VERSION "dbc-export 1 2025.20.8"

NS_ :

BS_:

BU_: ADSP APB APP APS APSB BB BMS CC CMP CMPD CP DAS DI DIF DIR DPB EPAS3P EPAS3S EPASTP EPASTS EPBL EPBR ESP EVSE FC GTW HCML HCMR HVP IBST ICR IDB LS OCS1P PARK PCS PM PMF PMR PNCD PTC RADC RCM RCM2 RCM3 RCU SCCM SCM SCS SDCR TAS TCU TPMS TRCM UI UIS UMC USM VC VCFRONT VCLEFT VCRIGHT VCSEC VEH

BO_ 548 PCS_dcdcStatus: 8 PCS
 SG_ PCS_dcdcPrechargeStatus : 0|2@1+ (1,0) [0|3] "" Vector__XXX
 SG_ PCS_dcdcLvSupportStatus : 2|2@1+ (1,0) [0|3] "" Vector__XXX
 SG_ PCS_dcdcHvBusDischargeStatus : 4|2@1+ (1,0) [0|3] "" Vector__XXX
 SG_ PCS_coldSleepAllowed : 8|1@1+ (1,0) [0|1] "" Vector__XXX
 SG_ PCS_dcdcPchgHVBusLowRDetected : 9|1@1+ (1,0) [0|1] "" Vector__XXX
 SG_ PCS_dcdcSubState : 10|5@1+ (1,0) [0|31] "" Vector__XXX
 SG_ PCS_dcdcFaulted : 15|1@1+ (1,0) [0|1] "" Vector__XXX
 SG_ PCS_okToBePowerCycled : 27|1@1+ (1,0) [0|1] "" Vector__XXX
 SG_ PCS_dcdcOutputIsLimited : 28|1@1+ (1,0) [0|1] "" Vector__XXX
 SG_ PCS_dcdcMaxOutputCurrentAllowed : 29|12@1+ (0.1,0) [0|400] "A" Vector__XXX
 SG_ PCS_dcdcPrechargeRtyCnt : 41|3@1+ (1,0) [0|7] "" Vector__XXX
 SG_ PCS_dcdcLvSupportRtyCnt : 44|4@1+ (1,0) [0|15] "" Vector__XXX
 SG_ PCS_dcdcDischargeRtyCnt : 48|4@1+ (1,0) [0|15] "" Vector__XXX
 SG_ PCS_dcdcPwmEnableLine : 52|1@1+ (1,0) [0|1] "" Vector__XXX
 SG_ PCS_dcdcSupportingFixedLvTarget : 53|1@1+ (1,0) [0|1] "" Vector__XXX
 SG_ PCS_ecuLogUploadRequest : 54|2@1+ (1,0) [0|3] "" Vector__XXX
 SG_ PCS_dcdcPrechargeRestartCnt : 56|3@1+ (1,0) [0|7] "" Vector__XXX
 SG_ PCS_dcdcInitialPrechargeSubState : 59|5@1+ (1,0) [0|31] "" Vector__XXX

BO_ 964 PCS_info: 8 PCS
 SG_ PCS_infoIndex M : 0|8@1+ (1,0) [0|255] "" Vector__XXX
 SG_ PCS_buildType m10 : 8|8@1+ (1,0) [0|255] "" Vector__XXX
 SG_ PCS_buildConfigId m10 : 16|16@1+ (1,0) [0|65535] "" Vector__XXX
 SG_ PCS_hardwareId m10 : 32|16@1+ (1,0) [0|65535] "" Vector__XXX
 SG_ PCS_componentId m10 : 48|16@1+ (1,0) [0|65535] "" Vector__XXX
 SG_ PCS_pcbaId m11 : 16|8@1+ (1,0) [0|255] "" Vector__XXX
 SG_ PCS_assemblyId m11 : 24|8@1+ (1,0) [0|255] "" Vector__XXX
 SG_ PCS_usageId m11 : 32|16@1+ (1,0) [0|65535] "" Vector__XXX
 SG_ PCS_subUsageId m11 : 48|16@1+ (1,0) [0|65535] "" Vector__XXX
 SG_ PCS_platformType m13 : 8|8@1+ (1,0) [0|255] "" Vector__XXX
 SG_ PCS_appCrc m13 : 32|32@1+ (1,0) [0|4294967295] "" Vector__XXX
 SG_ PCS_cpu2AppCrc m16 : 32|32@1+ (1,0) [0|4294967295] "" Vector__XXX
 SG_ PCS_appGitHash m17 : 8|56@1+ (1,0) [0|7.20575940379e+16] "" Vector__XXX
 SG_ PCS_bootGitHash m18 : 8|56@1+ (1,0) [0|7.20575940379e+16] "" Vector__XXX
 SG_ PCS_bootUdsProtoVersion m20 : 8|8@1+ (1,0) [0|255] "" Vector__XXX
 SG_ PCS_bootCrc m20 : 32|32@1+ (1,0) [0|4294967295] "" Vector__XXX

BO_ 708 PCS_logging: 8 PCS
 SG_ PCS_logMessageSelect M : 0|5@1+ (1,0) [0|31] "" Vector__XXX
 SG_ PCS_chgPhAInputIrms m0 : 5|9@1+ (0.1,0) [0|51.1] "A" Vector__XXX
 SG_ PCS_chgPhAIntBusV m0 : 14|9@1+ (1,0) [0|511] "V" Vector__XXX
 SG_ PCS_chgPhAIntBusVTarget m0 : 23|9@1+ (1,0) [0|511] "V" Vector__XXX
 SG_ PCS_chgPhAOutputI m0 : 32|8@1+ (0.1,0) [0|25.5] "A" Vector__XXX
 SG_ PCS_chgPhAInputCurrentLimitReaso m0 : 40|3@1+ (1,0) [0|7] "" Vector__XXX
 SG_ PCS_chgPhBInputIrms m1 : 5|9@1+ (0.1,0) [0|51.1] "A" Vector__XXX
 SG_ PCS_chgPhBIntBusV m1 : 14|9@1+ (1,0) [0|511] "V" Vector__XXX
 SG_ PCS_chgPhBIntBusVTarget m1 : 23|9@1+ (1,0) [0|511] "V" Vector__XXX
 SG_ PCS_chgPhBOutputI m1 : 32|8@1+ (0.1,0) [0|25.5] "A" Vector__XXX
 SG_ PCS_chgPhBInputCurrentLimitReaso m1 : 40|3@1+ (1,0) [0|7] "" Vector__XXX
 SG_ PCS_chgPhCInputIrms m2 : 5|9@1+ (0.1,0) [0|51.1] "A" Vector__XXX
 SG_ PCS_chgPhCIntBusV m2 : 14|9@1+ (1,0) [0|511] "V" Vector__XXX
 SG_ PCS_chgPhCIntBusVTarget m2 : 23|9@1+ (1,0) [0|511] "V" Vector__XXX
 SG_ PCS_chgPhCOutputI m2 : 32|8@1+ (0.1,0) [0|25.5] "A" Vector__XXX
 SG_ PCS_chgPhCInputCurrentLimitReaso m2 : 40|3@1+ (1,0) [0|7] "" Vector__XXX
 SG_ PCS_chgInputL1NVrms m3 : 5|12@1+ (0.2,0) [0|819] "V" Vector__XXX
 SG_ PCS_chgInputL2NVrms m3 : 17|12@1+ (0.2,0) [0|819] "V" Vector__XXX
 SG_ PCS_chgInputL3NVrms m3 : 29|12@1+ (0.2,0) [0|819] "V" Vector__XXX
 SG_ PCS_chgInputL1L2Vrms m3 : 41|12@1+ (0.2,0) [0|819] "V" Vector__XXX
 SG_ PCS_chgInputNGVrms m3 : 53|9@1+ (1,0) [0|511] "V" Vector__XXX
 SG_ PCS_chgInputFrequencyL1N m4 : 5|12@1+ (0.01,40) [40|80.95] "Hz" Vector__XXX
 SG_ PCS_chgInputFrequencyL2N m4 : 17|12@1+ (0.01,40) [40|80.95] "Hz" Vector__XXX
 SG_ PCS_chgInputFrequencyL3N m4 : 29|12@1+ (0.01,40) [40|80.95] "Hz" Vector__XXX
 SG_ PCS_chgInternalPhaseConfig m4 : 41|4@1+ (1,0) [0|15] "" Vector__XXX
 SG_ PCS_chgPhasesPriority m4 : 45|6@1+ (1,0) [0|63] "" Vector__XXX
 SG_ PCS_chgOutputV m4 : 51|12@1+ (0.146484375,0) [0|599.853515625] "V" Vector__XXX
 SG_ PCS_chgPhAState m5 : 5|4@1+ (1,0) [0|15] "" Vector__XXX
 SG_ PCS_chgPhBState m5 : 9|4@1+ (1,0) [0|15] "" Vector__XXX
 SG_ PCS_chgPhCState m5 : 13|4@1+ (1,0) [0|15] "" Vector__XXX
 SG_ PCS_chgPhALastShutdownReason m5 : 17|5@1+ (1,0) [0|31] "" Vector__XXX
 SG_ PCS_chgPhBLastShutdownReason m5 : 22|5@1+ (1,0) [0|31] "" Vector__XXX
 SG_ PCS_chgPhCLastShutdownReason m5 : 27|5@1+ (1,0) [0|31] "" Vector__XXX
 SG_ PCS_chgPhARetryCount m5 : 32|3@1+ (1,0) [0|7] "" Vector__XXX
 SG_ PCS_chgPhBRetryCount m5 : 35|3@1+ (1,0) [0|7] "" Vector__XXX
 SG_ PCS_chgPhCRetryCount m5 : 38|3@1+ (1,0) [0|7] "" Vector__XXX
 SG_ PCS_chgRetryCount m5 : 41|3@1+ (1,0) [0|7] "" Vector__XXX
 SG_ PCS_chgPhManCurrentToDist m5 : 44|10@1+ (0.1,0) [0|100] "A" Vector__XXX
 SG_ PCS_chgL1NPllLocked m5 : 54|1@1+ (1,0) [0|1] "" Vector__XXX
 SG_ PCS_chgL2NPllLocked m5 : 55|1@1+ (1,0) [0|1] "" Vector__XXX
 SG_ PCS_chgL3NPllLocked m5 : 56|1@1+ (1,0) [0|1] "" Vector__XXX
 SG_ PCS_chgL1L2PllLocked m5 : 57|1@1+ (1,0) [0|1] "" Vector__XXX
 SG_ PCS_chgNgPllLocked m5 : 58|1@1+ (1,0) [0|1] "" Vector__XXX
 SG_ PCS_chgPhManOptimalPhsToUse m5 : 59|2@1+ (1,0) [0|3] "" Vector__XXX
 SG_ PCS_chg5VL1Enable m5 : 61|1@1+ (1,0) [0|1] "" Vector__XXX
 SG_ PCS_dcdcMaxLvOutputCurrent m6 : 8|12@1+ (0.1,0) [0|400] "A" Vector__XXX
 SG_ PCS_dcdcCurrentLimit m6 : 20|12@1+ (0.1,0) [0|400] "A" Vector__XXX
 SG_ PCS_dcdcLvOutputCurrentTempLimit m6 : 32|12@1+ (0.1,0) [0|400] "A" Vector__XXX
 SG_ PCS_dcdcLvOutputCurrentFiltered m6 : 44|12@1+ (0.1,0) [0|400] "A" Vector__XXX
 SG_ PCS_dcdcUnifiedCommand m7 : 5|10@1+ (0.001,0) [0|1] "1" Vector__XXX
 SG_ PCS_dcdcCLAControllerOutput m7 : 16|10@1+ (0.001,0) [0|1] "1" Vector__XXX
 SG_ PCS_dcdcTankVoltage m7 : 26|11@1- (1,0) [-1024|1023] "V" Vector__XXX
 SG_ PCS_dcdcTankVoltageTarget m7 : 37|10@1+ (1,0) [0|1023] "V" Vector__XXX
 SG_ PCS_dcdcClaCurrentFreq m7 : 48|12@1+ (0.09765625,0) [0|399.9] "kHz" Vector__XXX
 SG_ PCS_dcdcTCommMeasured m8 : 5|16@1- (0.001953125,0) [-64|63.998] "us" Vector__XXX
 SG_ PCS_dcdcShortTimeUs m8 : 21|16@1+ (0.00048828125,0) [0|31.9995] "us" Vector__XXX
 SG_ PCS_dcdcHalfPeriodUs m8 : 37|16@1+ (0.00048828125,0) [0|31.9995] "us" Vector__XXX
 SG_ PCS_dcdcLvBusVoltTargetWithOffse m8 : 53|11@1+ (0.01,0) [0|20] "V" Vector__XXX
 SG_ PCS_cpu2BootState m9 : 5|2@1+ (1,0) [0|3] "" Vector__XXX
 SG_ PCS_acChargeSelfTestState m9 : 7|1@1+ (1,0) [0|1] "" Vector__XXX
 SG_ PCS_1V5Min10s m9 : 8|11@1+ (0.001,0) [0|2.047] "V" Vector__XXX
 SG_ PCS_1V5Max10s m9 : 19|11@1+ (0.001,0) [0|2.047] "V" Vector__XXX
 SG_ PCS_1V2Min10s m9 : 32|11@1+ (0.001,0) [0|2.047] "V" Vector__XXX
 SG_ PCS_1V2Max10s m9 : 43|11@1+ (0.001,0) [0|2.047] "V" Vector__XXX
 SG_ PCS_5VNMax10s m9 : 54|10@1+ (0.01,0) [0|10.23] "V" Vector__XXX
 SG_ PCS_chgPhAIntBusVMin10s m10 : 5|9@1+ (1,0) [0|511] "V" Vector__XXX
 SG_ PCS_chgPhAIntBusVMax10s m10 : 14|9@1+ (1,0) [0|511] "V" Vector__XXX
 SG_ PCS_chgPhAPchgVoltDeltaMax10s m10 : 23|8@1+ (0.5,0) [0|127.5] "V" Vector__XXX
 SG_ PCS_chgPhALifetimekWh m10 : 31|24@1+ (0.01,0) [0|167772.15] "kWh" Vector__XXX
 SG_ PCS_chgPhATransientRetryCount m10 : 55|9@1+ (0.1,0) [0|51.1] "-" Vector__XXX
 SG_ PCS_chgPhBIntBusVMin10s m11 : 5|9@1+ (1,0) [0|511] "V" Vector__XXX
 SG_ PCS_chgPhBIntBusVMax10s m11 : 14|9@1+ (1,0) [0|511] "V" Vector__XXX
 SG_ PCS_chgPhBPchgVoltDeltaMax10s m11 : 23|8@1+ (0.5,0) [0|127.5] "V" Vector__XXX
 SG_ PCS_chgPhBLifetimekWh m11 : 31|24@1+ (0.01,0) [0|167772.15] "kWh" Vector__XXX
 SG_ PCS_chgPhBTransientRetryCount m11 : 55|9@1+ (0.1,0) [0|51.1] "-" Vector__XXX
 SG_ PCS_chgPhCIntBusVMin10s m12 : 5|9@1+ (1,0) [0|511] "V" Vector__XXX
 SG_ PCS_chgPhCIntBusVMax10s m12 : 14|9@1+ (1,0) [0|511] "V" Vector__XXX
 SG_ PCS_chgPhCPchgVoltDeltaMax10s m12 : 23|8@1+ (0.5,0) [0|127.5] "V" Vector__XXX
 SG_ PCS_chgPhCLifetimekWh m12 : 31|24@1+ (0.01,0) [0|167772.15] "kWh" Vector__XXX
 SG_ PCS_chgPhCTransientRetryCount m12 : 55|9@1+ (0.1,0) [0|51.1] "-" Vector__XXX
 SG_ PCS_chgPhANoFlowBucket m20 : 5|9@1+ (0.01,0) [0|5.11] "-" Vector__XXX
 SG_ PCS_chgPhBNoFlowBucket m20 : 14|9@1+ (0.01,0) [0|5.11] "-" Vector__XXX
 SG_ PCS_chgPhCNoFlowBucket m20 : 23|9@1+ (0.01,0) [0|5.11] "-" Vector__XXX
 SG_ PCS_chgCurrentSensorOutOfBandUs m20 : 32|10@1+ (0.01,0) [0|10.23] "us" Vector__XXX
 SG_ PCS_chgAcpwHeartbeatState m20 : 42|3@1+ (1,0) [0|7] "" Vector__XXX
 SG_ PCS_chgKwhLostByFreqDroop m20 : 48|8@1+ (0.1,0) [0|25.5] "kWh" Vector__XXX
 SG_ PCS_chgReqKwhLostByFreqDroop m20 : 56|8@1+ (0.1,0) [0|25.5] "kWh" Vector__XXX
 SG_ PCS_dcdcLvSupportLifetimekWh m22 : 8|24@1+ (0.01,0) [0|167772.15] "kWh" Vector__XXX
 SG_ PCS_chgPwmEnableLineErrorCount m22 : 32|10@1+ (1,0) [0|1023] "" Vector__XXX
 SG_ PCS_dcdcPwmEnableLineErrorCount m22 : 42|10@1+ (1,0) [0|1023] "" Vector__XXX
 SG_ PCS_numAlertsSet m22 : 56|7@1+ (1,0) [0|127] "" Vector__XXX
 SG_ PCS_dcdcPchgStartLvBusVolt m24 : 5|10@1+ (0.0390625,0) [0|39.9609375] "V" Vector__XXX
 SG_ PCS_dcdcPchgStartHvBusVolt m24 : 16|12@1+ (0.146484375,0) [0|599.853515625] "V" Vector__XXX
 SG_ PCS_processorDieIdLot m26 : 8|24@1+ (1,0) [0|16777215] "" Vector__XXX
 SG_ PCS_processorDieIdWafer m26 : 32|8@1+ (1,0) [0|255] "" Vector__XXX
 SG_ PCS_processorDieIdX m26 : 40|12@1+ (1,0) [0|4095] "" Vector__XXX
 SG_ PCS_processorDieIdY m26 : 52|12@1+ (1,0) [0|4095] "" Vector__XXX

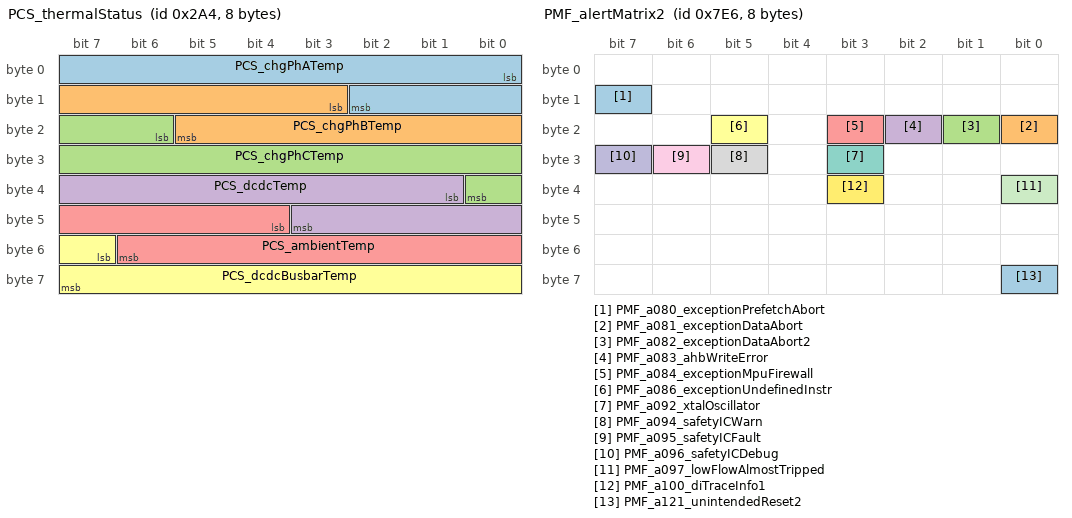
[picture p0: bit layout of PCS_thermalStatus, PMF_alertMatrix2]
BO_ 676 PCS_thermalStatus: 8 PCS
 SG_ PCS_chgPhATemp : 0|11@1- (0.1,40) [-62.4|142.3] "C" Vector__XXX
 SG_ PCS_chgPhBTemp : 11|11@1- (0.1,40) [-62.4|142.3] "C" Vector__XXX
 SG_ PCS_chgPhCTemp : 22|11@1- (0.1,40) [-62.4|142.3] "C" Vector__XXX
 SG_ PCS_dcdcTemp : 33|11@1- (0.1,40) [-62.4|142.3] "C" Vector__XXX
 SG_ PCS_ambientTemp : 44|11@1- (0.1,40) [-62.4|142.3] "C" Vector__XXX
 SG_ PCS_dcdcBusbarTemp : 55|9@1+ (0.2935421,0) [0|150] "C" Vector__XXX

BO_ 1317 PMF_alertLog: 8 PMF
 SG_ PMF_alertID M : 0|7@1+ (1,0) [0|127] "" Vector__XXX
 SG_ PMF_alertState : 15|1@1+ (1,0) [0|1] "" Vector__XXX
 SG_ PMF_a001_w0 m1 : 16|16@1+ (1,0) [0|65535] "" Vector__XXX
 SG_ PMF_a001_w1 m1 : 32|16@1+ (1,0) [0|65535] "" Vector__XXX
 SG_ PMF_a001_w2 m1 : 48|16@1+ (1,0) [0|65535] "" Vector__XXX
 SG_ PMF_a002_torqueAverage m2 : 16|1@1+ (1,0) [0|1] "" Vector__XXX
 SG_ PMF_a002_torqueWindow m2 : 17|1@1+ (1,0) [0|1] "" Vector__XXX
 SG_ PMF_a002_torqueMeasured m2 : 18|13@1- (2,0) [-8192|8190] "" Vector__XXX
 SG_ PMF_a002_torqueAccelAverage m2 : 32|13@1- (2,0) [-8192|8190] "" Vector__XXX
 SG_ PMF_a002_torqueAccelWindow m2 : 48|13@1- (2,0) [-8192|8190] "" Vector__XXX
 SG_ PMF_a003_reverseGear m3 : 16|1@1+ (1,0) [0|1] "" Vector__XXX
 SG_ PMF_a003_pedalPos m3 : 24|8@1+ (0.4,0) [0|102] "" Vector__XXX
 SG_ PMF_a003_zeroPointPedal m3 : 32|8@1+ (0.4,0) [0|102] "" Vector__XXX
 SG_ PMF_a004_torqueAverage m4 : 16|1@1+ (1,0) [0|1] "" Vector__XXX
 SG_ PMF_a004_torqueWindow m4 : 17|1@1+ (1,0) [0|1] "" Vector__XXX
 SG_ PMF_a004_torqueMeasured m4 : 18|13@1- (2,0) [-8192|8190] "" Vector__XXX
 SG_ PMF_a004_torqueDecelAverage m4 : 32|13@1- (2,0) [-8192|8190] "" Vector__XXX
 SG_ PMF_a004_torqueDecelWindow m4 : 48|13@1- (2,0) [-8192|8190] "" Vector__XXX
 SG_ PMF_a005_torqueReason m5 : 16|2@1+ (1,0) [0|3] "" Vector__XXX
 SG_ PMF_a005_torqueMeasured m5 : 18|13@1- (2,0) [-8192|8190] "" Vector__XXX
 SG_ PMF_a005_iDQmagnitude m5 : 32|16@1- (0.0939,0) [-3076.9152|3076.8213] "" Vector__XXX
 SG_ PMF_a006_torqueActual m6 : 16|13@1- (2,0) [-8192|8190] "" Vector__XXX
 SG_ PMF_a006_motorRPM m6 : 32|16@1- (1,0) [-32768|32767] "" Vector__XXX
 SG_ PMF_a006_torqueMeasured m6 : 48|13@1- (2,0) [-8192|8190] "" Vector__XXX
 SG_ PMF_a010_messageId m10 : 16|16@1+ (1,0) [0|65535] "" Vector__XXX
 SG_ PMF_a010_DI_status m10 : 32|1@1+ (1,0) [0|1] "" Vector__XXX
 SG_ PMF_a010_DI_torque m10 : 33|1@1+ (1,0) [0|1] "" Vector__XXX
 SG_ PMF_a010_DI_slaveCommand m10 : 34|1@1+ (1,0) [0|1] "" Vector__XXX
 SG_ PMF_a010_DI_locStatus m10 : 35|1@1+ (1,0) [0|1] "" Vector__XXX
 SG_ PMF_a010_DI_speed m10 : 36|1@1+ (1,0) [0|1] "" Vector__XXX
 SG_ PMF_a010_DI_systemStatus m10 : 37|1@1+ (1,0) [0|1] "" Vector__XXX
 SG_ PMF_a010_DI_chassisControl m10 : 38|1@1+ (1,0) [0|1] "" Vector__XXX
 SG_ PMF_a010_DI_chassisControl2 m10 : 39|1@1+ (1,0) [0|1] "" Vector__XXX
 SG_ PMF_a010_vdcLeft m10 : 40|1@1+ (1,0) [0|1] "" Vector__XXX
 SG_ PMF_a010_vdcRight m10 : 41|1@1+ (1,0) [0|1] "" Vector__XXX
 SG_ PMF_a010_DI_vehicleEstimates m10 : 42|1@1+ (1,0) [0|1] "" Vector__XXX
 SG_ PMF_a010_DI_brakeCommand m10 : 43|1@1+ (1,0) [0|1] "" Vector__XXX
 SG_ PMF_a010_DI_difCommand m10 : 44|1@1+ (1,0) [0|1] "" Vector__XXX
 SG_ PMF_a010_DI_dirCommand m10 : 45|1@1+ (1,0) [0|1] "" Vector__XXX
 SG_ PMF_a010_DI_dirVehicle m10 : 46|1@1+ (1,0) [0|1] "" Vector__XXX
 SG_ PMF_a010_DI_locStatus2 m10 : 47|1@1+ (1,0) [0|1] "" Vector__XXX
 SG_ PMF_a011_Ia m11 : 16|16@1- (0.0939,0) [-3076.9152|3076.8213] "" Vector__XXX
 SG_ PMF_a011_Ib m11 : 32|16@1- (0.0939,0) [-3076.9152|3076.8213] "" Vector__XXX
 SG_ PMF_a011_currentVref m11 : 48|11@1+ (0.005,0) [0|10.235] "" Vector__XXX
 SG_ PMF_a011_badPhaseAsample m11 : 59|1@1+ (1,0) [0|1] "" Vector__XXX
 SG_ PMF_a011_badPhaseBsample m11 : 60|1@1+ (1,0) [0|1] "" Vector__XXX
 SG_ PMF_a011_sampleFreeze m11 : 61|1@1+ (1,0) [0|1] "" Vector__XXX
 SG_ PMF_a012_canID m12 : 16|12@1+ (1,0) [0|4095] "" Vector__XXX
 SG_ PMF_a012_errorType m12 : 28|3@1+ (1,0) [0|7] "" Vector__XXX
 SG_ PMF_a012_badValue1 m12 : 32|16@1+ (1,0) [0|65535] "" Vector__XXX
 SG_ PMF_a012_badValue2 m12 : 48|16@1+ (1,0) [0|65535] "" Vector__XXX
 SG_ PMF_a013_mailboxID m13 : 16|16@1+ (1,0) [0|65535] "" Vector__XXX
 SG_ PMF_a013_canID m13 : 32|16@1+ (1,0) [0|65535] "" Vector__XXX
 SG_ PMF_a013_errorType m13 : 48|3@1+ (1,0) [0|7] "" Vector__XXX
 SG_ PMF_a017_EPBL_status m17 : 16|1@1+ (1,0) [0|1] "" Vector__XXX
 SG_ PMF_a017_EPBR_status m17 : 17|1@1+ (1,0) [0|1] "" Vector__XXX
 SG_ PMF_a018_w0 m18 : 16|16@1+ (1,0) [0|65535] "" Vector__XXX
 SG_ PMF_a018_w1 m18 : 32|16@1+ (1,0) [0|65535] "" Vector__XXX
 SG_ PMF_a018_w2 m18 : 48|16@1+ (1,0) [0|65535] "" Vector__XXX
 SG_ PMF_a019_statorTemp1 m19 : 16|16@1- (0.1,0) [-3276.8|3276.7] "" Vector__XXX
 SG_ PMF_a019_statorTslope1 m19 : 32|16@1- (0.1,0) [-3276.8|3276.7] "" Vector__XXX
 SG_ PMF_a025_sccReset m25 : 16|1@1+ (1,0) [0|1] "" Vector__XXX
 SG_ PMF_a025_hibernate m25 : 17|1@1+ (1,0) [0|1] "" Vector__XXX
 SG_ PMF_a025_hwBist m25 : 18|1@1+ (1,0) [0|1] "" Vector__XXX
 SG_ PMF_a025_nmiWatchdog m25 : 19|1@1+ (1,0) [0|1] "" Vector__XXX
 SG_ PMF_a025_watchdog m25 : 20|1@1+ (1,0) [0|1] "" Vector__XXX
 SG_ PMF_a025_clockFailNmi m25 : 21|1@1+ (1,0) [0|1] "" Vector__XXX
 SG_ PMF_a025_ramUncErrorNmi m25 : 22|1@1+ (1,0) [0|1] "" Vector__XXX
 SG_ PMF_a025_flashUncErrorNmi m25 : 23|1@1+ (1,0) [0|1] "" Vector__XXX
 SG_ PMF_a025_cpu1signMismatchNmi m25 : 24|1@1+ (1,0) [0|1] "" Vector__XXX
 SG_ PMF_a025_cpu2signMismatchNmi m25 : 25|1@1+ (1,0) [0|1] "" Vector__XXX
 SG_ PMF_a025_pieVectErrorNmi m25 : 26|1@1+ (1,0) [0|1] "" Vector__XXX
 SG_ PMF_a025_sysDbgNmi m25 : 27|1@1+ (1,0) [0|1] "" Vector__XXX
 SG_ PMF_a025_rlNmi m25 : 28|1@1+ (1,0) [0|1] "" Vector__XXX
 SG_ PMF_a025_ovfNmi m25 : 29|1@1+ (1,0) [0|1] "" Vector__XXX
 SG_ PMF_a025_possibleSafetyICReset m25 : 30|1@1+ (1,0) [0|1] "" Vector__XXX
 SG_ PMF_a025_powerOnReset m25 : 31|1@1+ (1,0) [0|1] "" Vector__XXX
 SG_ PMF_a025_watchdogTimer0 m25 : 32|1@1+ (1,0) [0|1] "" Vector__XXX
 SG_ PMF_a025_watchdogTimer1 m25 : 33|1@1+ (1,0) [0|1] "" Vector__XXX
 SG_ PMF_a025_watchdogTimer2 m25 : 34|1@1+ (1,0) [0|1] "" Vector__XXX
 SG_ PMF_a025_watchdogTimer3 m25 : 35|1@1+ (1,0) [0|1] "" Vector__XXX
 SG_ PMF_a025_warmResetReq m25 : 36|1@1+ (1,0) [0|1] "" Vector__XXX
 SG_ PMF_a025_externalPadReset m25 : 37|1@1+ (1,0) [0|1] "" Vector__XXX
 SG_ PMF_a025_hwSecModuleWatchdogTime m25 : 38|1@1+ (1,0) [0|1] "" Vector__XXX
 SG_ PMF_a025_debugReset m25 : 39|1@1+ (1,0) [0|1] "" Vector__XXX
 SG_ PMF_a025_tempSense0 m25 : 40|1@1+ (1,0) [0|1] "" Vector__XXX
 SG_ PMF_a025_tempSense1 m25 : 41|1@1+ (1,0) [0|1] "" Vector__XXX
 SG_ PMF_a026_reason m26 : 16|1@1+ (1,0) [0|1] "" Vector__XXX
 SG_ PMF_a026_isrCount20kHz m26 : 17|5@1+ (1,0) [0|31] "" Vector__XXX
 SG_ PMF_a026_isrCount1kHz m26 : 22|4@1+ (1,0) [0|15] "" Vector__XXX
 SG_ PMF_a026_switchingActive m26 : 26|1@1+ (1,0) [0|1] "" Vector__XXX
 SG_ PMF_a026_systemStackOvf m26 : 27|1@1+ (1,0) [0|1] "" Vector__XXX
 SG_ PMF_a026_controlStackOvf m26 : 28|1@1+ (1,0) [0|1] "" Vector__XXX
 SG_ PMF_a026_idleStackOvf m26 : 29|1@1+ (1,0) [0|1] "" Vector__XXX
 SG_ PMF_a026_eepStackOvf m26 : 30|1@1+ (1,0) [0|1] "" Vector__XXX
 SG_ PMF_a026_immStackOvf m26 : 31|1@1+ (1,0) [0|1] "" Vector__XXX
 SG_ PMF_a026_xdcErrorIdMSW m26 : 32|10@1+ (1,0) [0|1023] "" Vector__XXX
 SG_ PMF_a026_xdcErrorArg1 m26 : 42|22@1- (1,0) [-2097152|2097151] "" Vector__XXX
 SG_ PMF_a032_w0 m32 : 16|16@1+ (1,0) [0|65535] "" Vector__XXX
 SG_ PMF_a032_w1 m32 : 32|16@1+ (1,0) [0|65535] "" Vector__XXX
 SG_ PMF_a032_w2 m32 : 48|16@1+ (1,0) [0|65535] "" Vector__XXX
 SG_ PMF_a033_state m33 : 16|4@1+ (1,0) [0|15] "" Vector__XXX
 SG_ PMF_a033_failReason m33 : 20|3@1+ (1,0) [0|7] "" Vector__XXX
 SG_ PMF_a033_DSADC_Ia m33 : 24|16@1- (0.0939,0) [-3076.9152|3076.8213] "" Vector__XXX
 SG_ PMF_a033_DSADC_Ib m33 : 40|16@1- (0.0939,0) [-3076.9152|3076.8213] "" Vector__XXX
 SG_ PMF_a036_timeSinceTxHWI m36 : 16|6@1+ (64,0) [0|4032] "" Vector__XXX
 SG_ PMF_a036_timeSinceRxHWI m36 : 22|6@1+ (64,0) [0|4032] "" Vector__XXX
 SG_ PMF_a036_timeSince100HzTxSWI m36 : 28|6@1+ (0.32,0) [0|20.16] "" Vector__XXX
 SG_ PMF_a036_timeSince1kHzCLK m36 : 34|6@1+ (32,0) [0|2016] "" Vector__XXX
 SG_ PMF_a036_timeSince1kHzSWI m36 : 40|6@1+ (32,0) [0|2016] "" Vector__XXX
 SG_ PMF_a036_timeSinceIdle m36 : 46|6@1+ (0.16,0) [0|10.08] "" Vector__XXX
 SG_ PMF_a036_ovfStackId m36 : 52|4@1+ (1,0) [0|15] "" Vector__XXX
 SG_ PMF_a036_inTxISR m36 : 56|1@1+ (1,0) [0|1] "" Vector__XXX
 SG_ PMF_a036_inTxHWI m36 : 57|1@1+ (1,0) [0|1] "" Vector__XXX
 SG_ PMF_a036_inRxHWI m36 : 58|1@1+ (1,0) [0|1] "" Vector__XXX
 SG_ PMF_a036_in1kHzSWI m36 : 59|1@1+ (1,0) [0|1] "" Vector__XXX
 SG_ PMF_a036_in1kHzCLK m36 : 60|1@1+ (1,0) [0|1] "" Vector__XXX
 SG_ PMF_a036_in100HzCLK m36 : 61|1@1+ (1,0) [0|1] "" Vector__XXX
 SG_ PMF_a036_in10HzCLK m36 : 62|1@1+ (1,0) [0|1] "" Vector__XXX
 SG_ PMF_a036_in1HzCLK m36 : 63|1@1+ (1,0) [0|1] "" Vector__XXX
 SG_ PMF_a037_hvpFaults m37 : 16|1@1+ (1,0) [0|1] "" Vector__XXX
 SG_ PMF_a039_DIS_status m39 : 16|1@1+ (1,0) [0|1] "" Vector__XXX
 SG_ PMF_a039_DIS_torque m39 : 17|1@1+ (1,0) [0|1] "" Vector__XXX
 SG_ PMF_a039_messageId m39 : 24|16@1+ (1,0) [0|65535] "" Vector__XXX
 SG_ PMF_a040_PM_state m40 : 16|1@1+ (1,0) [0|1] "" Vector__XXX
 SG_ PMF_a040_messageId m40 : 24|16@1+ (1,0) [0|65535] "" Vector__XXX
 SG_ PMF_a040_PM_locState m40 : 40|1@1+ (1,0) [0|1] "" Vector__XXX
 SG_ PMF_a042_GTW_carConfig m42 : 16|1@1+ (1,0) [0|1] "" Vector__XXX
 SG_ PMF_a042_GTW_time m42 : 17|1@1+ (1,0) [0|1] "" Vector__XXX
 SG_ PMF_a042_GTW_drivetrainType m42 : 18|2@1+ (1,0) [0|3] "" Vector__XXX
 SG_ PMF_a042_expectedPerformanceCfg m42 : 20|2@1+ (1,0) [0|3] "" Vector__XXX
 SG_ PMF_a042_gearControl m42 : 22|1@1+ (1,0) [0|1] "" Vector__XXX
 SG_ PMF_a053_LVPowerState m53 : 16|1@1+ (1,0) [0|1] "" Vector__XXX
 SG_ PMF_a053_coolant m53 : 17|1@1+ (1,0) [0|1] "" Vector__XXX
 SG_ PMF_a053_vcleftSwitchStatus m53 : 18|1@1+ (1,0) [0|1] "" Vector__XXX
 SG_ PMF_a053_restraintStatus m53 : 19|1@1+ (1,0) [0|1] "" Vector__XXX
 SG_ PMF_a053_sensors m53 : 20|1@1+ (1,0) [0|1] "" Vector__XXX
 SG_ PMF_a054_uiPowertrainControl m54 : 16|1@1+ (1,0) [0|1] "" Vector__XXX
 SG_ PMF_a054_uiChassisControl m54 : 17|1@1+ (1,0) [0|1] "" Vector__XXX
 SG_ PMF_a054_uiCruiseControl m54 : 18|1@1+ (1,0) [0|1] "" Vector__XXX
 SG_ PMF_a054_uiTrackModeSettings m54 : 19|1@1+ (1,0) [0|1] "" Vector__XXX
 SG_ PMF_a054_uiTPMSRCPSetting m54 : 20|1@1+ (1,0) [0|1] "" Vector__XXX
 SG_ PMF_a055_motorRPM m55 : 16|16@1- (1,0) [-32768|32767] "" Vector__XXX
 SG_ PMF_a055_phaseAngle m55 : 32|8@1+ (0.00308,0) [0|0.7854] "" Vector__XXX
 SG_ PMF_a055_commonGain m55 : 40|8@1+ (0.02,0) [0|5.1] "" Vector__XXX
 SG_ PMF_a055_notReady m55 : 48|1@1+ (1,0) [0|1] "" Vector__XXX
 SG_ PMF_a055_noCarrier m55 : 49|1@1+ (1,0) [0|1] "" Vector__XXX
 SG_ PMF_a055_phaseOutOfSpec m55 : 50|1@1+ (1,0) [0|1] "" Vector__XXX
 SG_ PMF_a055_diElecAngleMismatch m55 : 51|1@1+ (1,0) [0|1] "" Vector__XXX
 SG_ PMF_a055_diSpeedMismatch m55 : 52|1@1+ (1,0) [0|1] "" Vector__XXX
 SG_ PMF_a055_claMIA m55 : 53|1@1+ (1,0) [0|1] "" Vector__XXX
 SG_ PMF_a055_diMIA m55 : 54|1@1+ (1,0) [0|1] "" Vector__XXX
 SG_ PMF_a055_diElecAngleMismatchWarn m55 : 55|1@1+ (1,0) [0|1] "" Vector__XXX
 SG_ PMF_a056_mailboxID m56 : 16|16@1+ (1,0) [0|65535] "" Vector__XXX
 SG_ PMF_a056_canID m56 : 32|16@1+ (1,0) [0|65535] "" Vector__XXX
 SG_ PMF_a056_errorType m56 : 48|3@1+ (1,0) [0|7] "" Vector__XXX
 SG_ PMF_a057_canID m57 : 16|12@1+ (1,0) [0|4095] "" Vector__XXX
 SG_ PMF_a057_errorType m57 : 28|3@1+ (1,0) [0|7] "" Vector__XXX
 SG_ PMF_a057_badValue1 m57 : 32|16@1+ (1,0) [0|65535] "" Vector__XXX
 SG_ PMF_a057_badValue2 m57 : 48|16@1+ (1,0) [0|65535] "" Vector__XXX
 SG_ PMF_a058_hvilCurrent m58 : 16|8@1+ (0.1,0) [0|25.5] "" Vector__XXX
 SG_ PMF_a061_diIpcVersion m61 : 16|8@1+ (1,0) [0|255] "" Vector__XXX
 SG_ PMF_a061_pmIpcVersion m61 : 24|8@1+ (1,0) [0|255] "" Vector__XXX
 SG_ PMF_a062_address m62 : 16|32@1+ (1,0) [0|4294967295] "" Vector__XXX
 SG_ PMF_a062_errorType m62 : 48|4@1+ (1,0) [0|15] "" Vector__XXX
 SG_ PMF_a064_interventionType m64 : 16|4@1+ (1,0) [0|15] "" Vector__XXX
 SG_ PMF_a064_torqueCmdState m64 : 20|4@1+ (1,0) [0|15] "" Vector__XXX
 SG_ PMF_a064_shortDetectedByDI m64 : 24|1@1+ (1,0) [0|1] "" Vector__XXX
 SG_ PMF_a064_UI_stoppingMode m64 : 25|2@1+ (1,0) [0|3] "" Vector__XXX
 SG_ PMF_a064_diCrsState m64 : 27|3@1+ (1,0) [0|7] "" Vector__XXX
 SG_ PMF_a064_pmCrsState m64 : 32|3@1+ (1,0) [0|7] "" Vector__XXX
 SG_ PMF_a082_faultAddress m82 : 16|32@1+ (1,0) [0|4294967295] "" Vector__XXX
 SG_ PMF_a082_isWriteNotRead m82 : 48|1@1+ (1,0) [0|1] "" Vector__XXX
 SG_ PMF_a084_faultAddress m84 : 16|32@1+ (1,0) [0|4294967295] "" Vector__XXX
 SG_ PMF_a084_firewallId m84 : 48|5@1+ (1,0) [0|31] "" Vector__XXX
 SG_ PMF_a084_privId m84 : 56|4@1+ (1,0) [0|15] "" Vector__XXX
 SG_ PMF_a084_ns m84 : 60|1@1+ (1,0) [0|1] "" Vector__XXX
 SG_ PMF_a084_faultType m84 : 61|3@1+ (1,0) [0|7] "" Vector__XXX
 SG_ PMF_a092_pllClockSource m92 : 16|2@1+ (1,0) [0|3] "" Vector__XXX
 SG_ PMF_a100_index1kHzPeriodic m100 : 16|8@1+ (1,0) [0|255] "" Vector__XXX
 SG_ PMF_a100_index100HzPeriodic m100 : 24|8@1+ (1,0) [0|255] "" Vector__XXX
 SG_ PMF_a100_index10HzPeriodic m100 : 32|8@1+ (1,0) [0|255] "" Vector__XXX
 SG_ PMF_a100_indexSWI m100 : 40|8@1+ (1,0) [0|255] "" Vector__XXX
 SG_ PMF_a100_eepEvent m100 : 48|8@1+ (1,0) [0|255] "" Vector__XXX
 SG_ PMF_a100_module500HzActive m100 : 56|1@1+ (1,0) [0|1] "" Vector__XXX
 SG_ PMF_a100_module50HzActive m100 : 57|1@1+ (1,0) [0|1] "" Vector__XXX
 SG_ PMF_a100_module1HzActive m100 : 58|1@1+ (1,0) [0|1] "" Vector__XXX
 SG_ PMF_a100_task10HzActive m100 : 59|1@1+ (1,0) [0|1] "" Vector__XXX
 SG_ PMF_a100_taskUdsActive m100 : 60|1@1+ (1,0) [0|1] "" Vector__XXX

BO_ 772 PMF_alertMatrix1: 8 PMF
 SG_ PMF_a001_absoluteTorque : 0|1@1+ (1,0) [0|1] "" Vector__XXX
 SG_ PMF_a002_excessiveAccelTorque : 1|1@1+ (1,0) [0|1] "" Vector__XXX
 SG_ PMF_a003_excessiveReversalTorque : 2|1@1+ (1,0) [0|1] "" Vector__XXX
 SG_ PMF_a004_excessiveDecelTorque : 3|1@1+ (1,0) [0|1] "" Vector__XXX
 SG_ PMF_a005_torqueInNeutralOrPark : 4|1@1+ (1,0) [0|1] "" Vector__XXX
 SG_ PMF_a006_underTorqueCheck : 5|1@1+ (1,0) [0|1] "" Vector__XXX
 SG_ PMF_a008_memoryError : 7|1@1+ (1,0) [0|1] "" Vector__XXX
 SG_ PMF_a010_diMIA : 9|1@1+ (1,0) [0|1] "" Vector__XXX
 SG_ PMF_a011_phaseCurrentIrrational : 10|1@1+ (1,0) [0|1] "" Vector__XXX
 SG_ PMF_a012_canDataBusA : 11|1@1+ (1,0) [0|1] "" Vector__XXX
 SG_ PMF_a013_canHardwareBusA : 12|1@1+ (1,0) [0|1] "" Vector__XXX
 SG_ PMF_a017_brakeMIA : 16|1@1+ (1,0) [0|1] "" Vector__XXX
 SG_ PMF_a018_encoderIrrational : 17|1@1+ (1,0) [0|1] "" Vector__XXX
 SG_ PMF_a019_statorTempIrrational : 18|1@1+ (1,0) [0|1] "" Vector__XXX
 SG_ PMF_a025_unintendedReset : 24|1@1+ (1,0) [0|1] "" Vector__XXX
 SG_ PMF_a026_diHeartBeatMIA : 25|1@1+ (1,0) [0|1] "" Vector__XXX
 SG_ PMF_a027_torqueEstimationOutOfBo : 26|1@1+ (1,0) [0|1] "" Vector__XXX
 SG_ PMF_a028_torqueCmdError : 27|1@1+ (1,0) [0|1] "" Vector__XXX
 SG_ PMF_a031_highStackUsage : 30|1@1+ (1,0) [0|1] "" Vector__XXX
 SG_ PMF_a032_registerConfigError : 31|1@1+ (1,0) [0|1] "" Vector__XXX
 SG_ PMF_a033_selfTest : 32|1@1+ (1,0) [0|1] "" Vector__XXX
 SG_ PMF_a034_trqCrossCheck : 33|1@1+ (1,0) [0|1] "" Vector__XXX
 SG_ PMF_a035_udsTransactionInitiated : 34|1@1+ (1,0) [0|1] "" Vector__XXX
 SG_ PMF_a036_preWatchdog : 35|1@1+ (1,0) [0|1] "" Vector__XXX
 SG_ PMF_a037_hvpMIA : 36|1@1+ (1,0) [0|1] "" Vector__XXX
 SG_ PMF_a039_disMIA : 38|1@1+ (1,0) [0|1] "" Vector__XXX
 SG_ PMF_a040_pmMIA : 39|1@1+ (1,0) [0|1] "" Vector__XXX
 SG_ PMF_a042_gtwMIA : 41|1@1+ (1,0) [0|1] "" Vector__XXX
 SG_ PMF_a045_motorMovementDetected : 44|1@1+ (1,0) [0|1] "" Vector__XXX
 SG_ PMF_a053_vcfrontMIA : 52|1@1+ (1,0) [0|1] "" Vector__XXX
 SG_ PMF_a054_uiMIA : 53|1@1+ (1,0) [0|1] "" Vector__XXX
 SG_ PMF_a055_resolver : 54|1@1+ (1,0) [0|1] "" Vector__XXX
 SG_ PMF_a056_canHardwareBusB : 55|1@1+ (1,0) [0|1] "" Vector__XXX
 SG_ PMF_a057_canDataBusB : 56|1@1+ (1,0) [0|1] "" Vector__XXX
 SG_ PMF_a058_measuredHvilCurrentFroz : 57|1@1+ (1,0) [0|1] "" Vector__XXX
 SG_ PMF_a061_DIPMVersionMismatch : 60|1@1+ (1,0) [0|1] "" Vector__XXX
 SG_ PMF_a062_eccError : 61|1@1+ (1,0) [0|1] "" Vector__XXX
 SG_ PMF_a064_torqueIntervention : 63|1@1+ (1,0) [0|1] "" Vector__XXX

BO_ 2022 PMF_alertMatrix2: 8 PMF
 SG_ PMF_a080_exceptionPrefetchAbort : 15|1@1+ (1,0) [0|1] "" Vector__XXX
 SG_ PMF_a081_exceptionDataAbort : 16|1@1+ (1,0) [0|1] "" Vector__XXX
 SG_ PMF_a082_exceptionDataAbort2 : 17|1@1+ (1,0) [0|1] "" Vector__XXX
 SG_ PMF_a083_ahbWriteError : 18|1@1+ (1,0) [0|1] "" Vector__XXX
 SG_ PMF_a084_exceptionMpuFirewall : 19|1@1+ (1,0) [0|1] "" Vector__XXX
 SG_ PMF_a086_exceptionUndefinedInstr : 21|1@1+ (1,0) [0|1] "" Vector__XXX
 SG_ PMF_a092_xtalOscillator : 27|1@1+ (1,0) [0|1] "" Vector__XXX
 SG_ PMF_a094_safetyICWarn : 29|1@1+ (1,0) [0|1] "" Vector__XXX
 SG_ PMF_a095_safetyICFault : 30|1@1+ (1,0) [0|1] "" Vector__XXX
 SG_ PMF_a096_safetyICDebug : 31|1@1+ (1,0) [0|1] "" Vector__XXX
 SG_ PMF_a097_lowFlowAlmostTripped : 32|1@1+ (1,0) [0|1] "" Vector__XXX
 SG_ PMF_a100_diTraceInfo1 : 35|1@1+ (1,0) [0|1] "" Vector__XXX
 SG_ PMF_a121_unintendedReset2 : 56|1@1+ (1,0) [0|1] "" Vector__XXX

BO_ 790 PMF_info: 8 PMF
 SG_ PMF_infoIndex M : 0|8@1+ (1,0) [0|255] "" Vector__XXX
 SG_ PMF_buildType m10 : 8|8@1+ (1,0) [0|255] "" Vector__XXX
 SG_ PMF_buildConfigurationId m10 : 16|16@1+ (1,0) [0|65535] "" Vector__XXX
 SG_ PMF_hardwareId m10 : 32|8@1+ (1,0) [0|252] "" Vector__XXX
 SG_ PMF_deviceFused m10 : 40|1@1+ (1,0) [0|1] "" Vector__XXX
 SG_ PMF_componentId m10 : 48|16@1+ (1,0) [0|65535] "" Vector__XXX
 SG_ PMF_pcbaId m11 : 16|8@1+ (1,0) [0|255] "" Vector__XXX
 SG_ PMF_assemblyId m11 : 24|8@1+ (1,0) [0|255] "" Vector__XXX
 SG_ PMF_usageId m11 : 32|16@1+ (1,0) [0|65535] "" Vector__XXX
 SG_ PMF_subUsageId m11 : 48|16@1+ (1,0) [0|65535] "" Vector__XXX
 SG_ PMF_applicationCrc m13 : 32|32@1+ (1,0) [0|4294967295] "" Vector__XXX
 SG_ PMF_appGitHash m17 : 8|56@1+ (1,0) [0|7.20575940379e+16] "" Vector__XXX
 SG_ PMF_bootGitHash m18 : 8|56@1+ (1,0) [0|7.20575940379e+16] "" Vector__XXX
 SG_ PMF_platformTyp m19 : 8|8@1+ (1,0) [0|255] "" Vector__XXX
 SG_ PMF_udsProtocolVersion m20 : 8|8@1+ (1,0) [0|255] "" Vector__XXX
 SG_ PMF_bootloaderCrc m20 : 32|32@1+ (1,0) [0|4294967295] "" Vector__XXX

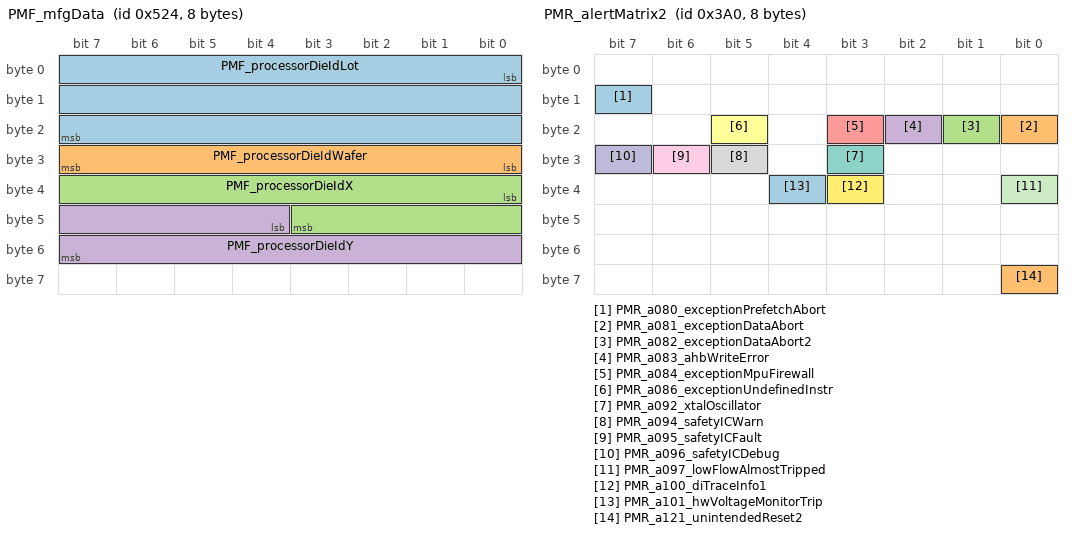
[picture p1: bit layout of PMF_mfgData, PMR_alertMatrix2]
BO_ 1316 PMF_mfgData: 8 PMF
 SG_ PMF_processorDieIdLot : 0|24@1+ (1,0) [0|16777215] "" Vector__XXX
 SG_ PMF_processorDieIdWafer : 24|8@1+ (1,0) [0|255] "" Vector__XXX
 SG_ PMF_processorDieIdX : 32|12@1+ (1,0) [0|4095] "" Vector__XXX
 SG_ PMF_processorDieIdY : 44|12@1+ (1,0) [0|4095] "" Vector__XXX

BO_ 1446 PMR_alertLog: 8 PMR
 SG_ PMR_alertID M : 0|7@1+ (1,0) [0|127] "" Vector__XXX
 SG_ PMR_alertState : 15|1@1+ (1,0) [0|1] "" Vector__XXX
 SG_ PMR_a001_w0 m1 : 16|16@1+ (1,0) [0|65535] "" Vector__XXX
 SG_ PMR_a001_w1 m1 : 32|16@1+ (1,0) [0|65535] "" Vector__XXX
 SG_ PMR_a001_w2 m1 : 48|16@1+ (1,0) [0|65535] "" Vector__XXX
 SG_ PMR_a002_torqueAverage m2 : 16|1@1+ (1,0) [0|1] "" Vector__XXX
 SG_ PMR_a002_torqueWindow m2 : 17|1@1+ (1,0) [0|1] "" Vector__XXX
 SG_ PMR_a002_torqueMeasured m2 : 18|13@1- (2,0) [-8192|8190] "" Vector__XXX
 SG_ PMR_a002_torqueAccelAverage m2 : 32|13@1- (2,0) [-8192|8190] "" Vector__XXX
 SG_ PMR_a002_torqueAccelWindow m2 : 48|13@1- (2,0) [-8192|8190] "" Vector__XXX
 SG_ PMR_a003_reverseGear m3 : 16|1@1+ (1,0) [0|1] "" Vector__XXX
 SG_ PMR_a003_pedalPos m3 : 24|8@1+ (0.4,0) [0|102] "" Vector__XXX
 SG_ PMR_a003_zeroPointPedal m3 : 32|8@1+ (0.4,0) [0|102] "" Vector__XXX
 SG_ PMR_a004_torqueAverage m4 : 16|1@1+ (1,0) [0|1] "" Vector__XXX
 SG_ PMR_a004_torqueWindow m4 : 17|1@1+ (1,0) [0|1] "" Vector__XXX
 SG_ PMR_a004_torqueMeasured m4 : 18|13@1- (2,0) [-8192|8190] "" Vector__XXX
 SG_ PMR_a004_torqueDecelAverage m4 : 32|13@1- (2,0) [-8192|8190] "" Vector__XXX
 SG_ PMR_a004_torqueDecelWindow m4 : 48|13@1- (2,0) [-8192|8190] "" Vector__XXX
 SG_ PMR_a005_torqueReason m5 : 16|2@1+ (1,0) [0|3] "" Vector__XXX
 SG_ PMR_a005_torqueMeasured m5 : 18|13@1- (2,0) [-8192|8190] "" Vector__XXX
 SG_ PMR_a005_iDQmagnitude m5 : 32|16@1- (0.0939,0) [-3076.9152|3076.8213] "" Vector__XXX
 SG_ PMR_a006_torqueActual m6 : 16|13@1- (2,0) [-8192|8190] "" Vector__XXX
 SG_ PMR_a006_motorRPM m6 : 32|16@1- (1,0) [-32768|32767] "" Vector__XXX
 SG_ PMR_a006_torqueMeasured m6 : 48|13@1- (2,0) [-8192|8190] "" Vector__XXX
 SG_ PMR_a010_messageId m10 : 16|16@1+ (1,0) [0|65535] "" Vector__XXX
 SG_ PMR_a010_DI_status m10 : 32|1@1+ (1,0) [0|1] "" Vector__XXX
 SG_ PMR_a010_DI_torque m10 : 33|1@1+ (1,0) [0|1] "" Vector__XXX
 SG_ PMR_a010_DI_slaveCommand m10 : 34|1@1+ (1,0) [0|1] "" Vector__XXX
 SG_ PMR_a010_DI_locStatus m10 : 35|1@1+ (1,0) [0|1] "" Vector__XXX
 SG_ PMR_a010_DI_speed m10 : 36|1@1+ (1,0) [0|1] "" Vector__XXX
 SG_ PMR_a010_DI_systemStatus m10 : 37|1@1+ (1,0) [0|1] "" Vector__XXX
 SG_ PMR_a010_DI_chassisControl m10 : 38|1@1+ (1,0) [0|1] "" Vector__XXX
 SG_ PMR_a010_DI_chassisControl2 m10 : 39|1@1+ (1,0) [0|1] "" Vector__XXX
 SG_ PMR_a010_vdcLeft m10 : 40|1@1+ (1,0) [0|1] "" Vector__XXX
 SG_ PMR_a010_vdcRight m10 : 41|1@1+ (1,0) [0|1] "" Vector__XXX
 SG_ PMR_a010_DI_vehicleEstimates m10 : 42|1@1+ (1,0) [0|1] "" Vector__XXX
 SG_ PMR_a010_DI_brakeCommand m10 : 43|1@1+ (1,0) [0|1] "" Vector__XXX
 SG_ PMR_a010_DI_difCommand m10 : 44|1@1+ (1,0) [0|1] "" Vector__XXX
 SG_ PMR_a010_DI_dirCommand m10 : 45|1@1+ (1,0) [0|1] "" Vector__XXX
 SG_ PMR_a010_DI_dirVehicle m10 : 46|1@1+ (1,0) [0|1] "" Vector__XXX
 SG_ PMR_a010_DI_locStatus2 m10 : 47|1@1+ (1,0) [0|1] "" Vector__XXX
 SG_ PMR_a011_Ia m11 : 16|16@1- (0.0939,0) [-3076.9152|3076.8213] "" Vector__XXX
 SG_ PMR_a011_Ib m11 : 32|16@1- (0.0939,0) [-3076.9152|3076.8213] "" Vector__XXX
 SG_ PMR_a011_currentVref m11 : 48|11@1+ (0.005,0) [0|10.235] "" Vector__XXX
 SG_ PMR_a011_badPhaseAsample m11 : 59|1@1+ (1,0) [0|1] "" Vector__XXX
 SG_ PMR_a011_badPhaseBsample m11 : 60|1@1+ (1,0) [0|1] "" Vector__XXX
 SG_ PMR_a011_sampleFreeze m11 : 61|1@1+ (1,0) [0|1] "" Vector__XXX
 SG_ PMR_a012_canID m12 : 16|12@1+ (1,0) [0|4095] "" Vector__XXX
 SG_ PMR_a012_errorType m12 : 28|3@1+ (1,0) [0|7] "" Vector__XXX
 SG_ PMR_a012_badValue1 m12 : 32|16@1+ (1,0) [0|65535] "" Vector__XXX
 SG_ PMR_a012_badValue2 m12 : 48|16@1+ (1,0) [0|65535] "" Vector__XXX
 SG_ PMR_a013_mailboxID m13 : 16|16@1+ (1,0) [0|65535] "" Vector__XXX
 SG_ PMR_a013_canID m13 : 32|16@1+ (1,0) [0|65535] "" Vector__XXX
 SG_ PMR_a013_errorType m13 : 48|3@1+ (1,0) [0|7] "" Vector__XXX
 SG_ PMR_a017_EPBL_status m17 : 16|1@1+ (1,0) [0|1] "" Vector__XXX
 SG_ PMR_a017_EPBR_status m17 : 17|1@1+ (1,0) [0|1] "" Vector__XXX
 SG_ PMR_a018_w0 m18 : 16|16@1+ (1,0) [0|65535] "" Vector__XXX
 SG_ PMR_a018_w1 m18 : 32|16@1+ (1,0) [0|65535] "" Vector__XXX
 SG_ PMR_a018_w2 m18 : 48|16@1+ (1,0) [0|65535] "" Vector__XXX
 SG_ PMR_a019_statorTemp1 m19 : 16|16@1- (0.1,0) [-3276.8|3276.7] "" Vector__XXX
 SG_ PMR_a019_statorTslope1 m19 : 32|16@1- (0.1,0) [-3276.8|3276.7] "" Vector__XXX
 SG_ PMR_a025_sccReset m25 : 16|1@1+ (1,0) [0|1] "" Vector__XXX
 SG_ PMR_a025_hibernate m25 : 17|1@1+ (1,0) [0|1] "" Vector__XXX
 SG_ PMR_a025_hwBist m25 : 18|1@1+ (1,0) [0|1] "" Vector__XXX
 SG_ PMR_a025_nmiWatchdog m25 : 19|1@1+ (1,0) [0|1] "" Vector__XXX
 SG_ PMR_a025_watchdog m25 : 20|1@1+ (1,0) [0|1] "" Vector__XXX
 SG_ PMR_a025_clockFailNmi m25 : 21|1@1+ (1,0) [0|1] "" Vector__XXX
 SG_ PMR_a025_ramUncErrorNmi m25 : 22|1@1+ (1,0) [0|1] "" Vector__XXX
 SG_ PMR_a025_flashUncErrorNmi m25 : 23|1@1+ (1,0) [0|1] "" Vector__XXX
 SG_ PMR_a025_cpu1signMismatchNmi m25 : 24|1@1+ (1,0) [0|1] "" Vector__XXX
 SG_ PMR_a025_cpu2signMismatchNmi m25 : 25|1@1+ (1,0) [0|1] "" Vector__XXX
 SG_ PMR_a025_pieVectErrorNmi m25 : 26|1@1+ (1,0) [0|1] "" Vector__XXX
 SG_ PMR_a025_sysDbgNmi m25 : 27|1@1+ (1,0) [0|1] "" Vector__XXX
 SG_ PMR_a025_rlNmi m25 : 28|1@1+ (1,0) [0|1] "" Vector__XXX
 SG_ PMR_a025_ovfNmi m25 : 29|1@1+ (1,0) [0|1] "" Vector__XXX
 SG_ PMR_a025_possibleSafetyICReset m25 : 30|1@1+ (1,0) [0|1] "" Vector__XXX
 SG_ PMR_a025_powerOnReset m25 : 31|1@1+ (1,0) [0|1] "" Vector__XXX
 SG_ PMR_a025_watchdogTimer0 m25 : 32|1@1+ (1,0) [0|1] "" Vector__XXX
 SG_ PMR_a025_watchdogTimer1 m25 : 33|1@1+ (1,0) [0|1] "" Vector__XXX
 SG_ PMR_a025_watchdogTimer2 m25 : 34|1@1+ (1,0) [0|1] "" Vector__XXX
 SG_ PMR_a025_watchdogTimer3 m25 : 35|1@1+ (1,0) [0|1] "" Vector__XXX
 SG_ PMR_a025_warmResetReq m25 : 36|1@1+ (1,0) [0|1] "" Vector__XXX
 SG_ PMR_a025_externalPadReset m25 : 37|1@1+ (1,0) [0|1] "" Vector__XXX
 SG_ PMR_a025_hwSecModuleWatchdogTime m25 : 38|1@1+ (1,0) [0|1] "" Vector__XXX
 SG_ PMR_a025_debugReset m25 : 39|1@1+ (1,0) [0|1] "" Vector__XXX
 SG_ PMR_a025_tempSense0 m25 : 40|1@1+ (1,0) [0|1] "" Vector__XXX
 SG_ PMR_a025_tempSense1 m25 : 41|1@1+ (1,0) [0|1] "" Vector__XXX
 SG_ PMR_a026_reason m26 : 16|1@1+ (1,0) [0|1] "" Vector__XXX
 SG_ PMR_a026_isrCount20kHz m26 : 17|5@1+ (1,0) [0|31] "" Vector__XXX
 SG_ PMR_a026_isrCount1kHz m26 : 22|4@1+ (1,0) [0|15] "" Vector__XXX
 SG_ PMR_a026_switchingActive m26 : 26|1@1+ (1,0) [0|1] "" Vector__XXX
 SG_ PMR_a026_systemStackOvf m26 : 27|1@1+ (1,0) [0|1] "" Vector__XXX
 SG_ PMR_a026_controlStackOvf m26 : 28|1@1+ (1,0) [0|1] "" Vector__XXX
 SG_ PMR_a026_idleStackOvf m26 : 29|1@1+ (1,0) [0|1] "" Vector__XXX
 SG_ PMR_a026_eepStackOvf m26 : 30|1@1+ (1,0) [0|1] "" Vector__XXX
 SG_ PMR_a026_immStackOvf m26 : 31|1@1+ (1,0) [0|1] "" Vector__XXX
 SG_ PMR_a026_xdcErrorIdMSW m26 : 32|10@1+ (1,0) [0|1023] "" Vector__XXX
 SG_ PMR_a026_xdcErrorArg1 m26 : 42|22@1- (1,0) [-2097152|2097151] "" Vector__XXX
 SG_ PMR_a032_w0 m32 : 16|16@1+ (1,0) [0|65535] "" Vector__XXX
 SG_ PMR_a032_w1 m32 : 32|16@1+ (1,0) [0|65535] "" Vector__XXX
 SG_ PMR_a032_w2 m32 : 48|16@1+ (1,0) [0|65535] "" Vector__XXX
 SG_ PMR_a033_state m33 : 16|4@1+ (1,0) [0|15] "" Vector__XXX
 SG_ PMR_a033_failReason m33 : 20|3@1+ (1,0) [0|7] "" Vector__XXX
 SG_ PMR_a033_DSADC_Ia m33 : 24|16@1- (0.0939,0) [-3076.9152|3076.8213] "" Vector__XXX
 SG_ PMR_a033_DSADC_Ib m33 : 40|16@1- (0.0939,0) [-3076.9152|3076.8213] "" Vector__XXX
 SG_ PMR_a036_timeSinceTxHWI m36 : 16|6@1+ (64,0) [0|4032] "" Vector__XXX
 SG_ PMR_a036_timeSinceRxHWI m36 : 22|6@1+ (64,0) [0|4032] "" Vector__XXX
 SG_ PMR_a036_timeSince100HzTxSWI m36 : 28|6@1+ (0.32,0) [0|20.16] "" Vector__XXX
 SG_ PMR_a036_timeSince1kHzCLK m36 : 34|6@1+ (32,0) [0|2016] "" Vector__XXX
 SG_ PMR_a036_timeSince1kHzSWI m36 : 40|6@1+ (32,0) [0|2016] "" Vector__XXX
 SG_ PMR_a036_timeSinceIdle m36 : 46|6@1+ (0.16,0) [0|10.08] "" Vector__XXX
 SG_ PMR_a036_ovfStackId m36 : 52|4@1+ (1,0) [0|15] "" Vector__XXX
 SG_ PMR_a036_inTxISR m36 : 56|1@1+ (1,0) [0|1] "" Vector__XXX
 SG_ PMR_a036_inTxHWI m36 : 57|1@1+ (1,0) [0|1] "" Vector__XXX
 SG_ PMR_a036_inRxHWI m36 : 58|1@1+ (1,0) [0|1] "" Vector__XXX
 SG_ PMR_a036_in1kHzSWI m36 : 59|1@1+ (1,0) [0|1] "" Vector__XXX
 SG_ PMR_a036_in1kHzCLK m36 : 60|1@1+ (1,0) [0|1] "" Vector__XXX
 SG_ PMR_a036_in100HzCLK m36 : 61|1@1+ (1,0) [0|1] "" Vector__XXX
 SG_ PMR_a036_in10HzCLK m36 : 62|1@1+ (1,0) [0|1] "" Vector__XXX
 SG_ PMR_a036_in1HzCLK m36 : 63|1@1+ (1,0) [0|1] "" Vector__XXX
 SG_ PMR_a037_hvpFaults m37 : 16|1@1+ (1,0) [0|1] "" Vector__XXX
 SG_ PMR_a039_DIS_status m39 : 16|1@1+ (1,0) [0|1] "" Vector__XXX
 SG_ PMR_a039_DIS_torque m39 : 17|1@1+ (1,0) [0|1] "" Vector__XXX
 SG_ PMR_a039_messageId m39 : 24|16@1+ (1,0) [0|65535] "" Vector__XXX
 SG_ PMR_a040_PM_state m40 : 16|1@1+ (1,0) [0|1] "" Vector__XXX
 SG_ PMR_a040_messageId m40 : 24|16@1+ (1,0) [0|65535] "" Vector__XXX
 SG_ PMR_a040_PM_locState m40 : 40|1@1+ (1,0) [0|1] "" Vector__XXX
 SG_ PMR_a042_GTW_carConfig m42 : 16|1@1+ (1,0) [0|1] "" Vector__XXX
 SG_ PMR_a042_GTW_time m42 : 17|1@1+ (1,0) [0|1] "" Vector__XXX
 SG_ PMR_a042_GTW_drivetrainType m42 : 18|2@1+ (1,0) [0|3] "" Vector__XXX
 SG_ PMR_a042_expectedPerformanceCfg m42 : 20|2@1+ (1,0) [0|3] "" Vector__XXX
 SG_ PMR_a042_gearControl m42 : 22|1@1+ (1,0) [0|1] "" Vector__XXX
 SG_ PMR_a053_LVPowerState m53 : 16|1@1+ (1,0) [0|1] "" Vector__XXX
 SG_ PMR_a053_coolant m53 : 17|1@1+ (1,0) [0|1] "" Vector__XXX
 SG_ PMR_a053_vcleftSwitchStatus m53 : 18|1@1+ (1,0) [0|1] "" Vector__XXX
 SG_ PMR_a053_restraintStatus m53 : 19|1@1+ (1,0) [0|1] "" Vector__XXX
 SG_ PMR_a053_sensors m53 : 20|1@1+ (1,0) [0|1] "" Vector__XXX
 SG_ PMR_a054_uiPowertrainControl m54 : 16|1@1+ (1,0) [0|1] "" Vector__XXX
 SG_ PMR_a054_uiChassisControl m54 : 17|1@1+ (1,0) [0|1] "" Vector__XXX
 SG_ PMR_a054_uiCruiseControl m54 : 18|1@1+ (1,0) [0|1] "" Vector__XXX
 SG_ PMR_a054_uiTrackModeSettings m54 : 19|1@1+ (1,0) [0|1] "" Vector__XXX
 SG_ PMR_a054_uiTPMSRCPSetting m54 : 20|1@1+ (1,0) [0|1] "" Vector__XXX
 SG_ PMR_a055_motorRPM m55 : 16|16@1- (1,0) [-32768|32767] "" Vector__XXX
 SG_ PMR_a055_phaseAngle m55 : 32|8@1+ (0.00308,0) [0|0.7854] "" Vector__XXX
 SG_ PMR_a055_commonGain m55 : 40|8@1+ (0.02,0) [0|5.1] "" Vector__XXX
 SG_ PMR_a055_notReady m55 : 48|1@1+ (1,0) [0|1] "" Vector__XXX
 SG_ PMR_a055_noCarrier m55 : 49|1@1+ (1,0) [0|1] "" Vector__XXX
 SG_ PMR_a055_phaseOutOfSpec m55 : 50|1@1+ (1,0) [0|1] "" Vector__XXX
 SG_ PMR_a055_diElecAngleMismatch m55 : 51|1@1+ (1,0) [0|1] "" Vector__XXX
 SG_ PMR_a055_diSpeedMismatch m55 : 52|1@1+ (1,0) [0|1] "" Vector__XXX
 SG_ PMR_a055_claMIA m55 : 53|1@1+ (1,0) [0|1] "" Vector__XXX
 SG_ PMR_a055_diMIA m55 : 54|1@1+ (1,0) [0|1] "" Vector__XXX
 SG_ PMR_a055_diElecAngleMismatchWarn m55 : 55|1@1+ (1,0) [0|1] "" Vector__XXX
 SG_ PMR_a056_mailboxID m56 : 16|16@1+ (1,0) [0|65535] "" Vector__XXX
 SG_ PMR_a056_canID m56 : 32|16@1+ (1,0) [0|65535] "" Vector__XXX
 SG_ PMR_a056_errorType m56 : 48|3@1+ (1,0) [0|7] "" Vector__XXX
 SG_ PMR_a057_canID m57 : 16|12@1+ (1,0) [0|4095] "" Vector__XXX
 SG_ PMR_a057_errorType m57 : 28|3@1+ (1,0) [0|7] "" Vector__XXX
 SG_ PMR_a057_badValue1 m57 : 32|16@1+ (1,0) [0|65535] "" Vector__XXX
 SG_ PMR_a057_badValue2 m57 : 48|16@1+ (1,0) [0|65535] "" Vector__XXX
 SG_ PMR_a058_hvilCurrent m58 : 16|8@1+ (0.1,0) [0|25.5] "" Vector__XXX
 SG_ PMR_a061_diIpcVersion m61 : 16|8@1+ (1,0) [0|255] "" Vector__XXX
 SG_ PMR_a061_pmIpcVersion m61 : 24|8@1+ (1,0) [0|255] "" Vector__XXX
 SG_ PMR_a062_address m62 : 16|32@1+ (1,0) [0|4294967295] "" Vector__XXX
 SG_ PMR_a062_errorType m62 : 48|4@1+ (1,0) [0|15] "" Vector__XXX
 SG_ PMR_a064_interventionType m64 : 16|4@1+ (1,0) [0|15] "" Vector__XXX
 SG_ PMR_a064_torqueCmdState m64 : 20|4@1+ (1,0) [0|15] "" Vector__XXX
 SG_ PMR_a064_shortDetectedByDI m64 : 24|1@1+ (1,0) [0|1] "" Vector__XXX
 SG_ PMR_a064_UI_stoppingMode m64 : 25|2@1+ (1,0) [0|3] "" Vector__XXX
 SG_ PMR_a064_diCrsState m64 : 27|3@1+ (1,0) [0|7] "" Vector__XXX
 SG_ PMR_a064_pmCrsState m64 : 32|3@1+ (1,0) [0|7] "" Vector__XXX
 SG_ PMR_a082_faultAddress m82 : 16|32@1+ (1,0) [0|4294967295] "" Vector__XXX
 SG_ PMR_a082_isWriteNotRead m82 : 48|1@1+ (1,0) [0|1] "" Vector__XXX
 SG_ PMR_a084_faultAddress m84 : 16|32@1+ (1,0) [0|4294967295] "" Vector__XXX
 SG_ PMR_a084_firewallId m84 : 48|5@1+ (1,0) [0|31] "" Vector__XXX
 SG_ PMR_a084_privId m84 : 56|4@1+ (1,0) [0|15] "" Vector__XXX
 SG_ PMR_a084_ns m84 : 60|1@1+ (1,0) [0|1] "" Vector__XXX
 SG_ PMR_a084_faultType m84 : 61|3@1+ (1,0) [0|7] "" Vector__XXX
 SG_ PMR_a092_pllClockSource m92 : 16|2@1+ (1,0) [0|3] "" Vector__XXX
 SG_ PMR_a100_index1kHzPeriodic m100 : 16|8@1+ (1,0) [0|255] "" Vector__XXX
 SG_ PMR_a100_index100HzPeriodic m100 : 24|8@1+ (1,0) [0|255] "" Vector__XXX
 SG_ PMR_a100_index10HzPeriodic m100 : 32|8@1+ (1,0) [0|255] "" Vector__XXX
 SG_ PMR_a100_indexSWI m100 : 40|8@1+ (1,0) [0|255] "" Vector__XXX
 SG_ PMR_a100_eepEvent m100 : 48|8@1+ (1,0) [0|255] "" Vector__XXX
 SG_ PMR_a100_module500HzActive m100 : 56|1@1+ (1,0) [0|1] "" Vector__XXX
 SG_ PMR_a100_module50HzActive m100 : 57|1@1+ (1,0) [0|1] "" Vector__XXX
 SG_ PMR_a100_module1HzActive m100 : 58|1@1+ (1,0) [0|1] "" Vector__XXX
 SG_ PMR_a100_task10HzActive m100 : 59|1@1+ (1,0) [0|1] "" Vector__XXX
 SG_ PMR_a100_taskUdsActive m100 : 60|1@1+ (1,0) [0|1] "" Vector__XXX
 SG_ PMR_a101_VDDA18_ref33_uv m101 : 16|1@1+ (1,0) [0|1] "" Vector__XXX
 SG_ PMR_a101_VBGAP09_ov m101 : 17|1@1+ (1,0) [0|1] "" Vector__XXX
 SG_ PMR_a101_VBGAP09_uv m101 : 18|1@1+ (1,0) [0|1] "" Vector__XXX
 SG_ PMR_a101_VDDA18_refBGAP_ov m101 : 19|1@1+ (1,0) [0|1] "" Vector__XXX
 SG_ PMR_a101_VDDA18_refBGAP_uv m101 : 20|1@1+ (1,0) [0|1] "" Vector__XXX
 SG_ PMR_a101_VDD12_ov m101 : 21|1@1+ (1,0) [0|1] "" Vector__XXX
 SG_ PMR_a101_VDD12_uv m101 : 22|1@1+ (1,0) [0|1] "" Vector__XXX
 SG_ PMR_a101_VDDSBIO_ov m101 : 23|1@1+ (1,0) [0|1] "" Vector__XXX
 SG_ PMR_a101_VDDSBIO_uv m101 : 24|1@1+ (1,0) [0|1] "" Vector__XXX
 SG_ PMR_a101_VSYS_MON_uv m101 : 25|1@1+ (1,0) [0|1] "" Vector__XXX
 SG_ PMR_a101_VDDA33_uv m101 : 26|1@1+ (1,0) [0|1] "" Vector__XXX
 SG_ PMR_a101_ADC0_REF_ov m101 : 27|1@1+ (1,0) [0|1] "" Vector__XXX
 SG_ PMR_a101_ADC0_REF_uv m101 : 28|1@1+ (1,0) [0|1] "" Vector__XXX
 SG_ PMR_a101_ADC12_REF_ov m101 : 29|1@1+ (1,0) [0|1] "" Vector__XXX
 SG_ PMR_a101_ADC12_REF_uv m101 : 30|1@1+ (1,0) [0|1] "" Vector__XXX
 SG_ PMR_a101_ADC34_REF_ov m101 : 31|1@1+ (1,0) [0|1] "" Vector__XXX
 SG_ PMR_a101_ADC34_REF_uv m101 : 32|1@1+ (1,0) [0|1] "" Vector__XXX
 SG_ PMR_a101_ADCR01_REF_ov m101 : 33|1@1+ (1,0) [0|1] "" Vector__XXX
 SG_ PMR_a101_ADCR01_REF_uv m101 : 34|1@1+ (1,0) [0|1] "" Vector__XXX

BO_ 902 PMR_alertMatrix1: 8 PMR
 SG_ PMR_a001_absoluteTorque : 0|1@1+ (1,0) [0|1] "" Vector__XXX
 SG_ PMR_a002_excessiveAccelTorque : 1|1@1+ (1,0) [0|1] "" Vector__XXX
 SG_ PMR_a003_excessiveReversalTorque : 2|1@1+ (1,0) [0|1] "" Vector__XXX
 SG_ PMR_a004_excessiveDecelTorque : 3|1@1+ (1,0) [0|1] "" Vector__XXX
 SG_ PMR_a005_torqueInNeutralOrPark : 4|1@1+ (1,0) [0|1] "" Vector__XXX
 SG_ PMR_a006_underTorqueCheck : 5|1@1+ (1,0) [0|1] "" Vector__XXX
 SG_ PMR_a008_memoryError : 7|1@1+ (1,0) [0|1] "" Vector__XXX
 SG_ PMR_a010_diMIA : 9|1@1+ (1,0) [0|1] "" Vector__XXX
 SG_ PMR_a011_phaseCurrentIrrational : 10|1@1+ (1,0) [0|1] "" Vector__XXX
 SG_ PMR_a012_canDataBusA : 11|1@1+ (1,0) [0|1] "" Vector__XXX
 SG_ PMR_a013_canHardwareBusA : 12|1@1+ (1,0) [0|1] "" Vector__XXX
 SG_ PMR_a017_brakeMIA : 16|1@1+ (1,0) [0|1] "" Vector__XXX
 SG_ PMR_a018_encoderIrrational : 17|1@1+ (1,0) [0|1] "" Vector__XXX
 SG_ PMR_a019_statorTempIrrational : 18|1@1+ (1,0) [0|1] "" Vector__XXX
 SG_ PMR_a025_unintendedReset : 24|1@1+ (1,0) [0|1] "" Vector__XXX
 SG_ PMR_a026_diHeartBeatMIA : 25|1@1+ (1,0) [0|1] "" Vector__XXX
 SG_ PMR_a027_torqueEstimationOutOfBo : 26|1@1+ (1,0) [0|1] "" Vector__XXX
 SG_ PMR_a028_torqueCmdError : 27|1@1+ (1,0) [0|1] "" Vector__XXX
 SG_ PMR_a031_highStackUsage : 30|1@1+ (1,0) [0|1] "" Vector__XXX
 SG_ PMR_a032_registerConfigError : 31|1@1+ (1,0) [0|1] "" Vector__XXX
 SG_ PMR_a033_selfTest : 32|1@1+ (1,0) [0|1] "" Vector__XXX
 SG_ PMR_a034_trqCrossCheck : 33|1@1+ (1,0) [0|1] "" Vector__XXX
 SG_ PMR_a035_udsTransactionInitiated : 34|1@1+ (1,0) [0|1] "" Vector__XXX
 SG_ PMR_a036_preWatchdog : 35|1@1+ (1,0) [0|1] "" Vector__XXX
 SG_ PMR_a037_hvpMIA : 36|1@1+ (1,0) [0|1] "" Vector__XXX
 SG_ PMR_a039_disMIA : 38|1@1+ (1,0) [0|1] "" Vector__XXX
 SG_ PMR_a040_pmMIA : 39|1@1+ (1,0) [0|1] "" Vector__XXX
 SG_ PMR_a042_gtwMIA : 41|1@1+ (1,0) [0|1] "" Vector__XXX
 SG_ PMR_a045_motorMovementDetected : 44|1@1+ (1,0) [0|1] "" Vector__XXX
 SG_ PMR_a053_vcfrontMIA : 52|1@1+ (1,0) [0|1] "" Vector__XXX
 SG_ PMR_a054_uiMIA : 53|1@1+ (1,0) [0|1] "" Vector__XXX
 SG_ PMR_a055_resolver : 54|1@1+ (1,0) [0|1] "" Vector__XXX
 SG_ PMR_a056_canHardwareBusB : 55|1@1+ (1,0) [0|1] "" Vector__XXX
 SG_ PMR_a057_canDataBusB : 56|1@1+ (1,0) [0|1] "" Vector__XXX
 SG_ PMR_a058_measuredHvilCurrentFroz : 57|1@1+ (1,0) [0|1] "" Vector__XXX
 SG_ PMR_a061_DIPMVersionMismatch : 60|1@1+ (1,0) [0|1] "" Vector__XXX
 SG_ PMR_a062_eccError : 61|1@1+ (1,0) [0|1] "" Vector__XXX
 SG_ PMR_a064_torqueIntervention : 63|1@1+ (1,0) [0|1] "" Vector__XXX

BO_ 928 PMR_alertMatrix2: 8 PMR
 SG_ PMR_a080_exceptionPrefetchAbort : 15|1@1+ (1,0) [0|1] "" Vector__XXX
 SG_ PMR_a081_exceptionDataAbort : 16|1@1+ (1,0) [0|1] "" Vector__XXX
 SG_ PMR_a082_exceptionDataAbort2 : 17|1@1+ (1,0) [0|1] "" Vector__XXX
 SG_ PMR_a083_ahbWriteError : 18|1@1+ (1,0) [0|1] "" Vector__XXX
 SG_ PMR_a084_exceptionMpuFirewall : 19|1@1+ (1,0) [0|1] "" Vector__XXX
 SG_ PMR_a086_exceptionUndefinedInstr : 21|1@1+ (1,0) [0|1] "" Vector__XXX
 SG_ PMR_a092_xtalOscillator : 27|1@1+ (1,0) [0|1] "" Vector__XXX
 SG_ PMR_a094_safetyICWarn : 29|1@1+ (1,0) [0|1] "" Vector__XXX
 SG_ PMR_a095_safetyICFault : 30|1@1+ (1,0) [0|1] "" Vector__XXX
 SG_ PMR_a096_safetyICDebug : 31|1@1+ (1,0) [0|1] "" Vector__XXX
 SG_ PMR_a097_lowFlowAlmostTripped : 32|1@1+ (1,0) [0|1] "" Vector__XXX
 SG_ PMR_a100_diTraceInfo1 : 35|1@1+ (1,0) [0|1] "" Vector__XXX
 SG_ PMR_a101_hwVoltageMonitorTrip : 36|1@1+ (1,0) [0|1] "" Vector__XXX
 SG_ PMR_a121_unintendedReset2 : 56|1@1+ (1,0) [0|1] "" Vector__XXX

BO_ 1748 PMR_info: 8 PMR
 SG_ PMR_infoIndex M : 0|8@1+ (1,0) [0|255] "" Vector__XXX
 SG_ PMR_buildType m10 : 8|8@1+ (1,0) [0|255] "" Vector__XXX
 SG_ PMR_buildConfigurationId m10 : 16|16@1+ (1,0) [0|65535] "" Vector__XXX
 SG_ PMR_hardwareId m10 : 32|8@1+ (1,0) [0|252] "" Vector__XXX
 SG_ PMR_deviceFused m10 : 40|1@1+ (1,0) [0|1] "" Vector__XXX
 SG_ PMR_componentId m10 : 48|16@1+ (1,0) [0|65535] "" Vector__XXX
 SG_ PMR_pcbaId m11 : 16|8@1+ (1,0) [0|255] "" Vector__XXX
 SG_ PMR_assemblyId m11 : 24|8@1+ (1,0) [0|255] "" Vector__XXX
 SG_ PMR_usageId m11 : 32|16@1+ (1,0) [0|65535] "" Vector__XXX
 SG_ PMR_subUsageId m11 : 48|16@1+ (1,0) [0|65535] "" Vector__XXX
 SG_ PMR_applicationCrc m13 : 32|32@1+ (1,0) [0|4294967295] "" Vector__XXX
 SG_ PMR_appGitHash m17 : 8|56@1+ (1,0) [0|7.20575940379e+16] "" Vector__XXX
 SG_ PMR_bootGitHash m18 : 8|56@1+ (1,0) [0|7.20575940379e+16] "" Vector__XXX
 SG_ PMR_platformTyp m19 : 8|8@1+ (1,0) [0|255] "" Vector__XXX
 SG_ PMR_udsProtocolVersion m20 : 8|8@1+ (1,0) [0|255] "" Vector__XXX
 SG_ PMR_bootloaderCrc m20 : 32|32@1+ (1,0) [0|4294967295] "" Vector__XXX

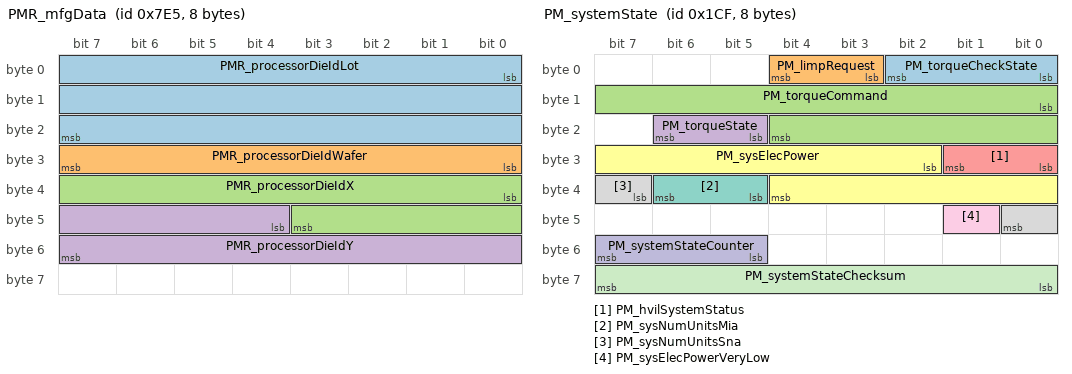
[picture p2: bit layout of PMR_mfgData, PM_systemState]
BO_ 2021 PMR_mfgData: 8 PMR
 SG_ PMR_processorDieIdLot : 0|24@1+ (1,0) [0|16777215] "" Vector__XXX
 SG_ PMR_processorDieIdWafer : 24|8@1+ (1,0) [0|255] "" Vector__XXX
 SG_ PMR_processorDieIdX : 32|12@1+ (1,0) [0|4095] "" Vector__XXX
 SG_ PMR_processorDieIdY : 44|12@1+ (1,0) [0|4095] "" Vector__XXX

BO_ 1444 PM_alertLog: 8 PM
 SG_ PM_alertID M : 0|7@1+ (1,0) [0|127] "" Vector__XXX
 SG_ PM_alertState : 15|1@1+ (1,0) [0|1] "" Vector__XXX
 SG_ PM_a001_w0 m1 : 16|16@1+ (1,0) [0|65535] "" Vector__XXX
 SG_ PM_a001_w1 m1 : 32|16@1+ (1,0) [0|65535] "" Vector__XXX
 SG_ PM_a001_w2 m1 : 48|16@1+ (1,0) [0|65535] "" Vector__XXX
 SG_ PM_a002_torqueAverage m2 : 16|1@1+ (1,0) [0|1] "" Vector__XXX
 SG_ PM_a002_torqueWindow m2 : 17|1@1+ (1,0) [0|1] "" Vector__XXX
 SG_ PM_a002_torqueMeasured m2 : 18|13@1- (2,0) [-8192|8190] "" Vector__XXX
 SG_ PM_a002_torqueAccelAverage m2 : 32|13@1- (2,0) [-8192|8190] "" Vector__XXX
 SG_ PM_a002_torqueAccelWindow m2 : 48|13@1- (2,0) [-8192|8190] "" Vector__XXX
 SG_ PM_a003_reverseGear m3 : 16|1@1+ (1,0) [0|1] "" Vector__XXX
 SG_ PM_a003_pedalPos m3 : 24|8@1+ (0.4,0) [0|102] "" Vector__XXX
 SG_ PM_a003_zeroPointPedal m3 : 32|8@1+ (0.4,0) [0|102] "" Vector__XXX
 SG_ PM_a004_torqueAverage m4 : 16|1@1+ (1,0) [0|1] "" Vector__XXX
 SG_ PM_a004_torqueWindow m4 : 17|1@1+ (1,0) [0|1] "" Vector__XXX
 SG_ PM_a004_torqueMeasured m4 : 18|13@1- (2,0) [-8192|8190] "" Vector__XXX
 SG_ PM_a004_torqueDecelAverage m4 : 32|13@1- (2,0) [-8192|8190] "" Vector__XXX
 SG_ PM_a004_torqueDecelWindow m4 : 48|13@1- (2,0) [-8192|8190] "" Vector__XXX
 SG_ PM_a005_torqueReason m5 : 16|2@1+ (1,0) [0|3] "" Vector__XXX
 SG_ PM_a005_torqueMeasured m5 : 18|13@1- (2,0) [-8192|8190] "" Vector__XXX
 SG_ PM_a005_iDQmagnitude m5 : 32|16@1- (0.0939,0) [-3076.9152|3076.8213] "" Vector__XXX
 SG_ PM_a006_unknownGearAllowed m6 : 16|1@1+ (1,0) [0|1] "" Vector__XXX
 SG_ PM_a006_parkGearAllowed m6 : 17|1@1+ (1,0) [0|1] "" Vector__XXX
 SG_ PM_a006_reverseGearAllowed m6 : 18|1@1+ (1,0) [0|1] "" Vector__XXX
 SG_ PM_a006_neutralGearAllowed m6 : 19|1@1+ (1,0) [0|1] "" Vector__XXX
 SG_ PM_a006_driveGearAllowed m6 : 20|1@1+ (1,0) [0|1] "" Vector__XXX
 SG_ PM_a006_shiftState m6 : 21|3@1+ (1,0) [0|7] "" Vector__XXX
 SG_ PM_a006_brakePedalPress m6 : 24|1@1+ (1,0) [0|1] "" Vector__XXX
 SG_ PM_a006_accelPedalBelowLimit m6 : 25|1@1+ (1,0) [0|1] "" Vector__XXX
 SG_ PM_a006_allowReverseShiftSpeed m6 : 26|1@1+ (1,0) [0|1] "" Vector__XXX
 SG_ PM_a006_allowDriveShiftSpeed m6 : 27|1@1+ (1,0) [0|1] "" Vector__XXX
 SG_ PM_a006_requireAccelPedalCheckSp m6 : 28|1@1+ (1,0) [0|1] "" Vector__XXX
 SG_ PM_a006_requireParkSpeed m6 : 29|1@1+ (1,0) [0|1] "" Vector__XXX
 SG_ PM_a006_stalkCommandP m6 : 30|1@1+ (1,0) [0|1] "" Vector__XXX
 SG_ PM_a006_stalkCommandR m6 : 31|1@1+ (1,0) [0|1] "" Vector__XXX
 SG_ PM_a006_stalkCommandN m6 : 32|1@1+ (1,0) [0|1] "" Vector__XXX
 SG_ PM_a006_stalkCommandD m6 : 33|1@1+ (1,0) [0|1] "" Vector__XXX
 SG_ PM_a006_unsecuredNeutralRequest m6 : 34|1@1+ (1,0) [0|1] "" Vector__XXX
 SG_ PM_a006_recentGearChange m6 : 35|1@1+ (1,0) [0|1] "" Vector__XXX
 SG_ PM_a006_smartShiftCommandD m6 : 36|1@1+ (1,0) [0|1] "" Vector__XXX
 SG_ PM_a006_smartShiftCommandR m6 : 37|1@1+ (1,0) [0|1] "" Vector__XXX
 SG_ PM_a006_driverSeatbeltBuckled m6 : 38|1@1+ (1,0) [0|1] "" Vector__XXX
 SG_ PM_a006_secGearSelRisingEdgeR m6 : 39|1@1+ (1,0) [0|1] "" Vector__XXX
 SG_ PM_a006_secGearSelRisingEdgeN m6 : 40|1@1+ (1,0) [0|1] "" Vector__XXX
 SG_ PM_a006_secGearSelRisingEdgeD m6 : 41|1@1+ (1,0) [0|1] "" Vector__XXX
 SG_ PM_a007_IBST_party1 m7 : 16|1@1+ (1,0) [0|1] "" Vector__XXX
 SG_ PM_a007_BUS1_IBST_status m7 : 17|1@1+ (1,0) [0|1] "" Vector__XXX
 SG_ PM_a007_BUS2_IBST_status m7 : 18|1@1+ (1,0) [0|1] "" Vector__XXX
 SG_ PM_a009_ESP_brakeTorque m9 : 16|1@1+ (1,0) [0|1] "" Vector__XXX
 SG_ PM_a009_ESP_motorLimits m9 : 17|1@1+ (1,0) [0|1] "" Vector__XXX
 SG_ PM_a009_ESP_offsets m9 : 18|1@1+ (1,0) [0|1] "" Vector__XXX
 SG_ PM_a009_ESP_party3 m9 : 19|1@1+ (1,0) [0|1] "" Vector__XXX
 SG_ PM_a009_ESP_status m9 : 20|1@1+ (1,0) [0|1] "" Vector__XXX
 SG_ PM_a009_ESP_wheelSpeeds m9 : 21|1@1+ (1,0) [0|1] "" Vector__XXX
 SG_ PM_a010_messageId m10 : 16|16@1+ (1,0) [0|65535] "" Vector__XXX
 SG_ PM_a010_DI_status m10 : 32|1@1+ (1,0) [0|1] "" Vector__XXX
 SG_ PM_a010_DI_torque m10 : 33|1@1+ (1,0) [0|1] "" Vector__XXX
 SG_ PM_a010_DI_slaveCommand m10 : 34|1@1+ (1,0) [0|1] "" Vector__XXX
 SG_ PM_a010_DI_locStatus m10 : 35|1@1+ (1,0) [0|1] "" Vector__XXX
 SG_ PM_a010_DI_speed m10 : 36|1@1+ (1,0) [0|1] "" Vector__XXX
 SG_ PM_a010_DI_systemStatus m10 : 37|1@1+ (1,0) [0|1] "" Vector__XXX
 SG_ PM_a010_DI_chassisControl m10 : 38|1@1+ (1,0) [0|1] "" Vector__XXX
 SG_ PM_a010_DI_chassisControl2 m10 : 39|1@1+ (1,0) [0|1] "" Vector__XXX
 SG_ PM_a010_vdcLeft m10 : 40|1@1+ (1,0) [0|1] "" Vector__XXX
 SG_ PM_a010_vdcRight m10 : 41|1@1+ (1,0) [0|1] "" Vector__XXX
 SG_ PM_a010_DI_vehicleEstimates m10 : 42|1@1+ (1,0) [0|1] "" Vector__XXX
 SG_ PM_a010_DI_brakeCommand m10 : 43|1@1+ (1,0) [0|1] "" Vector__XXX
 SG_ PM_a010_DI_difCommand m10 : 44|1@1+ (1,0) [0|1] "" Vector__XXX
 SG_ PM_a010_DI_dirCommand m10 : 45|1@1+ (1,0) [0|1] "" Vector__XXX
 SG_ PM_a010_DI_dirVehicle m10 : 46|1@1+ (1,0) [0|1] "" Vector__XXX
 SG_ PM_a010_DI_locStatus2 m10 : 47|1@1+ (1,0) [0|1] "" Vector__XXX
 SG_ PM_a010_stalklessInterfaces m10 : 48|1@1+ (1,0) [0|1] "" Vector__XXX
 SG_ PM_a011_pmfHvilStatus m11 : 16|2@1+ (1,0) [0|3] "" Vector__XXX
 SG_ PM_a011_pmfStatusValid m11 : 18|1@1+ (1,0) [0|1] "" Vector__XXX
 SG_ PM_a011_pmrHvilStatus m11 : 19|2@1+ (1,0) [0|3] "" Vector__XXX
 SG_ PM_a011_pmrStatusValid m11 : 21|1@1+ (1,0) [0|1] "" Vector__XXX
 SG_ PM_a011_vehiclePowerState m11 : 22|2@1+ (1,0) [0|3] "" Vector__XXX
 SG_ PM_a011_hvilSystemStatus m11 : 24|2@1+ (1,0) [0|3] "" Vector__XXX
 SG_ PM_a012_canID m12 : 16|12@1+ (1,0) [0|4095] "" Vector__XXX
 SG_ PM_a012_errorType m12 : 28|3@1+ (1,0) [0|7] "" Vector__XXX
 SG_ PM_a012_badValue1 m12 : 32|16@1+ (1,0) [0|65535] "" Vector__XXX
 SG_ PM_a012_badValue2 m12 : 48|16@1+ (1,0) [0|65535] "" Vector__XXX
 SG_ PM_a013_mailboxID m13 : 16|16@1+ (1,0) [0|65535] "" Vector__XXX
 SG_ PM_a013_canID m13 : 32|16@1+ (1,0) [0|65535] "" Vector__XXX
 SG_ PM_a013_errorType m13 : 48|3@1+ (1,0) [0|7] "" Vector__XXX
 SG_ PM_a014_track1Voltage m14 : 16|16@1+ (0.001,0) [0|65.535] "" Vector__XXX
 SG_ PM_a014_track2Voltage m14 : 32|16@1+ (0.001,0) [0|65.535] "" Vector__XXX
 SG_ PM_a014_accelErrorType m14 : 48|2@1+ (1,0) [0|3] "" Vector__XXX
 SG_ PM_a015_SCCM_rightStalk m15 : 16|1@1+ (1,0) [0|1] "" Vector__XXX
 SG_ PM_a016_BB_status m16 : 16|1@1+ (1,0) [0|1] "" Vector__XXX
 SG_ PM_a016_BB_brakeActuation m16 : 17|1@1+ (1,0) [0|1] "" Vector__XXX
 SG_ PM_a017_EPBL_status m17 : 16|1@1+ (1,0) [0|1] "" Vector__XXX
 SG_ PM_a017_EPBR_status m17 : 17|1@1+ (1,0) [0|1] "" Vector__XXX
 SG_ PM_a021_torque m21 : 16|1@1+ (1,0) [0|1] "" Vector__XXX
 SG_ PM_a021_capability m21 : 17|1@1+ (1,0) [0|1] "" Vector__XXX
 SG_ PM_a021_status m21 : 18|1@1+ (1,0) [0|1] "" Vector__XXX
 SG_ PM_a021_capability2 m21 : 19|1@1+ (1,0) [0|1] "" Vector__XXX
 SG_ PM_a021_power m21 : 20|1@1+ (1,0) [0|1] "" Vector__XXX
 SG_ PM_a022_torque m22 : 16|1@1+ (1,0) [0|1] "" Vector__XXX
 SG_ PM_a022_capability m22 : 17|1@1+ (1,0) [0|1] "" Vector__XXX
 SG_ PM_a022_status m22 : 18|1@1+ (1,0) [0|1] "" Vector__XXX
 SG_ PM_a022_capability2 m22 : 19|1@1+ (1,0) [0|1] "" Vector__XXX
 SG_ PM_a022_power m22 : 20|1@1+ (1,0) [0|1] "" Vector__XXX
 SG_ PM_a023_diCrsState m23 : 16|3@1+ (1,0) [0|7] "" Vector__XXX
 SG_ PM_a023_pmCrsState m23 : 19|3@1+ (1,0) [0|7] "" Vector__XXX
 SG_ PM_a023_crsFaultReason m23 : 24|5@1+ (1,0) [0|31] "" Vector__XXX
 SG_ PM_a023_crsCancelReason m23 : 29|4@1+ (1,0) [0|15] "" Vector__XXX
 SG_ PM_a023_cruiseTorquePed m23 : 33|11@1- (1,0) [-1024|1023] "" Vector__XXX
 SG_ PM_a023_wheelSpdEstimateAbs m23 : 44|10@1+ (0.25,0) [0|255.75] "" Vector__XXX
 SG_ PM_a023_accelEstimateDis m23 : 54|10@1- (0.05,-4.7) [-30.3|20.85] "" Vector__XXX
 SG_ PM_a025_powerOnReset m25 : 16|1@1+ (1,0) [0|1] "" Vector__XXX
 SG_ PM_a025_watchdogTimer0 m25 : 17|1@1+ (1,0) [0|1] "" Vector__XXX
 SG_ PM_a025_watchdogTimer1 m25 : 18|1@1+ (1,0) [0|1] "" Vector__XXX
 SG_ PM_a025_watchdogTimer2 m25 : 19|1@1+ (1,0) [0|1] "" Vector__XXX
 SG_ PM_a025_watchdogTimer3 m25 : 20|1@1+ (1,0) [0|1] "" Vector__XXX
 SG_ PM_a025_warmResetReq m25 : 21|1@1+ (1,0) [0|1] "" Vector__XXX
 SG_ PM_a025_externalPadReset m25 : 22|1@1+ (1,0) [0|1] "" Vector__XXX
 SG_ PM_a025_hwSecModuleWatchdogTimer m25 : 23|1@1+ (1,0) [0|1] "" Vector__XXX
 SG_ PM_a025_debugReset m25 : 24|1@1+ (1,0) [0|1] "" Vector__XXX
 SG_ PM_a025_tempSense0 m25 : 25|1@1+ (1,0) [0|1] "" Vector__XXX
 SG_ PM_a025_tempSense1 m25 : 26|1@1+ (1,0) [0|1] "" Vector__XXX
 SG_ PM_a026_reason m26 : 16|1@1+ (1,0) [0|1] "" Vector__XXX
 SG_ PM_a026_isrCount20kHz m26 : 17|5@1+ (1,0) [0|31] "" Vector__XXX
 SG_ PM_a026_isrCount1kHz m26 : 22|4@1+ (1,0) [0|15] "" Vector__XXX
 SG_ PM_a026_switchingActive m26 : 26|1@1+ (1,0) [0|1] "" Vector__XXX
 SG_ PM_a026_systemStackOvf m26 : 27|1@1+ (1,0) [0|1] "" Vector__XXX
 SG_ PM_a026_controlStackOvf m26 : 28|1@1+ (1,0) [0|1] "" Vector__XXX
 SG_ PM_a026_idleStackOvf m26 : 29|1@1+ (1,0) [0|1] "" Vector__XXX
 SG_ PM_a026_eepStackOvf m26 : 30|1@1+ (1,0) [0|1] "" Vector__XXX
 SG_ PM_a026_immStackOvf m26 : 31|1@1+ (1,0) [0|1] "" Vector__XXX
 SG_ PM_a026_xdcErrorIdMSW m26 : 32|10@1+ (1,0) [0|1023] "" Vector__XXX
 SG_ PM_a026_xdcErrorArg1 m26 : 42|22@1- (1,0) [-2097152|2097151] "" Vector__XXX
 SG_ PM_a030_diAebState m30 : 16|3@1+ (1,0) [0|7] "" Vector__XXX
 SG_ PM_a030_pmAebState m30 : 19|3@1+ (1,0) [0|7] "" Vector__XXX
 SG_ PM_a030_dasAebEvent m30 : 22|2@1+ (1,0) [0|3] "" Vector__XXX
 SG_ PM_a030_aebFaultReason m30 : 24|3@1+ (1,0) [0|7] "" Vector__XXX
 SG_ PM_a030_aebUnavailableReason m30 : 27|4@1+ (1,0) [0|15] "" Vector__XXX
 SG_ PM_a030_aebCancelReason m30 : 32|2@1+ (1,0) [0|3] "" Vector__XXX
 SG_ PM_a030_diBrakeTorqueCommand m30 : 34|13@1+ (2,0) [0|16382] "" Vector__XXX
 SG_ PM_a032_w0 m32 : 16|16@1+ (1,0) [0|65535] "" Vector__XXX
 SG_ PM_a032_w1 m32 : 32|16@1+ (1,0) [0|65535] "" Vector__XXX
 SG_ PM_a032_w2 m32 : 48|16@1+ (1,0) [0|65535] "" Vector__XXX
 SG_ PM_a036_timeSinceTxHWI m36 : 16|6@1+ (64,0) [0|4032] "" Vector__XXX
 SG_ PM_a036_timeSinceRxHWI m36 : 22|6@1+ (64,0) [0|4032] "" Vector__XXX
 SG_ PM_a036_timeSince100HzTxSWI m36 : 28|6@1+ (0.32,0) [0|20.16] "" Vector__XXX
 SG_ PM_a036_timeSince1kHzCLK m36 : 34|6@1+ (32,0) [0|2016] "" Vector__XXX
 SG_ PM_a036_timeSince1kHzSWI m36 : 40|6@1+ (32,0) [0|2016] "" Vector__XXX
 SG_ PM_a036_timeSinceIdle m36 : 46|6@1+ (0.16,0) [0|10.08] "" Vector__XXX
 SG_ PM_a036_ovfStackId m36 : 52|4@1+ (1,0) [0|15] "" Vector__XXX
 SG_ PM_a036_inTxISR m36 : 56|1@1+ (1,0) [0|1] "" Vector__XXX
 SG_ PM_a036_inTxHWI m36 : 57|1@1+ (1,0) [0|1] "" Vector__XXX
 SG_ PM_a036_inRxHWI m36 : 58|1@1+ (1,0) [0|1] "" Vector__XXX
 SG_ PM_a036_in1kHzSWI m36 : 59|1@1+ (1,0) [0|1] "" Vector__XXX
 SG_ PM_a036_in1kHzCLK m36 : 60|1@1+ (1,0) [0|1] "" Vector__XXX
 SG_ PM_a036_in100HzCLK m36 : 61|1@1+ (1,0) [0|1] "" Vector__XXX
 SG_ PM_a036_in10HzCLK m36 : 62|1@1+ (1,0) [0|1] "" Vector__XXX
 SG_ PM_a036_in1HzCLK m36 : 63|1@1+ (1,0) [0|1] "" Vector__XXX
 SG_ PM_a038_masterTorque m38 : 16|13@1- (0.4,0) [-1638.4|1638] "" Vector__XXX
 SG_ PM_a038_slaveTorque m38 : 32|13@1- (0.4,0) [-1638.4|1638] "" Vector__XXX
 SG_ PM_a038_pedalPos m38 : 48|8@1- (0.4,50.4) [-0.8|101.2] "" Vector__XXX
 SG_ PM_a039_DIS_status m39 : 16|1@1+ (1,0) [0|1] "" Vector__XXX
 SG_ PM_a039_DIS_torque m39 : 17|1@1+ (1,0) [0|1] "" Vector__XXX
 SG_ PM_a039_messageId m39 : 24|16@1+ (1,0) [0|65535] "" Vector__XXX
 SG_ PM_a041_DAS_control m41 : 16|1@1+ (1,0) [0|1] "" Vector__XXX
 SG_ PM_a041_DAS_longControl m41 : 17|1@1+ (1,0) [0|1] "" Vector__XXX
 SG_ PM_a041_DAS_longControlTuningPar m41 : 18|1@1+ (1,0) [0|1] "" Vector__XXX
 SG_ PM_a041_DAS_status m41 : 19|1@1+ (1,0) [0|1] "" Vector__XXX
 SG_ PM_a041_DAS_status2 m41 : 20|1@1+ (1,0) [0|1] "" Vector__XXX
 SG_ PM_a041_DAS_smartShift m41 : 21|1@1+ (1,0) [0|1] "" Vector__XXX
 SG_ PM_a042_GTW_carConfig m42 : 16|1@1+ (1,0) [0|1] "" Vector__XXX
 SG_ PM_a042_GTW_time m42 : 17|1@1+ (1,0) [0|1] "" Vector__XXX
 SG_ PM_a042_GTW_drivetrainType m42 : 18|2@1+ (1,0) [0|3] "" Vector__XXX
 SG_ PM_a042_expectedPerformanceCfg m42 : 20|2@1+ (1,0) [0|3] "" Vector__XXX
 SG_ PM_a042_gearControl m42 : 22|1@1+ (1,0) [0|1] "" Vector__XXX
 SG_ PM_a043_configInconsistent m43 : 16|1@1+ (1,0) [0|1] "" Vector__XXX
 SG_ PM_a043_GTW_autopilot m43 : 17|1@1+ (1,0) [0|1] "" Vector__XXX
 SG_ PM_a043_expectedAutopilot m43 : 18|1@1+ (1,0) [0|1] "" Vector__XXX
 SG_ PM_a043_GTW_drivetrainType m43 : 19|2@1+ (1,0) [0|3] "" Vector__XXX
 SG_ PM_a043_expectedDrivetrainType m43 : 21|2@1+ (1,0) [0|3] "" Vector__XXX
 SG_ PM_a043_GTW_chassisType m43 : 24|2@1+ (1,0) [0|3] "" Vector__XXX
 SG_ PM_a043_expectedChassisType m43 : 26|2@1+ (1,0) [0|3] "" Vector__XXX
 SG_ PM_a043_packEnergy m43 : 28|1@1+ (1,0) [0|1] "" Vector__XXX
 SG_ PM_a043_packPerformanceDeviation m43 : 29|1@1+ (1,0) [0|1] "" Vector__XXX
 SG_ PM_a043_performancePackage m43 : 30|1@1+ (1,0) [0|1] "" Vector__XXX
 SG_ PM_a043_GTW_vdcType m43 : 31|1@1+ (1,0) [0|1] "" Vector__XXX
 SG_ PM_a043_expectedVdcType m43 : 32|1@1+ (1,0) [0|1] "" Vector__XXX
 SG_ PM_a043_brakeHWType m43 : 33|1@1+ (1,0) [0|1] "" Vector__XXX
 SG_ PM_a043_cabinPTCHeaterType m43 : 34|1@1+ (1,0) [0|1] "" Vector__XXX
 SG_ PM_a043_softPerformanceLimit m43 : 35|1@1+ (1,0) [0|1] "" Vector__XXX
 SG_ PM_a043_GTW_dasHw m43 : 36|1@1+ (1,0) [0|1] "" Vector__XXX
 SG_ PM_a044_pmCruiseState m44 : 16|3@1+ (1,0) [0|7] "" Vector__XXX
 SG_ PM_a044_diCruiseState m44 : 19|3@1+ (1,0) [0|7] "" Vector__XXX
 SG_ PM_a044_pmAebState m44 : 24|3@1+ (1,0) [0|7] "" Vector__XXX
 SG_ PM_a044_diAebState m44 : 27|3@1+ (1,0) [0|7] "" Vector__XXX
 SG_ PM_a044_diBrakeTorqueCommand m44 : 30|13@1+ (2,0) [0|16382] "" Vector__XXX
 SG_ PM_a044_pmBfillTorqueAllowed m44 : 43|13@1+ (2,0) [0|16382] "" Vector__XXX
 SG_ PM_a044_pmVehicleHoldState m44 : 56|3@1+ (1,0) [0|7] "" Vector__XXX
 SG_ PM_a044_diVehicleHoldState m44 : 59|3@1+ (1,0) [0|7] "" Vector__XXX
 SG_ PM_a044_regenBackfillPmState m44 : 62|2@1+ (1,0) [0|3] "" Vector__XXX
 SG_ PM_a045_regenBackfillPmState m45 : 16|2@1+ (1,0) [0|3] "" Vector__XXX
 SG_ PM_a045_regenBackfillDiState m45 : 18|2@1+ (1,0) [0|3] "" Vector__XXX
 SG_ PM_a045_unavailableReason m45 : 24|5@1+ (1,0) [0|31] "" Vector__XXX
 SG_ PM_a045_diBrakeTorqueCommand m45 : 32|13@1+ (2,0) [0|16382] "" Vector__XXX
 SG_ PM_a045_pmBrakeTorqueAllowed m45 : 48|13@1+ (2,0) [0|16382] "" Vector__XXX
 SG_ PM_a046_diVhldState m46 : 16|3@1+ (1,0) [0|7] "" Vector__XXX
 SG_ PM_a046_pmVhldState m46 : 19|3@1+ (1,0) [0|7] "" Vector__XXX
 SG_ PM_a046_vhldFaultReason m46 : 24|3@1+ (1,0) [0|7] "" Vector__XXX
 SG_ PM_a046_vhldUnavailableReason m46 : 27|4@1+ (1,0) [0|15] "" Vector__XXX
 SG_ PM_a046_diBrakeTorqueCommand m46 : 32|13@1+ (2,0) [0|16382] "" Vector__XXX
 SG_ PM_a046_diBrakeCommandType m46 : 45|3@1+ (1,0) [0|7] "" Vector__XXX
 SG_ PM_a047_pmAutoparkState m47 : 16|4@1+ (1,0) [0|15] "" Vector__XXX
 SG_ PM_a047_diAutoparkState m47 : 20|4@1+ (1,0) [0|15] "" Vector__XXX
 SG_ PM_a047_autoparkCancelReason m47 : 24|2@1+ (1,0) [0|3] "" Vector__XXX
 SG_ PM_a048_vdcFaultReason m48 : 16|4@1+ (1,0) [0|15] "" Vector__XXX
 SG_ PM_a053_LVPowerState m53 : 16|1@1+ (1,0) [0|1] "" Vector__XXX
 SG_ PM_a053_coolant m53 : 17|1@1+ (1,0) [0|1] "" Vector__XXX
 SG_ PM_a053_vcleftSwitchStatus m53 : 18|1@1+ (1,0) [0|1] "" Vector__XXX
 SG_ PM_a053_restraintStatus m53 : 19|1@1+ (1,0) [0|1] "" Vector__XXX
 SG_ PM_a053_sensors m53 : 20|1@1+ (1,0) [0|1] "" Vector__XXX
 SG_ PM_a054_uiPowertrainControl m54 : 16|1@1+ (1,0) [0|1] "" Vector__XXX
 SG_ PM_a054_uiChassisControl m54 : 17|1@1+ (1,0) [0|1] "" Vector__XXX
 SG_ PM_a054_uiCruiseControl m54 : 18|1@1+ (1,0) [0|1] "" Vector__XXX
 SG_ PM_a054_uiTrackModeSettings m54 : 19|1@1+ (1,0) [0|1] "" Vector__XXX
 SG_ PM_a054_uiTPMSRCPSetting m54 : 20|1@1+ (1,0) [0|1] "" Vector__XXX
 SG_ PM_a056_mailboxID m56 : 16|16@1+ (1,0) [0|65535] "" Vector__XXX
 SG_ PM_a056_canID m56 : 32|16@1+ (1,0) [0|65535] "" Vector__XXX
 SG_ PM_a056_errorType m56 : 48|3@1+ (1,0) [0|7] "" Vector__XXX
 SG_ PM_a057_canID m57 : 16|12@1+ (1,0) [0|4095] "" Vector__XXX
 SG_ PM_a057_errorType m57 : 28|3@1+ (1,0) [0|7] "" Vector__XXX
 SG_ PM_a057_badValue1 m57 : 32|16@1+ (1,0) [0|65535] "" Vector__XXX
 SG_ PM_a057_badValue2 m57 : 48|16@1+ (1,0) [0|65535] "" Vector__XXX
 SG_ PM_a058_CMP_HVStatus m58 : 16|1@1+ (1,0) [0|1] "" Vector__XXX
 SG_ PM_a058_CMPD_state m58 : 17|1@1+ (1,0) [0|1] "" Vector__XXX
 SG_ PM_a059_PTC_feedbackStatus m59 : 16|1@1+ (1,0) [0|1] "" Vector__XXX
 SG_ PM_a060_TorqueAccelWindow m60 : 16|16@1- (0.05,0) [-1638.4|1638.35] "" Vector__XXX
 SG_ PM_a060_TorqueDecelWindow m60 : 32|16@1- (0.05,0) [-1638.4|1638.35] "" Vector__XXX
 SG_ PM_a060_TorqueReversalWindow m60 : 48|16@1- (0.05,0) [-1638.4|1638.35] "" Vector__XXX
 SG_ PM_a061_diIpcVersion m61 : 16|8@1+ (1,0) [0|255] "" Vector__XXX
 SG_ PM_a061_pmIpcVersion m61 : 24|8@1+ (1,0) [0|255] "" Vector__XXX
 SG_ PM_a062_address m62 : 16|32@1+ (1,0) [0|4294967295] "" Vector__XXX
 SG_ PM_a062_errorType m62 : 48|4@1+ (1,0) [0|15] "" Vector__XXX
 SG_ PM_a063_totalSystemTorqueCommand m63 : 16|13@1- (0.4,0) [-1638.4|1638] "" Vector__XXX
 SG_ PM_a063_totalSystemTorqueMeasure m63 : 32|13@1- (0.4,0) [-1638.4|1638] "" Vector__XXX
 SG_ PM_a064_interventionType m64 : 16|4@1+ (1,0) [0|15] "" Vector__XXX
 SG_ PM_a064_torqueCmdState m64 : 20|4@1+ (1,0) [0|15] "" Vector__XXX
 SG_ PM_a064_shortDetectedByDI m64 : 24|1@1+ (1,0) [0|1] "" Vector__XXX
 SG_ PM_a064_UI_stoppingMode m64 : 25|2@1+ (1,0) [0|3] "" Vector__XXX
 SG_ PM_a064_diCrsState m64 : 27|3@1+ (1,0) [0|7] "" Vector__XXX
 SG_ PM_a064_pmCrsState m64 : 32|3@1+ (1,0) [0|7] "" Vector__XXX
 SG_ PM_a066_state4 m66 : 16|1@1+ (1,0) [0|1] "" Vector__XXX
 SG_ PM_a067_state4 m67 : 16|1@1+ (1,0) [0|1] "" Vector__XXX
 SG_ PM_a073_canID m73 : 16|12@1+ (1,0) [0|4095] "" Vector__XXX
 SG_ PM_a073_errorType m73 : 28|3@1+ (1,0) [0|7] "" Vector__XXX
 SG_ PM_a073_badValue1 m73 : 32|16@1+ (1,0) [0|65535] "" Vector__XXX
 SG_ PM_a073_badValue2 m73 : 48|16@1+ (1,0) [0|65535] "" Vector__XXX
 SG_ PM_a074_mailboxID m74 : 16|16@1+ (1,0) [0|65535] "" Vector__XXX
 SG_ PM_a074_canID m74 : 32|16@1+ (1,0) [0|65535] "" Vector__XXX
 SG_ PM_a074_errorType m74 : 48|3@1+ (1,0) [0|7] "" Vector__XXX
 SG_ PM_a075_canID m75 : 16|12@1+ (1,0) [0|4095] "" Vector__XXX
 SG_ PM_a075_errorType m75 : 28|3@1+ (1,0) [0|7] "" Vector__XXX
 SG_ PM_a075_badValue1 m75 : 32|16@1+ (1,0) [0|65535] "" Vector__XXX
 SG_ PM_a075_badValue2 m75 : 48|16@1+ (1,0) [0|65535] "" Vector__XXX
 SG_ PM_a076_mailboxID m76 : 16|16@1+ (1,0) [0|65535] "" Vector__XXX
 SG_ PM_a076_canID m76 : 32|16@1+ (1,0) [0|65535] "" Vector__XXX
 SG_ PM_a076_errorType m76 : 48|3@1+ (1,0) [0|7] "" Vector__XXX
 SG_ PM_a077_canID m77 : 16|12@1+ (1,0) [0|4095] "" Vector__XXX
 SG_ PM_a077_errorType m77 : 28|3@1+ (1,0) [0|7] "" Vector__XXX
 SG_ PM_a077_badValue1 m77 : 32|16@1+ (1,0) [0|65535] "" Vector__XXX
 SG_ PM_a077_badValue2 m77 : 48|16@1+ (1,0) [0|65535] "" Vector__XXX
 SG_ PM_a078_mailboxID m78 : 16|16@1+ (1,0) [0|65535] "" Vector__XXX
 SG_ PM_a078_canID m78 : 32|16@1+ (1,0) [0|65535] "" Vector__XXX
 SG_ PM_a078_errorType m78 : 48|3@1+ (1,0) [0|7] "" Vector__XXX
 SG_ PM_a079_VEH_RCU_actuation m79 : 16|1@1+ (1,0) [0|1] "" Vector__XXX
 SG_ PM_a079_PARTY_RCU_actuation m79 : 17|1@1+ (1,0) [0|1] "" Vector__XXX
 SG_ PM_a082_faultAddress m82 : 16|32@1+ (1,0) [0|4294967295] "" Vector__XXX
 SG_ PM_a082_isWriteNotRead m82 : 48|1@1+ (1,0) [0|1] "" Vector__XXX
 SG_ PM_a084_faultAddress m84 : 16|32@1+ (1,0) [0|4294967295] "" Vector__XXX
 SG_ PM_a084_firewallId m84 : 48|5@1+ (1,0) [0|31] "" Vector__XXX
 SG_ PM_a084_privId m84 : 56|4@1+ (1,0) [0|15] "" Vector__XXX
 SG_ PM_a084_ns m84 : 60|1@1+ (1,0) [0|1] "" Vector__XXX
 SG_ PM_a084_faultType m84 : 61|3@1+ (1,0) [0|7] "" Vector__XXX
 SG_ PM_a085_DPB_actuator3 m85 : 16|1@1+ (1,0) [0|1] "" Vector__XXX
 SG_ PM_a087_mailboxID m87 : 16|16@1+ (1,0) [0|65535] "" Vector__XXX
 SG_ PM_a087_canID m87 : 32|16@1+ (1,0) [0|65535] "" Vector__XXX
 SG_ PM_a087_errorType m87 : 48|3@1+ (1,0) [0|7] "" Vector__XXX
 SG_ PM_a092_pllClockSource m92 : 16|2@1+ (1,0) [0|3] "" Vector__XXX
 SG_ PM_a100_index1kHzPeriodic m100 : 16|8@1+ (1,0) [0|255] "" Vector__XXX
 SG_ PM_a100_index100HzPeriodic m100 : 24|8@1+ (1,0) [0|255] "" Vector__XXX
 SG_ PM_a100_index10HzPeriodic m100 : 32|8@1+ (1,0) [0|255] "" Vector__XXX
 SG_ PM_a100_indexSWI m100 : 40|8@1+ (1,0) [0|255] "" Vector__XXX
 SG_ PM_a100_eepEvent m100 : 48|8@1+ (1,0) [0|255] "" Vector__XXX
 SG_ PM_a100_module500HzActive m100 : 56|1@1+ (1,0) [0|1] "" Vector__XXX
 SG_ PM_a100_module50HzActive m100 : 57|1@1+ (1,0) [0|1] "" Vector__XXX
 SG_ PM_a100_module1HzActive m100 : 58|1@1+ (1,0) [0|1] "" Vector__XXX
 SG_ PM_a100_task10HzActive m100 : 59|1@1+ (1,0) [0|1] "" Vector__XXX
 SG_ PM_a100_taskUdsActive m100 : 60|1@1+ (1,0) [0|1] "" Vector__XXX

BO_ 900 PM_alertMatrix1: 8 PM
 SG_ PM_a001_absoluteTorque : 0|1@1+ (1,0) [0|1] "" Vector__XXX
 SG_ PM_a002_excessiveAccelTorque : 1|1@1+ (1,0) [0|1] "" Vector__XXX
 SG_ PM_a003_excessiveReversalTorque : 2|1@1+ (1,0) [0|1] "" Vector__XXX
 SG_ PM_a004_excessiveDecelTorque : 3|1@1+ (1,0) [0|1] "" Vector__XXX
 SG_ PM_a005_torqueInNeutralOrPark : 4|1@1+ (1,0) [0|1] "" Vector__XXX
 SG_ PM_a006_inconsistentDIGear : 5|1@1+ (1,0) [0|1] "" Vector__XXX
 SG_ PM_a007_ibstMIA : 6|1@1+ (1,0) [0|1] "" Vector__XXX
 SG_ PM_a008_memoryError : 7|1@1+ (1,0) [0|1] "" Vector__XXX
 SG_ PM_a009_espMIA : 8|1@1+ (1,0) [0|1] "" Vector__XXX
 SG_ PM_a010_diMIA : 9|1@1+ (1,0) [0|1] "" Vector__XXX
 SG_ PM_a011_systemHvilNotClosed : 10|1@1+ (1,0) [0|1] "" Vector__XXX
 SG_ PM_a012_canDataBusA : 11|1@1+ (1,0) [0|1] "" Vector__XXX
 SG_ PM_a013_canHardwareBusA : 12|1@1+ (1,0) [0|1] "" Vector__XXX
 SG_ PM_a014_accelPedalError : 13|1@1+ (1,0) [0|1] "" Vector__XXX
 SG_ PM_a015_shifterMIA : 14|1@1+ (1,0) [0|1] "" Vector__XXX
 SG_ PM_a016_bbMIA : 15|1@1+ (1,0) [0|1] "" Vector__XXX
 SG_ PM_a017_brakeMIA : 16|1@1+ (1,0) [0|1] "" Vector__XXX
 SG_ PM_a019_vehicleSpeedQFDiagnostic : 18|1@1+ (1,0) [0|1] "" Vector__XXX
 SG_ PM_a021_difMIA : 20|1@1+ (1,0) [0|1] "" Vector__XXX
 SG_ PM_a022_dirMIA : 21|1@1+ (1,0) [0|1] "" Vector__XXX
 SG_ PM_a023_cruiseInhibit : 22|1@1+ (1,0) [0|1] "" Vector__XXX
 SG_ PM_a024_brakeIrrational : 23|1@1+ (1,0) [0|1] "" Vector__XXX
 SG_ PM_a025_unintendedReset : 24|1@1+ (1,0) [0|1] "" Vector__XXX
 SG_ PM_a026_diHeartBeatMIA : 25|1@1+ (1,0) [0|1] "" Vector__XXX
 SG_ PM_a028_torqueCmdError : 27|1@1+ (1,0) [0|1] "" Vector__XXX
 SG_ PM_a029_cruiseRollback : 28|1@1+ (1,0) [0|1] "" Vector__XXX
 SG_ PM_a030_inconsistentAebState : 29|1@1+ (1,0) [0|1] "" Vector__XXX
 SG_ PM_a031_highStackUsage : 30|1@1+ (1,0) [0|1] "" Vector__XXX
 SG_ PM_a032_registerConfigError : 31|1@1+ (1,0) [0|1] "" Vector__XXX
 SG_ PM_a033_appMIA : 32|1@1+ (1,0) [0|1] "" Vector__XXX
 SG_ PM_a034_trqCrossCheck : 33|1@1+ (1,0) [0|1] "" Vector__XXX
 SG_ PM_a035_udsTransactionInitiated : 34|1@1+ (1,0) [0|1] "" Vector__XXX
 SG_ PM_a036_preWatchdog : 35|1@1+ (1,0) [0|1] "" Vector__XXX
 SG_ PM_a038_inconsistentTorqueSign : 37|1@1+ (1,0) [0|1] "" Vector__XXX
 SG_ PM_a039_disMIA : 38|1@1+ (1,0) [0|1] "" Vector__XXX
 SG_ PM_a040_latLinkLooseBoltDetected : 39|1@1+ (1,0) [0|1] "" Vector__XXX
 SG_ PM_a041_dasMIA : 40|1@1+ (1,0) [0|1] "" Vector__XXX
 SG_ PM_a042_gtwMIA : 41|1@1+ (1,0) [0|1] "" Vector__XXX
 SG_ PM_a043_inconsistentConfig : 42|1@1+ (1,0) [0|1] "" Vector__XXX
 SG_ PM_a044_ebrIntervention : 43|1@1+ (1,0) [0|1] "" Vector__XXX
 SG_ PM_a045_regenBackfillInterventio : 44|1@1+ (1,0) [0|1] "" Vector__XXX
 SG_ PM_a046_inconsVehicleHoldState : 45|1@1+ (1,0) [0|1] "" Vector__XXX
 SG_ PM_a047_inconsAutoparkState : 46|1@1+ (1,0) [0|1] "" Vector__XXX
 SG_ PM_a048_stabilityControlInhibit : 47|1@1+ (1,0) [0|1] "" Vector__XXX
 SG_ PM_a049_stbCtrlInWrongDir : 48|1@1+ (1,0) [0|1] "" Vector__XXX
 SG_ PM_a050_excessiveStbCtrlTrq : 49|1@1+ (1,0) [0|1] "" Vector__XXX
 SG_ PM_a051_unintDecelStbCtrl : 50|1@1+ (1,0) [0|1] "" Vector__XXX
 SG_ PM_a052_stbCtrlDrvrDecelCflct : 51|1@1+ (1,0) [0|1] "" Vector__XXX
 SG_ PM_a053_vcfrontMIA : 52|1@1+ (1,0) [0|1] "" Vector__XXX
 SG_ PM_a054_uiMIA : 53|1@1+ (1,0) [0|1] "" Vector__XXX
 SG_ PM_a055_accelPedalSyncWarn : 54|1@1+ (1,0) [0|1] "" Vector__XXX
 SG_ PM_a056_canHardwareBusB : 55|1@1+ (1,0) [0|1] "" Vector__XXX
 SG_ PM_a057_canDataBusB : 56|1@1+ (1,0) [0|1] "" Vector__XXX
 SG_ PM_a058_cmpMIA : 57|1@1+ (1,0) [0|1] "" Vector__XXX
 SG_ PM_a059_ptcMIA : 58|1@1+ (1,0) [0|1] "" Vector__XXX
 SG_ PM_a060_onePedalDrivingInhibit : 59|1@1+ (1,0) [0|1] "" Vector__XXX
 SG_ PM_a061_DIPMVersionMismatch : 60|1@1+ (1,0) [0|1] "" Vector__XXX
 SG_ PM_a062_eccError : 61|1@1+ (1,0) [0|1] "" Vector__XXX
 SG_ PM_a063_torqueCommandInhibit : 62|1@1+ (1,0) [0|1] "" Vector__XXX
 SG_ PM_a064_torqueIntervention : 63|1@1+ (1,0) [0|1] "" Vector__XXX

BO_ 896 PM_alertMatrix2: 8 PM
 SG_ PM_a066_pmfMIA : 1|1@1+ (1,0) [0|1] "" Vector__XXX
 SG_ PM_a067_pmrMIA : 2|1@1+ (1,0) [0|1] "" Vector__XXX
 SG_ PM_a068_brakePedalMonitor : 3|1@1+ (1,0) [0|1] "" Vector__XXX
 SG_ PM_a069_brakeMonitorsUnhealthy : 4|1@1+ (1,0) [0|1] "" Vector__XXX
 SG_ PM_a070_brakeTorqueSplitMonitorT : 5|1@1+ (1,0) [0|1] "" Vector__XXX
 SG_ PM_a071_baseBrakingMonitor : 6|1@1+ (1,0) [0|1] "" Vector__XXX
 SG_ PM_a072_brakeTorqueCommandInterf : 7|1@1+ (1,0) [0|1] "" Vector__XXX
 SG_ PM_a073_canDataBusC : 8|1@1+ (1,0) [0|1] "" Vector__XXX
 SG_ PM_a074_canHardwareBusC : 9|1@1+ (1,0) [0|1] "" Vector__XXX
 SG_ PM_a075_canDataBusD : 10|1@1+ (1,0) [0|1] "" Vector__XXX
 SG_ PM_a076_canHardwareBusD : 11|1@1+ (1,0) [0|1] "" Vector__XXX
 SG_ PM_a077_canDataBusE : 12|1@1+ (1,0) [0|1] "" Vector__XXX
 SG_ PM_a078_canHardwareBusE : 13|1@1+ (1,0) [0|1] "" Vector__XXX
 SG_ PM_a079_rcuMIA : 14|1@1+ (1,0) [0|1] "" Vector__XXX
 SG_ PM_a080_exceptionPrefetchAbort : 15|1@1+ (1,0) [0|1] "" Vector__XXX
 SG_ PM_a081_exceptionDataAbort : 16|1@1+ (1,0) [0|1] "" Vector__XXX
 SG_ PM_a082_exceptionDataAbort2 : 17|1@1+ (1,0) [0|1] "" Vector__XXX
 SG_ PM_a083_ahbWriteError : 18|1@1+ (1,0) [0|1] "" Vector__XXX
 SG_ PM_a084_exceptionMpuFirewall : 19|1@1+ (1,0) [0|1] "" Vector__XXX
 SG_ PM_a085_dpbMIA : 20|1@1+ (1,0) [0|1] "" Vector__XXX
 SG_ PM_a086_exceptionUndefinedInstru : 21|1@1+ (1,0) [0|1] "" Vector__XXX
 SG_ PM_a087_canHardwareBusLIPC : 22|1@1+ (1,0) [0|1] "" Vector__XXX
 SG_ PM_a092_xtalOscillator : 27|1@1+ (1,0) [0|1] "" Vector__XXX
 SG_ PM_a093_accelPedalSupply : 28|1@1+ (1,0) [0|1] "" Vector__XXX
 SG_ PM_a095_ITPMSTimeoutGNSSConverge : 30|1@1+ (1,0) [0|1] "" Vector__XXX
 SG_ PM_a096_ITPMSConvergedGNSSAbsRad : 31|1@1+ (1,0) [0|1] "" Vector__XXX
 SG_ PM_a098_ITPMSTriggerDebug : 33|1@1+ (1,0) [0|1] "" Vector__XXX
 SG_ PM_a099_ITPMSCalibrated : 34|1@1+ (1,0) [0|1] "" Vector__XXX
 SG_ PM_a100_diTraceInfo1 : 35|1@1+ (1,0) [0|1] "" Vector__XXX
 SG_ PM_a110_indirectTPMSSoftWarningF : 45|1@1+ (1,0) [0|1] "" Vector__XXX
 SG_ PM_a111_indirectTPMSSoftWarningF : 46|1@1+ (1,0) [0|1] "" Vector__XXX
 SG_ PM_a112_indirectTPMSSoftWarningR : 47|1@1+ (1,0) [0|1] "" Vector__XXX
 SG_ PM_a113_indirectTPMSSoftWarningR : 48|1@1+ (1,0) [0|1] "" Vector__XXX
 SG_ PM_a114_indirectTPMSHardWarningF : 49|1@1+ (1,0) [0|1] "" Vector__XXX
 SG_ PM_a115_indirectTPMSHardWarningF : 50|1@1+ (1,0) [0|1] "" Vector__XXX
 SG_ PM_a116_indirectTPMSHardWarningR : 51|1@1+ (1,0) [0|1] "" Vector__XXX
 SG_ PM_a117_indirectTPMSHardWarningR : 52|1@1+ (1,0) [0|1] "" Vector__XXX
 SG_ PM_a120_indirectTPMSFaulted : 55|1@1+ (1,0) [0|1] "" Vector__XXX
 SG_ PM_a121_unintendedReset2 : 56|1@1+ (1,0) [0|1] "" Vector__XXX

BO_ 2020 PM_info: 8 PM
 SG_ PM_infoIndex M : 0|8@1+ (1,0) [0|255] "" Vector__XXX
 SG_ PM_buildType m10 : 8|8@1+ (1,0) [0|255] "" Vector__XXX
 SG_ PM_buildConfigurationId m10 : 16|16@1+ (1,0) [0|65535] "" Vector__XXX
 SG_ PM_hardwareId m10 : 32|8@1+ (1,0) [0|252] "" Vector__XXX
 SG_ PM_deviceFused m10 : 40|1@1+ (1,0) [0|1] "" Vector__XXX
 SG_ PM_componentId m10 : 48|16@1+ (1,0) [0|65535] "" Vector__XXX
 SG_ PM_pcbaId m11 : 16|8@1+ (1,0) [0|255] "" Vector__XXX
 SG_ PM_assemblyId m11 : 24|8@1+ (1,0) [0|255] "" Vector__XXX
 SG_ PM_usageId m11 : 32|16@1+ (1,0) [0|65535] "" Vector__XXX
 SG_ PM_subUsageId m11 : 48|16@1+ (1,0) [0|65535] "" Vector__XXX
 SG_ PM_applicationCrc m13 : 32|32@1+ (1,0) [0|4294967295] "" Vector__XXX
 SG_ PM_bootGitHash m18 : 8|56@1+ (1,0) [0|7.20575940379e+16] "" Vector__XXX

BO_ 463 PM_systemState: 8 PM
 SG_ PM_torqueCheckState : 0|3@1+ (1,0) [0|7] "" Vector__XXX
 SG_ PM_limpRequest : 3|2@1+ (1,0) [0|3] "" Vector__XXX
 SG_ PM_torqueCommand : 8|13@1- (2,0) [-8192|8190] "" Vector__XXX
 SG_ PM_torqueState : 21|2@1+ (1,0) [0|3] "" Vector__XXX
 SG_ PM_hvilSystemStatus : 24|2@1+ (1,0) [0|3] "" Vector__XXX
 SG_ PM_sysElecPower : 26|11@1- (1,250) [-774|1273] "" Vector__XXX
 SG_ PM_sysNumUnitsMia : 37|2@1+ (1,0) [0|3] "" Vector__XXX
 SG_ PM_sysNumUnitsSna : 39|2@1+ (1,0) [0|3] "" Vector__XXX
 SG_ PM_sysElecPowerVeryLow : 41|1@1+ (1,0) [0|1] "" Vector__XXX
 SG_ PM_systemStateCounter : 53|3@1+ (1,0) [0|7] "" Vector__XXX
 SG_ PM_systemStateChecksum : 56|8@1+ (1,0) [0|255] "" Vector__XXX

BO_ 2038 PM_vdcDebug: 8 PM
 SG_ PM_vdcDebugSelector M : 0|6@1+ (1,0) [0|63] "" Vector__XXX
 SG_ PM_VDCA_TCSlipTargetMod_RA_Fwd m5 : 8|6@1- (0.1,0) [-3|3] "m/s" Vector__XXX
 SG_ PM_VDCA_TCSlipTargetMod_RA_Rwd m5 : 16|6@1- (0.1,0) [-3|3] "m/s" Vector__XXX
 SG_ PM_VSE_forceY_RA m5 : 22|9@1- (40,240) [-10000|10440] "N" Vector__XXX
 SG_ PM_VDCT_observerSlipAngle_RA m5 : 31|9@1- (0.005,0.03) [-1.25|1.305] "rad" Vector__XXX
 SG_ PM_VSE_muVehicleFxLow m5 : 40|5@1+ (0.05,0) [0|1.55] "mu" Vector__XXX
 SG_ PM_VE_fxmFres m13 : 8|8@1- (200,0) [-20000|20000] "N" Vector__XXX
 SG_ PM_VE_fxAccelMass m13 : 16|8@1- (0.16,0) [-20|20] "m/s^2" Vector__XXX
 SG_ PM_VE_vxDotGrade m13 : 24|8@1- (0.1,0.8) [-12|13.5] "m/s^2" Vector__XXX
 SG_ PM_VE_betaEst m13 : 32|8@1- (0.01,0) [-1|1] "rad" Vector__XXX
 SG_ PM_VSE_muVehicleFxHigh m13 : 40|5@1+ (0.05,0) [0|1.55] "mu" Vector__XXX
 SG_ PM_VSE_muVehicleDecLeakRate m29 : 6|5@1+ (0.05,0) [0|1.55] "mu" Vector__XXX
 SG_ PM_VSE_muVehicleLearnDown m29 : 11|5@1+ (0.05,0) [0|1.55] "mu" Vector__XXX
 SG_ PM_VSE_muVehicleDecFilter m29 : 16|5@1+ (0.05,0) [0|1.55] "mu" Vector__XXX
 SG_ PM_VSE_muVehicleLatDecLeakRate m29 : 21|5@1+ (0.05,0) [0|1.55] "mu" Vector__XXX
 SG_ PM_VSE_splitMuProbability m29 : 26|5@1+ (0.05,0) [0|1.55] "probability" Vector__XXX
 SG_ PM_VSE_splitMuTotalMz m29 : 31|9@1- (60,360) [-15000|15660] "Nm" Vector__XXX
 SG_ PM_VSE_attitudeBankAngle m29 : 40|9@1- (0.005,0.03) [-1.25|1.305] "rad" Vector__XXX
 SG_ PM_VSE_attitudeDBetaInControl m29 : 49|8@1- (0.01,0.03) [-1.25|1.3] "rad" Vector__XXX
 SG_ PM_VSE_roadWheelAngleAverage m29 : 57|7@1- (0.015,0.255) [-0.7|1.2] "rad" Vector__XXX

BO_ 1766 PNCD_IsoTpPipeToCp: 8 PNCD
 SG_ PNCD_isoTpToCpData : 0|64@1+ (1,0) [0|1.84467440737e+19] "" Vector__XXX

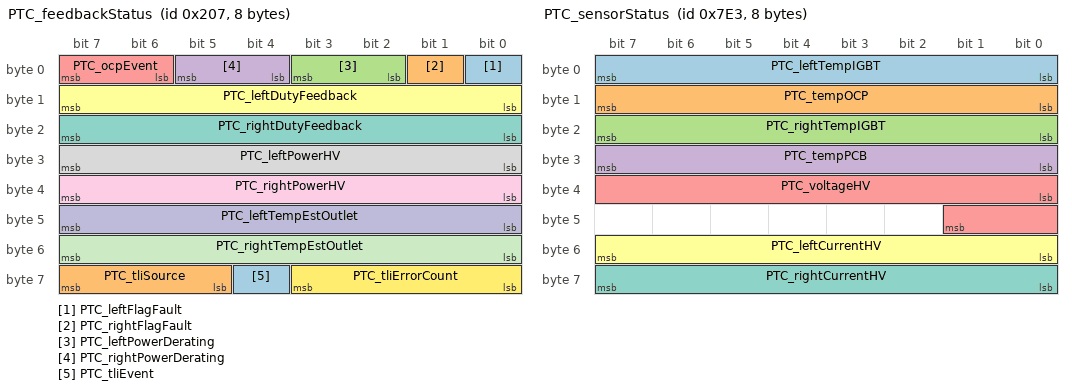
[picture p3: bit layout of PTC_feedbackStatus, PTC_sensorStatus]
BO_ 519 PTC_feedbackStatus: 8 PTC
 SG_ PTC_leftFlagFault : 0|1@1+ (1,0) [0|1] "" Vector__XXX
 SG_ PTC_rightFlagFault : 1|1@1+ (1,0) [0|1] "" Vector__XXX
 SG_ PTC_leftPowerDerating : 2|2@1+ (1,0) [0|3] "" Vector__XXX
 SG_ PTC_rightPowerDerating : 4|2@1+ (1,0) [0|3] "" Vector__XXX
 SG_ PTC_ocpEvent : 6|2@1+ (1,0) [0|3] "" Vector__XXX
 SG_ PTC_leftDutyFeedback : 8|8@1+ (0.5,0) [0|100] "%" Vector__XXX
 SG_ PTC_rightDutyFeedback : 16|8@1+ (0.5,0) [0|100] "%" Vector__XXX
 SG_ PTC_leftPowerHV : 24|8@1+ (30,0) [0|7650] "W" Vector__XXX
 SG_ PTC_rightPowerHV : 32|8@1+ (30,0) [0|7650] "W" Vector__XXX
 SG_ PTC_leftTempEstOutlet : 40|8@1+ (1,-40) [-40|200] "degC" Vector__XXX
 SG_ PTC_rightTempEstOutlet : 48|8@1+ (1,-40) [-40|200] "degC" Vector__XXX
 SG_ PTC_tliErrorCount : 56|4@1+ (1,0) [0|15] "" Vector__XXX
 SG_ PTC_tliEvent : 60|1@1+ (1,0) [0|1] "" Vector__XXX
 SG_ PTC_tliSource : 61|3@1+ (1,0) [0|7] "" Vector__XXX

BO_ 837 PTC_info: 8 PTC
 SG_ PTC_infoIndex M : 0|8@1+ (1,0) [0|255] "" Vector__XXX
 SG_ PTC_infoBuildType m10 : 8|3@1+ (1,0) [0|7] "" Vector__XXX
 SG_ PTC_infoBuildConfigId m10 : 16|16@1+ (1,0) [0|65535] "" Vector__XXX
 SG_ PTC_infoHardwareId m10 : 32|16@1+ (1,0) [0|65535] "" Vector__XXX
 SG_ PTC_infoComponentId m10 : 48|16@1+ (1,0) [0|65535] "" Vector__XXX
 SG_ PTC_infoPcbaId m11 : 16|8@1+ (1,0) [0|255] "" Vector__XXX
 SG_ PTC_infoAssemblyId m11 : 24|8@1+ (1,0) [0|255] "" Vector__XXX
 SG_ PTC_infoUsageId m11 : 32|16@1+ (1,0) [0|65535] "" Vector__XXX
 SG_ PTC_infoSubUsageId m11 : 48|16@1+ (1,0) [0|65535] "" Vector__XXX
 SG_ PTC_infoPlatformType m13 : 8|8@1+ (1,0) [0|255] "" Vector__XXX
 SG_ PTC_infoAppCrc m13 : 32|32@1+ (1,0) [0|4294967295] "" Vector__XXX
 SG_ PTC_infoBootUdsProtoVersion m20 : 8|8@1+ (1,0) [0|255] "" Vector__XXX
 SG_ PTC_infoBootCrc m20 : 32|32@1+ (1,0) [0|4294967295] "" Vector__XXX

BO_ 2019 PTC_sensorStatus: 8 PTC
 SG_ PTC_leftTempIGBT : 0|8@1+ (1,-40) [-40|200] "degC" Vector__XXX
 SG_ PTC_tempOCP : 8|8@1+ (1,-40) [-40|200] "degC" Vector__XXX
 SG_ PTC_rightTempIGBT : 16|8@1+ (1,-40) [-40|200] "degC" Vector__XXX
 SG_ PTC_tempPCB : 24|8@1+ (1,-40) [-40|200] "degC" Vector__XXX
 SG_ PTC_voltageHV : 32|10@1+ (0.5,0) [0|511.5] "V" Vector__XXX
 SG_ PTC_leftCurrentHV : 48|8@1+ (0.2,0) [0|50] "A" Vector__XXX
 SG_ PTC_rightCurrentHV : 56|8@1+ (0.2,0) [0|50] "A" Vector__XXX

CM_ BO_ 548 "Power conversion system (on-board charger and DC-DC converter) message: dcdc status";
CM_ SG_ 548 PCS_dcdcPrechargeStatus "Status of DCDC HV bus precharge";
CM_ SG_ 548 PCS_dcdcLvSupportStatus "Status of DCDC LV support";
CM_ SG_ 548 PCS_dcdcHvBusDischargeStatus "Power conversion system (on-board charger and DC-DC converter): dcdc hv bus discharge status";
CM_ SG_ 548 PCS_coldSleepAllowed "Power conversion system (on-board charger and DC-DC converter): cold sleep allowed";
CM_ SG_ 548 PCS_dcdcPchgHVBusLowRDetected "Power conversion system (on-board charger and DC-DC converter): dcdc pchg HV bus low r detected";
CM_ SG_ 548 PCS_dcdcSubState "Substate of DCDC state machine";
CM_ SG_ 548 PCS_dcdcFaulted "Whether the DCDC is in faulted state";
CM_ SG_ 548 PCS_okToBePowerCycled "Power conversion system (on-board charger and DC-DC converter): ok to be power cycled";
CM_ SG_ 548 PCS_dcdcOutputIsLimited "Whether the DCDC's output is current limiting";
CM_ SG_ 548 PCS_dcdcMaxOutputCurrentAllowed "Maximum LV output current capability of DCDC based on operating point";
CM_ SG_ 548 PCS_dcdcPrechargeRtyCnt "Power conversion system (on-board charger and DC-DC converter): dcdc precharge rty cnt";
CM_ SG_ 548 PCS_dcdcLvSupportRtyCnt "Power conversion system (on-board charger and DC-DC converter): dcdc lv support rty cnt";
CM_ SG_ 548 PCS_dcdcDischargeRtyCnt "Power conversion system (on-board charger and DC-DC converter): dcdc discharge rty cnt";
CM_ SG_ 548 PCS_dcdcPwmEnableLine "Sensed state of the DCDC PWM enable hardline";
CM_ SG_ 548 PCS_dcdcSupportingFixedLvTarget "Whether DCDC is running LV support at a fixed voltage target";
CM_ SG_ 548 PCS_ecuLogUploadRequest "Power conversion system (on-board charger and DC-DC converter): ecu log upload request";
CM_ SG_ 548 PCS_dcdcPrechargeRestartCnt "Power conversion system (on-board charger and DC-DC converter): dcdc precharge restart cnt";
CM_ SG_ 548 PCS_dcdcInitialPrechargeSubState "Power conversion system (on-board charger and DC-DC converter): dcdc initial precharge sub state";
CM_ BO_ 964 "Power conversion system (on-board charger and DC-DC converter) message: info";
CM_ SG_ 964 PCS_infoIndex "Power conversion system (on-board charger and DC-DC converter): info index";
CM_ SG_ 964 PCS_buildType "Power conversion system (on-board charger and DC-DC converter): build type";
CM_ SG_ 964 PCS_buildConfigId "Power conversion system (on-board charger and DC-DC converter): build config id";
CM_ SG_ 964 PCS_hardwareId "Power conversion system (on-board charger and DC-DC converter): hardware id";
CM_ SG_ 964 PCS_componentId "Power conversion system (on-board charger and DC-DC converter): component id";
CM_ SG_ 964 PCS_pcbaId "PCBA ID portion of component hardware ID as reported by application";
CM_ SG_ 964 PCS_assemblyId "Power conversion system (on-board charger and DC-DC converter): assembly id";
CM_ SG_ 964 PCS_usageId "Usage ID portion of component hardware ID as reported by application";
CM_ SG_ 964 PCS_subUsageId "Sub-usage ID portion of component hardware ID as reported by application";
CM_ SG_ 964 PCS_platformType "Power conversion system (on-board charger and DC-DC converter): platform type";
CM_ SG_ 964 PCS_appCrc "Power conversion system (on-board charger and DC-DC converter): app crc";
CM_ SG_ 964 PCS_cpu2AppCrc "Power conversion system (on-board charger and DC-DC converter): cpu2 app crc";
CM_ SG_ 964 PCS_appGitHash "Power conversion system (on-board charger and DC-DC converter): app git hash";
CM_ SG_ 964 PCS_bootGitHash "Power conversion system (on-board charger and DC-DC converter): boot git hash";
CM_ SG_ 964 PCS_bootUdsProtoVersion "Power conversion system (on-board charger and DC-DC converter): boot uds proto version";
CM_ SG_ 964 PCS_bootCrc "Power conversion system (on-board charger and DC-DC converter): boot crc";
CM_ BO_ 708 "Power conversion system (on-board charger and DC-DC converter) message: logging";
CM_ SG_ 708 PCS_logMessageSelect "Power conversion system (on-board charger and DC-DC converter): log message select";
CM_ SG_ 708 PCS_chgPhAInputIrms "AC charger phase A's sensed RMS input current";
CM_ SG_ 708 PCS_chgPhAIntBusV "AC charger phase A's sensed intermediate bus voltage";
CM_ SG_ 708 PCS_chgPhAIntBusVTarget "AC charger phase A's intermediate bus voltage target";
CM_ SG_ 708 PCS_chgPhAOutputI "AC charger phase A sensed output current";
CM_ SG_ 708 PCS_chgPhAInputCurrentLimitReaso "Provides the reason behind the input AC charging current limit for phase A";
CM_ SG_ 708 PCS_chgPhBInputIrms "AC charger phase B's sensed RMS input current";
CM_ SG_ 708 PCS_chgPhBIntBusV "AC charger phase B's sensed intermediate bus voltage";
CM_ SG_ 708 PCS_chgPhBIntBusVTarget "AC charger phase B's intermediate bus voltage target";
CM_ SG_ 708 PCS_chgPhBOutputI "AC charger phase B sensed output current";
CM_ SG_ 708 PCS_chgPhBInputCurrentLimitReaso "Provides the reason behind the input AC charging current limit for phase B";
CM_ SG_ 708 PCS_chgPhCInputIrms "AC charger phase C's sensed RMS input current";
CM_ SG_ 708 PCS_chgPhCIntBusV "AC charger phase C's sensed intermediate bus voltage";
CM_ SG_ 708 PCS_chgPhCIntBusVTarget "AC charger phase C's intermediate bus voltage target";
CM_ SG_ 708 PCS_chgPhCOutputI "AC charger phase C sensed output current";
CM_ SG_ 708 PCS_chgPhCInputCurrentLimitReaso "Provides the reason behind the input AC charging current limit for phase C";
CM_ SG_ 708 PCS_chgInputL1NVrms "AC charger's sensed AC RMS voltage of L1-N voltage source";
CM_ SG_ 708 PCS_chgInputL2NVrms "AC charger's sensed AC RMS voltage of L2-N voltage source";
CM_ SG_ 708 PCS_chgInputL3NVrms "AC charger's sensed AC RMS voltage of L3-N voltage source";
CM_ SG_ 708 PCS_chgInputL1L2Vrms "AC charger's sensed input frequency of L2-N voltage source";
CM_ SG_ 708 PCS_chgInputNGVrms "AC charger's sensed AC RMS voltage of N-G voltage source";
CM_ SG_ 708 PCS_chgInputFrequencyL1N "AC charger's sensed input frequency of L1-N voltage source";
CM_ SG_ 708 PCS_chgInputFrequencyL2N "AC charger's sensed input frequency of L2-N voltage source";
CM_ SG_ 708 PCS_chgInputFrequencyL3N "AC charger's sensed input frequency of L3-N voltage source";
CM_ SG_ 708 PCS_chgInternalPhaseConfig "Internal phase configuration of the AC charger (three phase vs. single phase)";
CM_ SG_ 708 PCS_chgPhasesPriority "AC charger phase manager's priority logic for enabling phases in single phase PCS variant";
CM_ SG_ 708 PCS_chgOutputV "Sensed output voltage of AC charger";
CM_ SG_ 708 PCS_chgPhAState "State of AC charger phase A";
CM_ SG_ 708 PCS_chgPhBState "State of AC charger phase B";
CM_ SG_ 708 PCS_chgPhCState "State of AC charger phase C";
CM_ SG_ 708 PCS_chgPhALastShutdownReason "Last reason for shutting down AC charger phase A";
CM_ SG_ 708 PCS_chgPhBLastShutdownReason "Last reason for shutting down AC charger phase B";
CM_ SG_ 708 PCS_chgPhCLastShutdownReason "Last reason for shutting down AC charger phase C";
CM_ SG_ 708 PCS_chgPhARetryCount "AC charger phase A number of retries used during the current charge session";
CM_ SG_ 708 PCS_chgPhBRetryCount "AC charger phase B number of retries used during the current charge session";
CM_ SG_ 708 PCS_chgPhCRetryCount "AC charger phase C number of retries used during the current charge session";
CM_ SG_ 708 PCS_chgRetryCount "AC charger number of system level retries used during the current charge session";
CM_ SG_ 708 PCS_chgPhManCurrentToDist "Power conversion system (on-board charger and DC-DC converter): chg ph man current to dist";
CM_ SG_ 708 PCS_chgL1NPllLocked "Power conversion system (on-board charger and DC-DC converter): chg L1 n pll locked";
CM_ SG_ 708 PCS_chgL2NPllLocked "Power conversion system (on-board charger and DC-DC converter): chg L2 n pll locked";
CM_ SG_ 708 PCS_chgL3NPllLocked "Power conversion system (on-board charger and DC-DC converter): chg L3 n pll locked";
CM_ SG_ 708 PCS_chgL1L2PllLocked "Power conversion system (on-board charger and DC-DC converter): chg L1 L2 pll locked";
CM_ SG_ 708 PCS_chgNgPllLocked "Power conversion system (on-board charger and DC-DC converter): chg ng pll locked";
CM_ SG_ 708 PCS_chgPhManOptimalPhsToUse "Power conversion system (on-board charger and DC-DC converter): chg ph man optimal phs to use";
CM_ SG_ 708 PCS_chg5VL1Enable "Power conversion system (on-board charger and DC-DC converter): chg5 VL1 enable";
CM_ SG_ 708 PCS_dcdcMaxLvOutputCurrent "Overall maxmum LV output current capability of DCDC";
CM_ SG_ 708 PCS_dcdcCurrentLimit "Power conversion system (on-board charger and DC-DC converter): dcdc current limit";
CM_ SG_ 708 PCS_dcdcLvOutputCurrentTempLimit "Maximum LV output current capability of DCDC based on thermals";
CM_ SG_ 708 PCS_dcdcLvOutputCurrentFiltered "DCDC's filtered LV output current";
CM_ SG_ 708 PCS_dcdcUnifiedCommand "Power conversion system (on-board charger and DC-DC converter): dcdc unified command";
CM_ SG_ 708 PCS_dcdcCLAControllerOutput "Power conversion system (on-board charger and DC-DC converter): dcdc CLA controller output";
CM_ SG_ 708 PCS_dcdcTankVoltage "Power conversion system (on-board charger and DC-DC converter): dcdc tank voltage";
CM_ SG_ 708 PCS_dcdcTankVoltageTarget "Power conversion system (on-board charger and DC-DC converter): dcdc tank voltage target";
CM_ SG_ 708 PCS_dcdcClaCurrentFreq "Power conversion system (on-board charger and DC-DC converter): dcdc cla current freq";
CM_ SG_ 708 PCS_dcdcTCommMeasured "Power conversion system (on-board charger and DC-DC converter): dcdc t comm measured";
CM_ SG_ 708 PCS_dcdcShortTimeUs "Power conversion system (on-board charger and DC-DC converter): dcdc short time us";
CM_ SG_ 708 PCS_dcdcHalfPeriodUs "Power conversion system (on-board charger and DC-DC converter): dcdc half period us";
CM_ SG_ 708 PCS_dcdcLvBusVoltTargetWithOffse "LV support Voltage target with Feed-forward offset";
CM_ SG_ 708 PCS_cpu2BootState "Power conversion system (on-board charger and DC-DC converter): cpu2 boot state";
CM_ SG_ 708 PCS_acChargeSelfTestState "Power conversion system (on-board charger and DC-DC converter): ac charge self test state";
CM_ SG_ 708 PCS_1V5Min10s "Power conversion system (on-board charger and DC-DC converter): 1 V5 min10s";
CM_ SG_ 708 PCS_1V5Max10s "Power conversion system (on-board charger and DC-DC converter): 1 V5 max10s";
CM_ SG_ 708 PCS_1V2Min10s "Power conversion system (on-board charger and DC-DC converter): 1 V2 min10s";
CM_ SG_ 708 PCS_1V2Max10s "Power conversion system (on-board charger and DC-DC converter): 1 V2 max10s";
CM_ SG_ 708 PCS_5VNMax10s "Power conversion system (on-board charger and DC-DC converter): 5 VN max10s";
CM_ SG_ 708 PCS_chgPhAIntBusVMin10s "AC charger phase A's minimum sensed intermediate bus voltage over the last ten seconds";
CM_ SG_ 708 PCS_chgPhAIntBusVMax10s "AC charger phase A's maximum sensed intermediate bus voltage over the last ten seconds";
CM_ SG_ 708 PCS_chgPhAPchgVoltDeltaMax10s "AC charger phase A maximum sensed voltage delta between line and intermediate bus in the last 10 seconds during SCR precharge";
CM_ SG_ 708 PCS_chgPhALifetimekWh "Lifetime total energy throughput of AC charger phase A";
CM_ SG_ 708 PCS_chgPhATransientRetryCount "AC charger phase A number of transient retries used during the current charge session";
CM_ SG_ 708 PCS_chgPhBIntBusVMin10s "AC charger phase B's minimum sensed intermediate bus voltage over the last ten seconds";
CM_ SG_ 708 PCS_chgPhBIntBusVMax10s "AC charger phase B's maximum sensed intermediate bus voltage over the last ten seconds";
CM_ SG_ 708 PCS_chgPhBPchgVoltDeltaMax10s "AC charger phase B maximum sensed voltage delta between line and intermediate bus in the last 10 seconds during SCR precharge";
CM_ SG_ 708 PCS_chgPhBLifetimekWh "Lifetime total energy throughput of AC charger phase B";
CM_ SG_ 708 PCS_chgPhBTransientRetryCount "AC charger phase B number of transient retries used during the current charge session";
CM_ SG_ 708 PCS_chgPhCIntBusVMin10s "AC charger phase C's minimum sensed intermediate bus voltage over the last ten seconds";
CM_ SG_ 708 PCS_chgPhCIntBusVMax10s "AC charger phase C's maximum sensed intermediate bus voltage over the last ten seconds";
CM_ SG_ 708 PCS_chgPhCPchgVoltDeltaMax10s "AC charger phase C maximum sensed voltage delta between line and intermediate bus in the last 10 seconds during SCR precharge";
CM_ SG_ 708 PCS_chgPhCLifetimekWh "Lifetime total energy throughput of AC charger phase C";
CM_ SG_ 708 PCS_chgPhCTransientRetryCount "AC charger phase C number of transient retries used during the current charge session";
CM_ SG_ 708 PCS_chgPhANoFlowBucket "Power conversion system (on-board charger and DC-DC converter): chg ph a no flow bucket";
CM_ SG_ 708 PCS_chgPhBNoFlowBucket "Power conversion system (on-board charger and DC-DC converter): chg ph b no flow bucket";
CM_ SG_ 708 PCS_chgPhCNoFlowBucket "Power conversion system (on-board charger and DC-DC converter): chg ph c no flow bucket";
CM_ SG_ 708 PCS_chgCurrentSensorOutOfBandUs "Power conversion system (on-board charger and DC-DC converter): chg current sensor out of band us";
CM_ SG_ 708 PCS_chgAcpwHeartbeatState "A signal to indicate if PCS detects the heartbeat signature from AC Power Wall";
CM_ SG_ 708 PCS_chgKwhLostByFreqDroop "Power conversion system (on-board charger and DC-DC converter): chg kwh lost by freq droop";
CM_ SG_ 708 PCS_chgReqKwhLostByFreqDroop "Power conversion system (on-board charger and DC-DC converter): chg req kwh lost by freq droop";
CM_ SG_ 708 PCS_dcdcLvSupportLifetimekWh "Lifetime energy throughput of DCDC LV support mode";
CM_ SG_ 708 PCS_chgPwmEnableLineErrorCount "Power conversion system (on-board charger and DC-DC converter): chg pwm enable line error count";
CM_ SG_ 708 PCS_dcdcPwmEnableLineErrorCount "Number of deassertions detected for DCDC PWM enable line";
CM_ SG_ 708 PCS_numAlertsSet "Power conversion system (on-board charger and DC-DC converter): num alerts set";
CM_ SG_ 708 PCS_dcdcPchgStartLvBusVolt "Sensed LV bus votlage when beginning DCDC precharge";
CM_ SG_ 708 PCS_dcdcPchgStartHvBusVolt "Sensed HV bus votlage when beginning DCDC precharge";
CM_ SG_ 708 PCS_processorDieIdLot "Power conversion system (on-board charger and DC-DC converter): processor die id lot";
CM_ SG_ 708 PCS_processorDieIdWafer "Power conversion system (on-board charger and DC-DC converter): processor die id wafer";
CM_ SG_ 708 PCS_processorDieIdX "Power conversion system (on-board charger and DC-DC converter): processor die id x";
CM_ SG_ 708 PCS_processorDieIdY "Power conversion system (on-board charger and DC-DC converter): processor die id y";
CM_ BO_ 676 "Power conversion system (on-board charger and DC-DC converter) message: thermal status";
CM_ SG_ 676 PCS_chgPhATemp "Sensed temperature of AC charger phase A";
CM_ SG_ 676 PCS_chgPhBTemp "Sensed temperature of AC charger phase B";
CM_ SG_ 676 PCS_chgPhCTemp "Sensed temperature of AC charger phase C";
CM_ SG_ 676 PCS_dcdcTemp "Sensed temperature of DCDC";
CM_ SG_ 676 PCS_ambientTemp "Ambient temperature sensed by the PCS";
CM_ SG_ 676 PCS_dcdcBusbarTemp "Sensed temperature of DCDC busbar";
CM_ BO_ 1317 "PMF ECU message: alert log";
CM_ SG_ 1317 PMF_alertID "PMF ECU: alert ID";
CM_ SG_ 1317 PMF_alertState "PMF ECU: alert state";
CM_ SG_ 1317 PMF_a001_w0 "PMF ECU: a001 w0";
CM_ SG_ 1317 PMF_a001_w1 "PMF ECU: a001 w1";
CM_ SG_ 1317 PMF_a001_w2 "PMF ECU: a001 w2";
CM_ SG_ 1317 PMF_a002_torqueAverage "PMF ECU: a002 torque average";
CM_ SG_ 1317 PMF_a002_torqueWindow "PMF ECU: a002 torque window";
CM_ SG_ 1317 PMF_a002_torqueMeasured "PMF ECU: a002 torque measured";
CM_ SG_ 1317 PMF_a002_torqueAccelAverage "PMF ECU: a002 torque accel average";
CM_ SG_ 1317 PMF_a002_torqueAccelWindow "PMF ECU: a002 torque accel window";
CM_ SG_ 1317 PMF_a003_reverseGear "PMF ECU: a003 reverse gear";
CM_ SG_ 1317 PMF_a003_pedalPos "PMF ECU: a003 pedal pos";
CM_ SG_ 1317 PMF_a003_zeroPointPedal "PMF ECU: a003 zero point pedal";
CM_ SG_ 1317 PMF_a004_torqueAverage "PMF ECU: a004 torque average";
CM_ SG_ 1317 PMF_a004_torqueWindow "PMF ECU: a004 torque window";
CM_ SG_ 1317 PMF_a004_torqueMeasured "PMF ECU: a004 torque measured";
CM_ SG_ 1317 PMF_a004_torqueDecelAverage "PMF ECU: a004 torque decel average";
CM_ SG_ 1317 PMF_a004_torqueDecelWindow "PMF ECU: a004 torque decel window";
CM_ SG_ 1317 PMF_a005_torqueReason "PMF ECU: a005 torque reason";
CM_ SG_ 1317 PMF_a005_torqueMeasured "PMF ECU: a005 torque measured";
CM_ SG_ 1317 PMF_a005_iDQmagnitude "PMF ECU: a005 i d qmagnitude";
CM_ SG_ 1317 PMF_a006_torqueActual "PMF ECU: a006 torque actual";
CM_ SG_ 1317 PMF_a006_motorRPM "PMF ECU: a006 motor RPM";
CM_ SG_ 1317 PMF_a006_torqueMeasured "PMF ECU: a006 torque measured";
CM_ SG_ 1317 PMF_a010_messageId "PMF ECU: a010 message id";
CM_ SG_ 1317 PMF_a010_DI_status "PMF ECU: a010 DI status";
CM_ SG_ 1317 PMF_a010_DI_torque "PMF ECU: a010 DI torque";
CM_ SG_ 1317 PMF_a010_DI_slaveCommand "PMF ECU: a010 DI slave command";
CM_ SG_ 1317 PMF_a010_DI_locStatus "PMF ECU: a010 DI loc status";
CM_ SG_ 1317 PMF_a010_DI_speed "PMF ECU: a010 DI speed";
CM_ SG_ 1317 PMF_a010_DI_systemStatus "PMF ECU: a010 DI system status";
CM_ SG_ 1317 PMF_a010_DI_chassisControl "PMF ECU: a010 DI chassis control";
CM_ SG_ 1317 PMF_a010_DI_chassisControl2 "PMF ECU: a010 DI chassis control2";
CM_ SG_ 1317 PMF_a010_vdcLeft "PMF ECU: a010 vdc left";
CM_ SG_ 1317 PMF_a010_vdcRight "PMF ECU: a010 vdc right";
CM_ SG_ 1317 PMF_a010_DI_vehicleEstimates "PMF ECU: a010 DI vehicle estimates";
CM_ SG_ 1317 PMF_a010_DI_brakeCommand "PMF ECU: a010 DI brake command";
CM_ SG_ 1317 PMF_a010_DI_difCommand "PMF ECU: a010 DI dif command";
CM_ SG_ 1317 PMF_a010_DI_dirCommand "PMF ECU: a010 DI dir command";
CM_ SG_ 1317 PMF_a010_DI_dirVehicle "PMF ECU: a010 DI dir vehicle";
CM_ SG_ 1317 PMF_a010_DI_locStatus2 "PMF ECU: a010 DI loc status2";
CM_ SG_ 1317 PMF_a011_Ia "PMF ECU: a011 ia";
CM_ SG_ 1317 PMF_a011_Ib "PMF ECU: a011 ib";
CM_ SG_ 1317 PMF_a011_currentVref "PMF ECU: a011 current vref";
CM_ SG_ 1317 PMF_a011_badPhaseAsample "PMF ECU: a011 bad phase asample";
CM_ SG_ 1317 PMF_a011_badPhaseBsample "PMF ECU: a011 bad phase bsample";
CM_ SG_ 1317 PMF_a011_sampleFreeze "PMF ECU: a011 sample freeze";
CM_ SG_ 1317 PMF_a012_canID "PMF ECU: a012 can ID";
CM_ SG_ 1317 PMF_a012_errorType "PMF ECU: a012 error type";
CM_ SG_ 1317 PMF_a012_badValue1 "PMF ECU: a012 bad value1";
CM_ SG_ 1317 PMF_a012_badValue2 "PMF ECU: a012 bad value2";
CM_ SG_ 1317 PMF_a013_mailboxID "PMF ECU: a013 mailbox ID";
CM_ SG_ 1317 PMF_a013_canID "PMF ECU: a013 can ID";
CM_ SG_ 1317 PMF_a013_errorType "PMF ECU: a013 error type";
CM_ SG_ 1317 PMF_a017_EPBL_status "PMF ECU: a017 EPBL status";
CM_ SG_ 1317 PMF_a017_EPBR_status "PMF ECU: a017 EPBR status";
CM_ SG_ 1317 PMF_a018_w0 "PMF ECU: a018 w0";
CM_ SG_ 1317 PMF_a018_w1 "PMF ECU: a018 w1";
CM_ SG_ 1317 PMF_a018_w2 "PMF ECU: a018 w2";
CM_ SG_ 1317 PMF_a019_statorTemp1 "PMF ECU: a019 stator temp1";
CM_ SG_ 1317 PMF_a019_statorTslope1 "PMF ECU: a019 stator tslope1";
CM_ SG_ 1317 PMF_a025_sccReset "PMF ECU: a025 scc reset";
CM_ SG_ 1317 PMF_a025_hibernate "PMF ECU: a025 hibernate";
CM_ SG_ 1317 PMF_a025_hwBist "PMF ECU: a025 hw bist";
CM_ SG_ 1317 PMF_a025_nmiWatchdog "PMF ECU: a025 nmi watchdog";
CM_ SG_ 1317 PMF_a025_watchdog "PMF ECU: a025 watchdog";
CM_ SG_ 1317 PMF_a025_clockFailNmi "PMF ECU: a025 clock fail nmi";
CM_ SG_ 1317 PMF_a025_ramUncErrorNmi "PMF ECU: a025 ram unc error nmi";
CM_ SG_ 1317 PMF_a025_flashUncErrorNmi "PMF ECU: a025 flash unc error nmi";
CM_ SG_ 1317 PMF_a025_cpu1signMismatchNmi "PMF ECU: a025 cpu1sign mismatch nmi";
CM_ SG_ 1317 PMF_a025_cpu2signMismatchNmi "PMF ECU: a025 cpu2sign mismatch nmi";
CM_ SG_ 1317 PMF_a025_pieVectErrorNmi "PMF ECU: a025 pie vect error nmi";
CM_ SG_ 1317 PMF_a025_sysDbgNmi "PMF ECU: a025 sys dbg nmi";
CM_ SG_ 1317 PMF_a025_rlNmi "PMF ECU: a025 rl nmi";
CM_ SG_ 1317 PMF_a025_ovfNmi "PMF ECU: a025 ovf nmi";
CM_ SG_ 1317 PMF_a025_possibleSafetyICReset "PMF ECU: a025 possible safety IC reset";
CM_ SG_ 1317 PMF_a025_powerOnReset "PMF ECU: a025 power on reset";
CM_ SG_ 1317 PMF_a025_watchdogTimer0 "PMF ECU: a025 watchdog timer0";
CM_ SG_ 1317 PMF_a025_watchdogTimer1 "PMF ECU: a025 watchdog timer1";
CM_ SG_ 1317 PMF_a025_watchdogTimer2 "PMF ECU: a025 watchdog timer2";
CM_ SG_ 1317 PMF_a025_watchdogTimer3 "PMF ECU: a025 watchdog timer3";
CM_ SG_ 1317 PMF_a025_warmResetReq "PMF ECU: a025 warm reset req";
CM_ SG_ 1317 PMF_a025_externalPadReset "PMF ECU: a025 external pad reset";
CM_ SG_ 1317 PMF_a025_hwSecModuleWatchdogTime "PMF ECU: a025 hw sec module watchdog timer";
CM_ SG_ 1317 PMF_a025_debugReset "PMF ECU: a025 debug reset";
CM_ SG_ 1317 PMF_a025_tempSense0 "PMF ECU: a025 temp sense0";
CM_ SG_ 1317 PMF_a025_tempSense1 "PMF ECU: a025 temp sense1";
CM_ SG_ 1317 PMF_a026_reason "PMF ECU: a026 reason";
CM_ SG_ 1317 PMF_a026_isrCount20kHz "PMF ECU: a026 isr count20k hz";
CM_ SG_ 1317 PMF_a026_isrCount1kHz "PMF ECU: a026 isr count1k hz";
CM_ SG_ 1317 PMF_a026_switchingActive "PMF ECU: a026 switching active";
CM_ SG_ 1317 PMF_a026_systemStackOvf "PMF ECU: a026 system stack ovf";
CM_ SG_ 1317 PMF_a026_controlStackOvf "PMF ECU: a026 control stack ovf";
CM_ SG_ 1317 PMF_a026_idleStackOvf "PMF ECU: a026 idle stack ovf";
CM_ SG_ 1317 PMF_a026_eepStackOvf "PMF ECU: a026 eep stack ovf";
CM_ SG_ 1317 PMF_a026_immStackOvf "PMF ECU: a026 imm stack ovf";
CM_ SG_ 1317 PMF_a026_xdcErrorIdMSW "PMF ECU: a026 xdc error id MSW";
CM_ SG_ 1317 PMF_a026_xdcErrorArg1 "PMF ECU: a026 xdc error arg1";
CM_ SG_ 1317 PMF_a032_w0 "PMF ECU: a032 w0";
CM_ SG_ 1317 PMF_a032_w1 "PMF ECU: a032 w1";
CM_ SG_ 1317 PMF_a032_w2 "PMF ECU: a032 w2";
CM_ SG_ 1317 PMF_a033_state "PMF ECU: a033 state";
CM_ SG_ 1317 PMF_a033_failReason "PMF ECU: a033 fail reason";
CM_ SG_ 1317 PMF_a033_DSADC_Ia "PMF ECU: a033 DSADC ia";
CM_ SG_ 1317 PMF_a033_DSADC_Ib "PMF ECU: a033 DSADC ib";
CM_ SG_ 1317 PMF_a036_timeSinceTxHWI "PMF ECU: a036 time since tx HWI";
CM_ SG_ 1317 PMF_a036_timeSinceRxHWI "PMF ECU: a036 time since rx HWI";
CM_ SG_ 1317 PMF_a036_timeSince100HzTxSWI "PMF ECU: a036 time since100 hz tx SWI";
CM_ SG_ 1317 PMF_a036_timeSince1kHzCLK "PMF ECU: a036 time since1k hz CLK";
CM_ SG_ 1317 PMF_a036_timeSince1kHzSWI "PMF ECU: a036 time since1k hz SWI";
CM_ SG_ 1317 PMF_a036_timeSinceIdle "PMF ECU: a036 time since idle";
CM_ SG_ 1317 PMF_a036_ovfStackId "PMF ECU: a036 ovf stack id";
CM_ SG_ 1317 PMF_a036_inTxISR "PMF ECU: a036 in tx ISR";
CM_ SG_ 1317 PMF_a036_inTxHWI "PMF ECU: a036 in tx HWI";
CM_ SG_ 1317 PMF_a036_inRxHWI "PMF ECU: a036 in rx HWI";
CM_ SG_ 1317 PMF_a036_in1kHzSWI "PMF ECU: a036 in1k hz SWI";
CM_ SG_ 1317 PMF_a036_in1kHzCLK "PMF ECU: a036 in1k hz CLK";
CM_ SG_ 1317 PMF_a036_in100HzCLK "PMF ECU: a036 in100 hz CLK";
CM_ SG_ 1317 PMF_a036_in10HzCLK "PMF ECU: a036 in10 hz CLK";
CM_ SG_ 1317 PMF_a036_in1HzCLK "PMF ECU: a036 in1 hz CLK";
CM_ SG_ 1317 PMF_a037_hvpFaults "PMF ECU: a037 hvp faults";
CM_ SG_ 1317 PMF_a039_DIS_status "PMF ECU: a039 DIS status";
CM_ SG_ 1317 PMF_a039_DIS_torque "PMF ECU: a039 DIS torque";
CM_ SG_ 1317 PMF_a039_messageId "PMF ECU: a039 message id";
CM_ SG_ 1317 PMF_a040_PM_state "PMF ECU: a040 PM state";
CM_ SG_ 1317 PMF_a040_messageId "PMF ECU: a040 message id";
CM_ SG_ 1317 PMF_a040_PM_locState "PMF ECU: a040 PM loc state";
CM_ SG_ 1317 PMF_a042_GTW_carConfig "PMF ECU: a042 GTW car config";
CM_ SG_ 1317 PMF_a042_GTW_time "PMF ECU: a042 GTW time";
CM_ SG_ 1317 PMF_a042_GTW_drivetrainType "PMF ECU: a042 GTW drivetrain type";
CM_ SG_ 1317 PMF_a042_expectedPerformanceCfg "PMF ECU: a042 expected performance cfg";
CM_ SG_ 1317 PMF_a042_gearControl "PMF ECU: a042 gear control";
CM_ SG_ 1317 PMF_a053_LVPowerState "PMF ECU: a053 LV power state";
CM_ SG_ 1317 PMF_a053_coolant "PMF ECU: a053 coolant";
CM_ SG_ 1317 PMF_a053_vcleftSwitchStatus "PMF ECU: a053 vcleft switch status";
CM_ SG_ 1317 PMF_a053_restraintStatus "PMF ECU: a053 restraint status";
CM_ SG_ 1317 PMF_a053_sensors "PMF ECU: a053 sensors";
CM_ SG_ 1317 PMF_a054_uiPowertrainControl "PMF ECU: a054 ui powertrain control";
CM_ SG_ 1317 PMF_a054_uiChassisControl "PMF ECU: a054 ui chassis control";
CM_ SG_ 1317 PMF_a054_uiCruiseControl "PMF ECU: a054 ui cruise control";
CM_ SG_ 1317 PMF_a054_uiTrackModeSettings "PMF ECU: a054 ui track mode settings";
CM_ SG_ 1317 PMF_a054_uiTPMSRCPSetting "PMF ECU: a054 ui TPMSRCP setting";
CM_ SG_ 1317 PMF_a055_motorRPM "PMF ECU: a055 motor RPM";
CM_ SG_ 1317 PMF_a055_phaseAngle "PMF ECU: a055 phase angle";
CM_ SG_ 1317 PMF_a055_commonGain "PMF ECU: a055 common gain";
CM_ SG_ 1317 PMF_a055_notReady "PMF ECU: a055 not ready";
CM_ SG_ 1317 PMF_a055_noCarrier "PMF ECU: a055 no carrier";
CM_ SG_ 1317 PMF_a055_phaseOutOfSpec "PMF ECU: a055 phase out of spec";
CM_ SG_ 1317 PMF_a055_diElecAngleMismatch "PMF ECU: a055 di elec angle mismatch";
CM_ SG_ 1317 PMF_a055_diSpeedMismatch "PMF ECU: a055 di speed mismatch";
CM_ SG_ 1317 PMF_a055_claMIA "PMF ECU: a055 cla MIA";
CM_ SG_ 1317 PMF_a055_diMIA "PMF ECU: a055 di MIA";
CM_ SG_ 1317 PMF_a055_diElecAngleMismatchWarn "PMF ECU: a055 di elec angle mismatch warn";
CM_ SG_ 1317 PMF_a056_mailboxID "PMF ECU: a056 mailbox ID";
CM_ SG_ 1317 PMF_a056_canID "PMF ECU: a056 can ID";
CM_ SG_ 1317 PMF_a056_errorType "PMF ECU: a056 error type";
CM_ SG_ 1317 PMF_a057_canID "PMF ECU: a057 can ID";
CM_ SG_ 1317 PMF_a057_errorType "PMF ECU: a057 error type";
CM_ SG_ 1317 PMF_a057_badValue1 "PMF ECU: a057 bad value1";
CM_ SG_ 1317 PMF_a057_badValue2 "PMF ECU: a057 bad value2";
CM_ SG_ 1317 PMF_a058_hvilCurrent "PMF ECU: a058 hvil current";
CM_ SG_ 1317 PMF_a061_diIpcVersion "PMF ECU: a061 di ipc version";
CM_ SG_ 1317 PMF_a061_pmIpcVersion "PMF ECU: a061 pm ipc version";
CM_ SG_ 1317 PMF_a062_address "PMF ECU: a062 address";
CM_ SG_ 1317 PMF_a062_errorType "PMF ECU: a062 error type";
CM_ SG_ 1317 PMF_a064_interventionType "PMF ECU: a064 intervention type";
CM_ SG_ 1317 PMF_a064_torqueCmdState "PMF ECU: a064 torque cmd state";
CM_ SG_ 1317 PMF_a064_shortDetectedByDI "PMF ECU: a064 short detected by DI";
CM_ SG_ 1317 PMF_a064_UI_stoppingMode "PMF ECU: a064 UI stopping mode";
CM_ SG_ 1317 PMF_a064_diCrsState "PMF ECU: a064 di crs state";
CM_ SG_ 1317 PMF_a064_pmCrsState "PMF ECU: a064 pm crs state";
CM_ SG_ 1317 PMF_a082_faultAddress "PMF ECU: a082 fault address";
CM_ SG_ 1317 PMF_a082_isWriteNotRead "PMF ECU: a082 is write not read";
CM_ SG_ 1317 PMF_a084_faultAddress "PMF ECU: a084 fault address";
CM_ SG_ 1317 PMF_a084_firewallId "PMF ECU: a084 firewall id";
CM_ SG_ 1317 PMF_a084_privId "PMF ECU: a084 priv id";
CM_ SG_ 1317 PMF_a084_ns "PMF ECU: a084 ns";
CM_ SG_ 1317 PMF_a084_faultType "PMF ECU: a084 fault type";
CM_ SG_ 1317 PMF_a092_pllClockSource "PMF ECU: a092 pll clock source";
CM_ SG_ 1317 PMF_a100_index1kHzPeriodic "PMF ECU: a100 index1k hz periodic";
CM_ SG_ 1317 PMF_a100_index100HzPeriodic "PMF ECU: a100 index100 hz periodic";
CM_ SG_ 1317 PMF_a100_index10HzPeriodic "PMF ECU: a100 index10 hz periodic";
CM_ SG_ 1317 PMF_a100_indexSWI "PMF ECU: a100 index SWI";
CM_ SG_ 1317 PMF_a100_eepEvent "PMF ECU: a100 eep event";
CM_ SG_ 1317 PMF_a100_module500HzActive "PMF ECU: a100 module500 hz active";
CM_ SG_ 1317 PMF_a100_module50HzActive "PMF ECU: a100 module50 hz active";
CM_ SG_ 1317 PMF_a100_module1HzActive "PMF ECU: a100 module1 hz active";
CM_ SG_ 1317 PMF_a100_task10HzActive "PMF ECU: a100 task10 hz active";
CM_ SG_ 1317 PMF_a100_taskUdsActive "PMF ECU: a100 task uds active";
CM_ BO_ 772 "PMF ECU message: alert matrix1";
CM_ SG_ 772 PMF_a001_absoluteTorque "PMF ECU: a001 absolute torque";
CM_ SG_ 772 PMF_a002_excessiveAccelTorque "PMF ECU: a002 excessive accel torque";
CM_ SG_ 772 PMF_a003_excessiveReversalTorque "PMF ECU: a003 excessive reversal torque";
CM_ SG_ 772 PMF_a004_excessiveDecelTorque "PMF ECU: a004 excessive decel torque";
CM_ SG_ 772 PMF_a005_torqueInNeutralOrPark "PMF ECU: a005 torque in neutral or park";
CM_ SG_ 772 PMF_a006_underTorqueCheck "PMF ECU: a006 under torque check";
CM_ SG_ 772 PMF_a008_memoryError "PMF ECU: a008 memory error";
CM_ SG_ 772 PMF_a010_diMIA "PMF ECU: a010 di MIA";
CM_ SG_ 772 PMF_a011_phaseCurrentIrrational "PMF ECU: a011 phase current irrational";
CM_ SG_ 772 PMF_a012_canDataBusA "PMF ECU: a012 can data bus a";
CM_ SG_ 772 PMF_a013_canHardwareBusA "PMF ECU: a013 can hardware bus a";
CM_ SG_ 772 PMF_a017_brakeMIA "PMF ECU: a017 brake MIA";
CM_ SG_ 772 PMF_a018_encoderIrrational "PMF ECU: a018 encoder irrational";
CM_ SG_ 772 PMF_a019_statorTempIrrational "PMF ECU: a019 stator temp irrational";
CM_ SG_ 772 PMF_a025_unintendedReset "PMF ECU: a025 unintended reset";
CM_ SG_ 772 PMF_a026_diHeartBeatMIA "PMF ECU: a026 di heart beat MIA";
CM_ SG_ 772 PMF_a027_torqueEstimationOutOfBo "PMF ECU: a027 torque estimation out of bounds";
CM_ SG_ 772 PMF_a028_torqueCmdError "PMF ECU: a028 torque cmd error";
CM_ SG_ 772 PMF_a031_highStackUsage "PMF ECU: a031 high stack usage";
CM_ SG_ 772 PMF_a032_registerConfigError "PMF ECU: a032 register config error";
CM_ SG_ 772 PMF_a033_selfTest "PMF ECU: a033 self test";
CM_ SG_ 772 PMF_a034_trqCrossCheck "PMF ECU: a034 trq cross check";
CM_ SG_ 772 PMF_a035_udsTransactionInitiated "PMF ECU: a035 uds transaction initiated";
CM_ SG_ 772 PMF_a036_preWatchdog "PMF ECU: a036 pre watchdog";
CM_ SG_ 772 PMF_a037_hvpMIA "PMF ECU: a037 hvp MIA";
CM_ SG_ 772 PMF_a039_disMIA "PMF ECU: a039 dis MIA";
CM_ SG_ 772 PMF_a040_pmMIA "PMF ECU: a040 pm MIA";
CM_ SG_ 772 PMF_a042_gtwMIA "PMF ECU: a042 gtw MIA";
CM_ SG_ 772 PMF_a045_motorMovementDetected "PMF ECU: a045 motor movement detected";
CM_ SG_ 772 PMF_a053_vcfrontMIA "PMF ECU: a053 vcfront MIA";
CM_ SG_ 772 PMF_a054_uiMIA "PMF ECU: a054 ui MIA";
CM_ SG_ 772 PMF_a055_resolver "PMF ECU: a055 resolver";
CM_ SG_ 772 PMF_a056_canHardwareBusB "PMF ECU: a056 can hardware bus b";
CM_ SG_ 772 PMF_a057_canDataBusB "PMF ECU: a057 can data bus b";
CM_ SG_ 772 PMF_a058_measuredHvilCurrentFroz "PMF ECU: a058 measured hvil current frozen";
CM_ SG_ 772 PMF_a061_DIPMVersionMismatch "PMF ECU: a061 DIPM version mismatch";
CM_ SG_ 772 PMF_a062_eccError "PMF ECU: a062 ecc error";
CM_ SG_ 772 PMF_a064_torqueIntervention "PMF ECU: a064 torque intervention";
CM_ BO_ 2022 "PMF ECU message: alert matrix2";
CM_ SG_ 2022 PMF_a080_exceptionPrefetchAbort "PMF ECU: a080 exception prefetch abort";
CM_ SG_ 2022 PMF_a081_exceptionDataAbort "PMF ECU: a081 exception data abort";
CM_ SG_ 2022 PMF_a082_exceptionDataAbort2 "PMF ECU: a082 exception data abort2";
CM_ SG_ 2022 PMF_a083_ahbWriteError "PMF ECU: a083 ahb write error";
CM_ SG_ 2022 PMF_a084_exceptionMpuFirewall "PMF ECU: a084 exception mpu firewall";
CM_ SG_ 2022 PMF_a086_exceptionUndefinedInstr "PMF ECU: a086 exception undefined instruction";
CM_ SG_ 2022 PMF_a092_xtalOscillator "PMF ECU: a092 xtal oscillator";
CM_ SG_ 2022 PMF_a094_safetyICWarn "PMF ECU: a094 safety IC warn";
CM_ SG_ 2022 PMF_a095_safetyICFault "PMF ECU: a095 safety IC fault";
CM_ SG_ 2022 PMF_a096_safetyICDebug "PMF ECU: a096 safety IC debug";
CM_ SG_ 2022 PMF_a097_lowFlowAlmostTripped "PMF ECU: a097 low flow almost tripped";
CM_ SG_ 2022 PMF_a100_diTraceInfo1 "PMF ECU: a100 di trace info1";
CM_ SG_ 2022 PMF_a121_unintendedReset2 "PMF ECU: a121 unintended reset2";
CM_ BO_ 790 "PMF ECU message: info";
CM_ SG_ 790 PMF_infoIndex "PMF ECU: info index";
CM_ SG_ 790 PMF_buildType "PMF ECU: build type";
CM_ SG_ 790 PMF_buildConfigurationId "PMF ECU: build configuration id";
CM_ SG_ 790 PMF_hardwareId "PMF ECU: hardware id";
CM_ SG_ 790 PMF_deviceFused "PMF ECU: device fused";
CM_ SG_ 790 PMF_componentId "PMF ECU: component id";
CM_ SG_ 790 PMF_pcbaId "PMF ECU: pcba id";
CM_ SG_ 790 PMF_assemblyId "PMF ECU: assembly id";
CM_ SG_ 790 PMF_usageId "PMF ECU: usage id";
CM_ SG_ 790 PMF_subUsageId "PMF ECU: sub usage id";
CM_ SG_ 790 PMF_applicationCrc "PMF ECU: application crc";
CM_ SG_ 790 PMF_appGitHash "PMF ECU: app git hash";
CM_ SG_ 790 PMF_bootGitHash "PMF ECU: boot git hash";
CM_ SG_ 790 PMF_platformTyp "PMF ECU: platform typ";
CM_ SG_ 790 PMF_udsProtocolVersion "PMF ECU: uds protocol version";
CM_ SG_ 790 PMF_bootloaderCrc "PMF ECU: bootloader crc";
CM_ BO_ 1316 "PMF ECU message: mfg data";
CM_ SG_ 1316 PMF_processorDieIdLot "PMF ECU: processor die id lot";
CM_ SG_ 1316 PMF_processorDieIdWafer "PMF ECU: processor die id wafer";
CM_ SG_ 1316 PMF_processorDieIdX "PMF ECU: processor die id x";
CM_ SG_ 1316 PMF_processorDieIdY "PMF ECU: processor die id y";
CM_ BO_ 1446 "PMR ECU message: alert log";
CM_ SG_ 1446 PMR_alertID "PMR ECU: alert ID";
CM_ SG_ 1446 PMR_alertState "PMR ECU: alert state";
CM_ SG_ 1446 PMR_a001_w0 "PMR ECU: a001 w0";
CM_ SG_ 1446 PMR_a001_w1 "PMR ECU: a001 w1";
CM_ SG_ 1446 PMR_a001_w2 "PMR ECU: a001 w2";
CM_ SG_ 1446 PMR_a002_torqueAverage "PMR ECU: a002 torque average";
CM_ SG_ 1446 PMR_a002_torqueWindow "PMR ECU: a002 torque window";
CM_ SG_ 1446 PMR_a002_torqueMeasured "PMR ECU: a002 torque measured";
CM_ SG_ 1446 PMR_a002_torqueAccelAverage "PMR ECU: a002 torque accel average";
CM_ SG_ 1446 PMR_a002_torqueAccelWindow "PMR ECU: a002 torque accel window";
CM_ SG_ 1446 PMR_a003_reverseGear "PMR ECU: a003 reverse gear";
CM_ SG_ 1446 PMR_a003_pedalPos "PMR ECU: a003 pedal pos";
CM_ SG_ 1446 PMR_a003_zeroPointPedal "PMR ECU: a003 zero point pedal";
CM_ SG_ 1446 PMR_a004_torqueAverage "PMR ECU: a004 torque average";
CM_ SG_ 1446 PMR_a004_torqueWindow "PMR ECU: a004 torque window";
CM_ SG_ 1446 PMR_a004_torqueMeasured "PMR ECU: a004 torque measured";
CM_ SG_ 1446 PMR_a004_torqueDecelAverage "PMR ECU: a004 torque decel average";
CM_ SG_ 1446 PMR_a004_torqueDecelWindow "PMR ECU: a004 torque decel window";
CM_ SG_ 1446 PMR_a005_torqueReason "PMR ECU: a005 torque reason";
CM_ SG_ 1446 PMR_a005_torqueMeasured "PMR ECU: a005 torque measured";
CM_ SG_ 1446 PMR_a005_iDQmagnitude "PMR ECU: a005 i d qmagnitude";
CM_ SG_ 1446 PMR_a006_torqueActual "PMR ECU: a006 torque actual";
CM_ SG_ 1446 PMR_a006_motorRPM "PMR ECU: a006 motor RPM";
CM_ SG_ 1446 PMR_a006_torqueMeasured "PMR ECU: a006 torque measured";
CM_ SG_ 1446 PMR_a010_messageId "PMR ECU: a010 message id";
CM_ SG_ 1446 PMR_a010_DI_status "PMR ECU: a010 DI status";
CM_ SG_ 1446 PMR_a010_DI_torque "PMR ECU: a010 DI torque";
CM_ SG_ 1446 PMR_a010_DI_slaveCommand "PMR ECU: a010 DI slave command";
CM_ SG_ 1446 PMR_a010_DI_locStatus "PMR ECU: a010 DI loc status";
CM_ SG_ 1446 PMR_a010_DI_speed "PMR ECU: a010 DI speed";
CM_ SG_ 1446 PMR_a010_DI_systemStatus "PMR ECU: a010 DI system status";
CM_ SG_ 1446 PMR_a010_DI_chassisControl "PMR ECU: a010 DI chassis control";
CM_ SG_ 1446 PMR_a010_DI_chassisControl2 "PMR ECU: a010 DI chassis control2";
CM_ SG_ 1446 PMR_a010_vdcLeft "PMR ECU: a010 vdc left";
CM_ SG_ 1446 PMR_a010_vdcRight "PMR ECU: a010 vdc right";
CM_ SG_ 1446 PMR_a010_DI_vehicleEstimates "PMR ECU: a010 DI vehicle estimates";
CM_ SG_ 1446 PMR_a010_DI_brakeCommand "PMR ECU: a010 DI brake command";
CM_ SG_ 1446 PMR_a010_DI_difCommand "PMR ECU: a010 DI dif command";
CM_ SG_ 1446 PMR_a010_DI_dirCommand "PMR ECU: a010 DI dir command";
CM_ SG_ 1446 PMR_a010_DI_dirVehicle "PMR ECU: a010 DI dir vehicle";
CM_ SG_ 1446 PMR_a010_DI_locStatus2 "PMR ECU: a010 DI loc status2";
CM_ SG_ 1446 PMR_a011_Ia "PMR ECU: a011 ia";
CM_ SG_ 1446 PMR_a011_Ib "PMR ECU: a011 ib";
CM_ SG_ 1446 PMR_a011_currentVref "PMR ECU: a011 current vref";
CM_ SG_ 1446 PMR_a011_badPhaseAsample "PMR ECU: a011 bad phase asample";
CM_ SG_ 1446 PMR_a011_badPhaseBsample "PMR ECU: a011 bad phase bsample";
CM_ SG_ 1446 PMR_a011_sampleFreeze "PMR ECU: a011 sample freeze";
CM_ SG_ 1446 PMR_a012_canID "PMR ECU: a012 can ID";
CM_ SG_ 1446 PMR_a012_errorType "PMR ECU: a012 error type";
CM_ SG_ 1446 PMR_a012_badValue1 "PMR ECU: a012 bad value1";
CM_ SG_ 1446 PMR_a012_badValue2 "PMR ECU: a012 bad value2";
CM_ SG_ 1446 PMR_a013_mailboxID "PMR ECU: a013 mailbox ID";
CM_ SG_ 1446 PMR_a013_canID "PMR ECU: a013 can ID";
CM_ SG_ 1446 PMR_a013_errorType "PMR ECU: a013 error type";
CM_ SG_ 1446 PMR_a017_EPBL_status "PMR ECU: a017 EPBL status";
CM_ SG_ 1446 PMR_a017_EPBR_status "PMR ECU: a017 EPBR status";
CM_ SG_ 1446 PMR_a018_w0 "PMR ECU: a018 w0";
CM_ SG_ 1446 PMR_a018_w1 "PMR ECU: a018 w1";
CM_ SG_ 1446 PMR_a018_w2 "PMR ECU: a018 w2";
CM_ SG_ 1446 PMR_a019_statorTemp1 "PMR ECU: a019 stator temp1";
CM_ SG_ 1446 PMR_a019_statorTslope1 "PMR ECU: a019 stator tslope1";
CM_ SG_ 1446 PMR_a025_sccReset "PMR ECU: a025 scc reset";
CM_ SG_ 1446 PMR_a025_hibernate "PMR ECU: a025 hibernate";
CM_ SG_ 1446 PMR_a025_hwBist "PMR ECU: a025 hw bist";
CM_ SG_ 1446 PMR_a025_nmiWatchdog "PMR ECU: a025 nmi watchdog";
CM_ SG_ 1446 PMR_a025_watchdog "PMR ECU: a025 watchdog";
CM_ SG_ 1446 PMR_a025_clockFailNmi "PMR ECU: a025 clock fail nmi";
CM_ SG_ 1446 PMR_a025_ramUncErrorNmi "PMR ECU: a025 ram unc error nmi";
CM_ SG_ 1446 PMR_a025_flashUncErrorNmi "PMR ECU: a025 flash unc error nmi";
CM_ SG_ 1446 PMR_a025_cpu1signMismatchNmi "PMR ECU: a025 cpu1sign mismatch nmi";
CM_ SG_ 1446 PMR_a025_cpu2signMismatchNmi "PMR ECU: a025 cpu2sign mismatch nmi";
CM_ SG_ 1446 PMR_a025_pieVectErrorNmi "PMR ECU: a025 pie vect error nmi";
CM_ SG_ 1446 PMR_a025_sysDbgNmi "PMR ECU: a025 sys dbg nmi";
CM_ SG_ 1446 PMR_a025_rlNmi "PMR ECU: a025 rl nmi";
CM_ SG_ 1446 PMR_a025_ovfNmi "PMR ECU: a025 ovf nmi";
CM_ SG_ 1446 PMR_a025_possibleSafetyICReset "PMR ECU: a025 possible safety IC reset";
CM_ SG_ 1446 PMR_a025_powerOnReset "PMR ECU: a025 power on reset";
CM_ SG_ 1446 PMR_a025_watchdogTimer0 "PMR ECU: a025 watchdog timer0";
CM_ SG_ 1446 PMR_a025_watchdogTimer1 "PMR ECU: a025 watchdog timer1";
CM_ SG_ 1446 PMR_a025_watchdogTimer2 "PMR ECU: a025 watchdog timer2";
CM_ SG_ 1446 PMR_a025_watchdogTimer3 "PMR ECU: a025 watchdog timer3";
CM_ SG_ 1446 PMR_a025_warmResetReq "PMR ECU: a025 warm reset req";
CM_ SG_ 1446 PMR_a025_externalPadReset "PMR ECU: a025 external pad reset";
CM_ SG_ 1446 PMR_a025_hwSecModuleWatchdogTime "PMR ECU: a025 hw sec module watchdog timer";
CM_ SG_ 1446 PMR_a025_debugReset "PMR ECU: a025 debug reset";
CM_ SG_ 1446 PMR_a025_tempSense0 "PMR ECU: a025 temp sense0";
CM_ SG_ 1446 PMR_a025_tempSense1 "PMR ECU: a025 temp sense1";
CM_ SG_ 1446 PMR_a026_reason "PMR ECU: a026 reason";
CM_ SG_ 1446 PMR_a026_isrCount20kHz "PMR ECU: a026 isr count20k hz";
CM_ SG_ 1446 PMR_a026_isrCount1kHz "PMR ECU: a026 isr count1k hz";
CM_ SG_ 1446 PMR_a026_switchingActive "PMR ECU: a026 switching active";
CM_ SG_ 1446 PMR_a026_systemStackOvf "PMR ECU: a026 system stack ovf";
CM_ SG_ 1446 PMR_a026_controlStackOvf "PMR ECU: a026 control stack ovf";
CM_ SG_ 1446 PMR_a026_idleStackOvf "PMR ECU: a026 idle stack ovf";
CM_ SG_ 1446 PMR_a026_eepStackOvf "PMR ECU: a026 eep stack ovf";
CM_ SG_ 1446 PMR_a026_immStackOvf "PMR ECU: a026 imm stack ovf";
CM_ SG_ 1446 PMR_a026_xdcErrorIdMSW "PMR ECU: a026 xdc error id MSW";
CM_ SG_ 1446 PMR_a026_xdcErrorArg1 "PMR ECU: a026 xdc error arg1";
CM_ SG_ 1446 PMR_a032_w0 "PMR ECU: a032 w0";
CM_ SG_ 1446 PMR_a032_w1 "PMR ECU: a032 w1";
CM_ SG_ 1446 PMR_a032_w2 "PMR ECU: a032 w2";
CM_ SG_ 1446 PMR_a033_state "PMR ECU: a033 state";
CM_ SG_ 1446 PMR_a033_failReason "PMR ECU: a033 fail reason";
CM_ SG_ 1446 PMR_a033_DSADC_Ia "PMR ECU: a033 DSADC ia";
CM_ SG_ 1446 PMR_a033_DSADC_Ib "PMR ECU: a033 DSADC ib";
CM_ SG_ 1446 PMR_a036_timeSinceTxHWI "PMR ECU: a036 time since tx HWI";
CM_ SG_ 1446 PMR_a036_timeSinceRxHWI "PMR ECU: a036 time since rx HWI";
CM_ SG_ 1446 PMR_a036_timeSince100HzTxSWI "PMR ECU: a036 time since100 hz tx SWI";
CM_ SG_ 1446 PMR_a036_timeSince1kHzCLK "PMR ECU: a036 time since1k hz CLK";
CM_ SG_ 1446 PMR_a036_timeSince1kHzSWI "PMR ECU: a036 time since1k hz SWI";
CM_ SG_ 1446 PMR_a036_timeSinceIdle "PMR ECU: a036 time since idle";
CM_ SG_ 1446 PMR_a036_ovfStackId "PMR ECU: a036 ovf stack id";
CM_ SG_ 1446 PMR_a036_inTxISR "PMR ECU: a036 in tx ISR";
CM_ SG_ 1446 PMR_a036_inTxHWI "PMR ECU: a036 in tx HWI";
CM_ SG_ 1446 PMR_a036_inRxHWI "PMR ECU: a036 in rx HWI";
CM_ SG_ 1446 PMR_a036_in1kHzSWI "PMR ECU: a036 in1k hz SWI";
CM_ SG_ 1446 PMR_a036_in1kHzCLK "PMR ECU: a036 in1k hz CLK";
CM_ SG_ 1446 PMR_a036_in100HzCLK "PMR ECU: a036 in100 hz CLK";
CM_ SG_ 1446 PMR_a036_in10HzCLK "PMR ECU: a036 in10 hz CLK";
CM_ SG_ 1446 PMR_a036_in1HzCLK "PMR ECU: a036 in1 hz CLK";
CM_ SG_ 1446 PMR_a037_hvpFaults "PMR ECU: a037 hvp faults";
CM_ SG_ 1446 PMR_a039_DIS_status "PMR ECU: a039 DIS status";
CM_ SG_ 1446 PMR_a039_DIS_torque "PMR ECU: a039 DIS torque";
CM_ SG_ 1446 PMR_a039_messageId "PMR ECU: a039 message id";
CM_ SG_ 1446 PMR_a040_PM_state "PMR ECU: a040 PM state";
CM_ SG_ 1446 PMR_a040_messageId "PMR ECU: a040 message id";
CM_ SG_ 1446 PMR_a040_PM_locState "PMR ECU: a040 PM loc state";
CM_ SG_ 1446 PMR_a042_GTW_carConfig "PMR ECU: a042 GTW car config";
CM_ SG_ 1446 PMR_a042_GTW_time "PMR ECU: a042 GTW time";
CM_ SG_ 1446 PMR_a042_GTW_drivetrainType "PMR ECU: a042 GTW drivetrain type";
CM_ SG_ 1446 PMR_a042_expectedPerformanceCfg "PMR ECU: a042 expected performance cfg";
CM_ SG_ 1446 PMR_a042_gearControl "PMR ECU: a042 gear control";
CM_ SG_ 1446 PMR_a053_LVPowerState "PMR ECU: a053 LV power state";
CM_ SG_ 1446 PMR_a053_coolant "PMR ECU: a053 coolant";
CM_ SG_ 1446 PMR_a053_vcleftSwitchStatus "PMR ECU: a053 vcleft switch status";
CM_ SG_ 1446 PMR_a053_restraintStatus "PMR ECU: a053 restraint status";
CM_ SG_ 1446 PMR_a053_sensors "PMR ECU: a053 sensors";
CM_ SG_ 1446 PMR_a054_uiPowertrainControl "PMR ECU: a054 ui powertrain control";
CM_ SG_ 1446 PMR_a054_uiChassisControl "PMR ECU: a054 ui chassis control";
CM_ SG_ 1446 PMR_a054_uiCruiseControl "PMR ECU: a054 ui cruise control";
CM_ SG_ 1446 PMR_a054_uiTrackModeSettings "PMR ECU: a054 ui track mode settings";
CM_ SG_ 1446 PMR_a054_uiTPMSRCPSetting "PMR ECU: a054 ui TPMSRCP setting";
CM_ SG_ 1446 PMR_a055_motorRPM "PMR ECU: a055 motor RPM";
CM_ SG_ 1446 PMR_a055_phaseAngle "PMR ECU: a055 phase angle";
CM_ SG_ 1446 PMR_a055_commonGain "PMR ECU: a055 common gain";
CM_ SG_ 1446 PMR_a055_notReady "PMR ECU: a055 not ready";
CM_ SG_ 1446 PMR_a055_noCarrier "PMR ECU: a055 no carrier";
CM_ SG_ 1446 PMR_a055_phaseOutOfSpec "PMR ECU: a055 phase out of spec";
CM_ SG_ 1446 PMR_a055_diElecAngleMismatch "PMR ECU: a055 di elec angle mismatch";
CM_ SG_ 1446 PMR_a055_diSpeedMismatch "PMR ECU: a055 di speed mismatch";
CM_ SG_ 1446 PMR_a055_claMIA "PMR ECU: a055 cla MIA";
CM_ SG_ 1446 PMR_a055_diMIA "PMR ECU: a055 di MIA";
CM_ SG_ 1446 PMR_a055_diElecAngleMismatchWarn "PMR ECU: a055 di elec angle mismatch warn";
CM_ SG_ 1446 PMR_a056_mailboxID "PMR ECU: a056 mailbox ID";
CM_ SG_ 1446 PMR_a056_canID "PMR ECU: a056 can ID";
CM_ SG_ 1446 PMR_a056_errorType "PMR ECU: a056 error type";
CM_ SG_ 1446 PMR_a057_canID "PMR ECU: a057 can ID";
CM_ SG_ 1446 PMR_a057_errorType "PMR ECU: a057 error type";
CM_ SG_ 1446 PMR_a057_badValue1 "PMR ECU: a057 bad value1";
CM_ SG_ 1446 PMR_a057_badValue2 "PMR ECU: a057 bad value2";
CM_ SG_ 1446 PMR_a058_hvilCurrent "PMR ECU: a058 hvil current";
CM_ SG_ 1446 PMR_a061_diIpcVersion "PMR ECU: a061 di ipc version";
CM_ SG_ 1446 PMR_a061_pmIpcVersion "PMR ECU: a061 pm ipc version";
CM_ SG_ 1446 PMR_a062_address "PMR ECU: a062 address";
CM_ SG_ 1446 PMR_a062_errorType "PMR ECU: a062 error type";
CM_ SG_ 1446 PMR_a064_interventionType "PMR ECU: a064 intervention type";
CM_ SG_ 1446 PMR_a064_torqueCmdState "PMR ECU: a064 torque cmd state";
CM_ SG_ 1446 PMR_a064_shortDetectedByDI "PMR ECU: a064 short detected by DI";
CM_ SG_ 1446 PMR_a064_UI_stoppingMode "PMR ECU: a064 UI stopping mode";
CM_ SG_ 1446 PMR_a064_diCrsState "PMR ECU: a064 di crs state";
CM_ SG_ 1446 PMR_a064_pmCrsState "PMR ECU: a064 pm crs state";
CM_ SG_ 1446 PMR_a082_faultAddress "PMR ECU: a082 fault address";
CM_ SG_ 1446 PMR_a082_isWriteNotRead "PMR ECU: a082 is write not read";
CM_ SG_ 1446 PMR_a084_faultAddress "PMR ECU: a084 fault address";
CM_ SG_ 1446 PMR_a084_firewallId "PMR ECU: a084 firewall id";
CM_ SG_ 1446 PMR_a084_privId "PMR ECU: a084 priv id";
CM_ SG_ 1446 PMR_a084_ns "PMR ECU: a084 ns";
CM_ SG_ 1446 PMR_a084_faultType "PMR ECU: a084 fault type";
CM_ SG_ 1446 PMR_a092_pllClockSource "PMR ECU: a092 pll clock source";
CM_ SG_ 1446 PMR_a100_index1kHzPeriodic "PMR ECU: a100 index1k hz periodic";
CM_ SG_ 1446 PMR_a100_index100HzPeriodic "PMR ECU: a100 index100 hz periodic";
CM_ SG_ 1446 PMR_a100_index10HzPeriodic "PMR ECU: a100 index10 hz periodic";
CM_ SG_ 1446 PMR_a100_indexSWI "PMR ECU: a100 index SWI";
CM_ SG_ 1446 PMR_a100_eepEvent "PMR ECU: a100 eep event";
CM_ SG_ 1446 PMR_a100_module500HzActive "PMR ECU: a100 module500 hz active";
CM_ SG_ 1446 PMR_a100_module50HzActive "PMR ECU: a100 module50 hz active";
CM_ SG_ 1446 PMR_a100_module1HzActive "PMR ECU: a100 module1 hz active";
CM_ SG_ 1446 PMR_a100_task10HzActive "PMR ECU: a100 task10 hz active";
CM_ SG_ 1446 PMR_a100_taskUdsActive "PMR ECU: a100 task uds active";
CM_ SG_ 1446 PMR_a101_VDDA18_ref33_uv "PMR ECU: a101 VDDA18 ref33 uv";
CM_ SG_ 1446 PMR_a101_VBGAP09_ov "PMR ECU: a101 VBGAP09 ov";
CM_ SG_ 1446 PMR_a101_VBGAP09_uv "PMR ECU: a101 VBGAP09 uv";
CM_ SG_ 1446 PMR_a101_VDDA18_refBGAP_ov "PMR ECU: a101 VDDA18 ref BGAP ov";
CM_ SG_ 1446 PMR_a101_VDDA18_refBGAP_uv "PMR ECU: a101 VDDA18 ref BGAP uv";
CM_ SG_ 1446 PMR_a101_VDD12_ov "PMR ECU: a101 VDD12 ov";
CM_ SG_ 1446 PMR_a101_VDD12_uv "PMR ECU: a101 VDD12 uv";
CM_ SG_ 1446 PMR_a101_VDDSBIO_ov "PMR ECU: a101 VDDSBIO ov";
CM_ SG_ 1446 PMR_a101_VDDSBIO_uv "PMR ECU: a101 VDDSBIO uv";
CM_ SG_ 1446 PMR_a101_VSYS_MON_uv "PMR ECU: a101 VSYS MON uv";
CM_ SG_ 1446 PMR_a101_VDDA33_uv "PMR ECU: a101 VDDA33 uv";
CM_ SG_ 1446 PMR_a101_ADC0_REF_ov "PMR ECU: a101 ADC0 REF ov";
CM_ SG_ 1446 PMR_a101_ADC0_REF_uv "PMR ECU: a101 ADC0 REF uv";
CM_ SG_ 1446 PMR_a101_ADC12_REF_ov "PMR ECU: a101 ADC12 REF ov";
CM_ SG_ 1446 PMR_a101_ADC12_REF_uv "PMR ECU: a101 ADC12 REF uv";
CM_ SG_ 1446 PMR_a101_ADC34_REF_ov "PMR ECU: a101 ADC34 REF ov";
CM_ SG_ 1446 PMR_a101_ADC34_REF_uv "PMR ECU: a101 ADC34 REF uv";
CM_ SG_ 1446 PMR_a101_ADCR01_REF_ov "PMR ECU: a101 ADCR01 REF ov";
CM_ SG_ 1446 PMR_a101_ADCR01_REF_uv "PMR ECU: a101 ADCR01 REF uv";
CM_ BO_ 902 "PMR ECU message: alert matrix1";
CM_ SG_ 902 PMR_a001_absoluteTorque "PMR ECU: a001 absolute torque";
CM_ SG_ 902 PMR_a002_excessiveAccelTorque "PMR ECU: a002 excessive accel torque";
CM_ SG_ 902 PMR_a003_excessiveReversalTorque "PMR ECU: a003 excessive reversal torque";
CM_ SG_ 902 PMR_a004_excessiveDecelTorque "PMR ECU: a004 excessive decel torque";
CM_ SG_ 902 PMR_a005_torqueInNeutralOrPark "PMR ECU: a005 torque in neutral or park";
CM_ SG_ 902 PMR_a006_underTorqueCheck "PMR ECU: a006 under torque check";
CM_ SG_ 902 PMR_a008_memoryError "PMR ECU: a008 memory error";
CM_ SG_ 902 PMR_a010_diMIA "PMR ECU: a010 di MIA";
CM_ SG_ 902 PMR_a011_phaseCurrentIrrational "PMR ECU: a011 phase current irrational";
CM_ SG_ 902 PMR_a012_canDataBusA "PMR ECU: a012 can data bus a";
CM_ SG_ 902 PMR_a013_canHardwareBusA "PMR ECU: a013 can hardware bus a";
CM_ SG_ 902 PMR_a017_brakeMIA "PMR ECU: a017 brake MIA";
CM_ SG_ 902 PMR_a018_encoderIrrational "PMR ECU: a018 encoder irrational";
CM_ SG_ 902 PMR_a019_statorTempIrrational "PMR ECU: a019 stator temp irrational";
CM_ SG_ 902 PMR_a025_unintendedReset "PMR ECU: a025 unintended reset";
CM_ SG_ 902 PMR_a026_diHeartBeatMIA "PMR ECU: a026 di heart beat MIA";
CM_ SG_ 902 PMR_a027_torqueEstimationOutOfBo "PMR ECU: a027 torque estimation out of bounds";
CM_ SG_ 902 PMR_a028_torqueCmdError "PMR ECU: a028 torque cmd error";
CM_ SG_ 902 PMR_a031_highStackUsage "PMR ECU: a031 high stack usage";
CM_ SG_ 902 PMR_a032_registerConfigError "PMR ECU: a032 register config error";
CM_ SG_ 902 PMR_a033_selfTest "PMR ECU: a033 self test";
CM_ SG_ 902 PMR_a034_trqCrossCheck "PMR ECU: a034 trq cross check";
CM_ SG_ 902 PMR_a035_udsTransactionInitiated "PMR ECU: a035 uds transaction initiated";
CM_ SG_ 902 PMR_a036_preWatchdog "PMR ECU: a036 pre watchdog";
CM_ SG_ 902 PMR_a037_hvpMIA "PMR ECU: a037 hvp MIA";
CM_ SG_ 902 PMR_a039_disMIA "PMR ECU: a039 dis MIA";
CM_ SG_ 902 PMR_a040_pmMIA "PMR ECU: a040 pm MIA";
CM_ SG_ 902 PMR_a042_gtwMIA "PMR ECU: a042 gtw MIA";
CM_ SG_ 902 PMR_a045_motorMovementDetected "PMR ECU: a045 motor movement detected";
CM_ SG_ 902 PMR_a053_vcfrontMIA "PMR ECU: a053 vcfront MIA";
CM_ SG_ 902 PMR_a054_uiMIA "PMR ECU: a054 ui MIA";
CM_ SG_ 902 PMR_a055_resolver "PMR ECU: a055 resolver";
CM_ SG_ 902 PMR_a056_canHardwareBusB "PMR ECU: a056 can hardware bus b";
CM_ SG_ 902 PMR_a057_canDataBusB "PMR ECU: a057 can data bus b";
CM_ SG_ 902 PMR_a058_measuredHvilCurrentFroz "PMR ECU: a058 measured hvil current frozen";
CM_ SG_ 902 PMR_a061_DIPMVersionMismatch "PMR ECU: a061 DIPM version mismatch";
CM_ SG_ 902 PMR_a062_eccError "PMR ECU: a062 ecc error";
CM_ SG_ 902 PMR_a064_torqueIntervention "PMR ECU: a064 torque intervention";
CM_ BO_ 928 "PMR ECU message: alert matrix2";
CM_ SG_ 928 PMR_a080_exceptionPrefetchAbort "PMR ECU: a080 exception prefetch abort";
CM_ SG_ 928 PMR_a081_exceptionDataAbort "PMR ECU: a081 exception data abort";
CM_ SG_ 928 PMR_a082_exceptionDataAbort2 "PMR ECU: a082 exception data abort2";
CM_ SG_ 928 PMR_a083_ahbWriteError "PMR ECU: a083 ahb write error";
CM_ SG_ 928 PMR_a084_exceptionMpuFirewall "PMR ECU: a084 exception mpu firewall";
CM_ SG_ 928 PMR_a086_exceptionUndefinedInstr "PMR ECU: a086 exception undefined instruction";
CM_ SG_ 928 PMR_a092_xtalOscillator "PMR ECU: a092 xtal oscillator";
CM_ SG_ 928 PMR_a094_safetyICWarn "PMR ECU: a094 safety IC warn";
CM_ SG_ 928 PMR_a095_safetyICFault "PMR ECU: a095 safety IC fault";
CM_ SG_ 928 PMR_a096_safetyICDebug "PMR ECU: a096 safety IC debug";
CM_ SG_ 928 PMR_a097_lowFlowAlmostTripped "PMR ECU: a097 low flow almost tripped";
CM_ SG_ 928 PMR_a100_diTraceInfo1 "PMR ECU: a100 di trace info1";
CM_ SG_ 928 PMR_a101_hwVoltageMonitorTrip "PMR ECU: a101 hw voltage monitor trip";
CM_ SG_ 928 PMR_a121_unintendedReset2 "PMR ECU: a121 unintended reset2";
CM_ BO_ 1748 "PMR ECU message: info";
CM_ SG_ 1748 PMR_infoIndex "PMR ECU: info index";
CM_ SG_ 1748 PMR_buildType "PMR ECU: build type";
CM_ SG_ 1748 PMR_buildConfigurationId "PMR ECU: build configuration id";
CM_ SG_ 1748 PMR_hardwareId "PMR ECU: hardware id";
CM_ SG_ 1748 PMR_deviceFused "PMR ECU: device fused";
CM_ SG_ 1748 PMR_componentId "PMR ECU: component id";
CM_ SG_ 1748 PMR_pcbaId "PMR ECU: pcba id";
CM_ SG_ 1748 PMR_assemblyId "PMR ECU: assembly id";
CM_ SG_ 1748 PMR_usageId "PMR ECU: usage id";
CM_ SG_ 1748 PMR_subUsageId "PMR ECU: sub usage id";
CM_ SG_ 1748 PMR_applicationCrc "PMR ECU: application crc";
CM_ SG_ 1748 PMR_appGitHash "PMR ECU: app git hash";
CM_ SG_ 1748 PMR_bootGitHash "PMR ECU: boot git hash";
CM_ SG_ 1748 PMR_platformTyp "PMR ECU: platform typ";
CM_ SG_ 1748 PMR_udsProtocolVersion "PMR ECU: uds protocol version";
CM_ SG_ 1748 PMR_bootloaderCrc "PMR ECU: bootloader crc";
CM_ BO_ 2021 "PMR ECU message: mfg data";
CM_ SG_ 2021 PMR_processorDieIdLot "PMR ECU: processor die id lot";
CM_ SG_ 2021 PMR_processorDieIdWafer "PMR ECU: processor die id wafer";
CM_ SG_ 2021 PMR_processorDieIdX "PMR ECU: processor die id x";
CM_ SG_ 2021 PMR_processorDieIdY "PMR ECU: processor die id y";
CM_ BO_ 1444 "PM ECU message: alert log";
CM_ SG_ 1444 PM_alertID "PM ECU: alert ID";
CM_ SG_ 1444 PM_alertState "PM ECU: alert state";
CM_ SG_ 1444 PM_a001_w0 "PM ECU: a001 w0";
CM_ SG_ 1444 PM_a001_w1 "PM ECU: a001 w1";
CM_ SG_ 1444 PM_a001_w2 "PM ECU: a001 w2";
CM_ SG_ 1444 PM_a002_torqueAverage "PM ECU: a002 torque average";
CM_ SG_ 1444 PM_a002_torqueWindow "PM ECU: a002 torque window";
CM_ SG_ 1444 PM_a002_torqueMeasured "PM ECU: a002 torque measured";
CM_ SG_ 1444 PM_a002_torqueAccelAverage "PM ECU: a002 torque accel average";
CM_ SG_ 1444 PM_a002_torqueAccelWindow "PM ECU: a002 torque accel window";
CM_ SG_ 1444 PM_a003_reverseGear "PM ECU: a003 reverse gear";
CM_ SG_ 1444 PM_a003_pedalPos "PM ECU: a003 pedal pos";
CM_ SG_ 1444 PM_a003_zeroPointPedal "PM ECU: a003 zero point pedal";
CM_ SG_ 1444 PM_a004_torqueAverage "PM ECU: a004 torque average";
CM_ SG_ 1444 PM_a004_torqueWindow "PM ECU: a004 torque window";
CM_ SG_ 1444 PM_a004_torqueMeasured "PM ECU: a004 torque measured";
CM_ SG_ 1444 PM_a004_torqueDecelAverage "PM ECU: a004 torque decel average";
CM_ SG_ 1444 PM_a004_torqueDecelWindow "PM ECU: a004 torque decel window";
CM_ SG_ 1444 PM_a005_torqueReason "PM ECU: a005 torque reason";
CM_ SG_ 1444 PM_a005_torqueMeasured "PM ECU: a005 torque measured";
CM_ SG_ 1444 PM_a005_iDQmagnitude "PM ECU: a005 i d qmagnitude";
CM_ SG_ 1444 PM_a006_unknownGearAllowed "PM ECU: a006 unknown gear allowed";
CM_ SG_ 1444 PM_a006_parkGearAllowed "PM ECU: a006 park gear allowed";
CM_ SG_ 1444 PM_a006_reverseGearAllowed "PM ECU: a006 reverse gear allowed";
CM_ SG_ 1444 PM_a006_neutralGearAllowed "PM ECU: a006 neutral gear allowed";
CM_ SG_ 1444 PM_a006_driveGearAllowed "PM ECU: a006 drive gear allowed";
CM_ SG_ 1444 PM_a006_shiftState "PM ECU: a006 shift state";
CM_ SG_ 1444 PM_a006_brakePedalPress "PM ECU: a006 brake pedal press";
CM_ SG_ 1444 PM_a006_accelPedalBelowLimit "PM ECU: a006 accel pedal below limit";
CM_ SG_ 1444 PM_a006_allowReverseShiftSpeed "PM ECU: a006 allow reverse shift speed";
CM_ SG_ 1444 PM_a006_allowDriveShiftSpeed "PM ECU: a006 allow drive shift speed";
CM_ SG_ 1444 PM_a006_requireAccelPedalCheckSp "PM ECU: a006 require accel pedal check speed";
CM_ SG_ 1444 PM_a006_requireParkSpeed "PM ECU: a006 require park speed";
CM_ SG_ 1444 PM_a006_stalkCommandP "PM ECU: a006 stalk command p";
CM_ SG_ 1444 PM_a006_stalkCommandR "PM ECU: a006 stalk command r";
CM_ SG_ 1444 PM_a006_stalkCommandN "PM ECU: a006 stalk command n";
CM_ SG_ 1444 PM_a006_stalkCommandD "PM ECU: a006 stalk command d";
CM_ SG_ 1444 PM_a006_unsecuredNeutralRequest "PM ECU: a006 unsecured neutral request";
CM_ SG_ 1444 PM_a006_recentGearChange "PM ECU: a006 recent gear change";
CM_ SG_ 1444 PM_a006_smartShiftCommandD "PM ECU: a006 smart shift command d";
CM_ SG_ 1444 PM_a006_smartShiftCommandR "PM ECU: a006 smart shift command r";
CM_ SG_ 1444 PM_a006_driverSeatbeltBuckled "PM ECU: a006 driver seatbelt buckled";
CM_ SG_ 1444 PM_a006_secGearSelRisingEdgeR "PM ECU: a006 sec gear sel rising edge r";
CM_ SG_ 1444 PM_a006_secGearSelRisingEdgeN "PM ECU: a006 sec gear sel rising edge n";
CM_ SG_ 1444 PM_a006_secGearSelRisingEdgeD "PM ECU: a006 sec gear sel rising edge d";
CM_ SG_ 1444 PM_a007_IBST_party1 "PM ECU: a007 IBST party1";
CM_ SG_ 1444 PM_a007_BUS1_IBST_status "PM ECU: a007 BUS1 IBST status";
CM_ SG_ 1444 PM_a007_BUS2_IBST_status "PM ECU: a007 BUS2 IBST status";
CM_ SG_ 1444 PM_a009_ESP_brakeTorque "PM ECU: a009 ESP brake torque";
CM_ SG_ 1444 PM_a009_ESP_motorLimits "PM ECU: a009 ESP motor limits";
CM_ SG_ 1444 PM_a009_ESP_offsets "PM ECU: a009 ESP offsets";
CM_ SG_ 1444 PM_a009_ESP_party3 "PM ECU: a009 ESP party3";
CM_ SG_ 1444 PM_a009_ESP_status "PM ECU: a009 ESP status";
CM_ SG_ 1444 PM_a009_ESP_wheelSpeeds "PM ECU: a009 ESP wheel speeds";
CM_ SG_ 1444 PM_a010_messageId "PM ECU: a010 message id";
CM_ SG_ 1444 PM_a010_DI_status "PM ECU: a010 DI status";
CM_ SG_ 1444 PM_a010_DI_torque "PM ECU: a010 DI torque";
CM_ SG_ 1444 PM_a010_DI_slaveCommand "PM ECU: a010 DI slave command";
CM_ SG_ 1444 PM_a010_DI_locStatus "PM ECU: a010 DI loc status";
CM_ SG_ 1444 PM_a010_DI_speed "PM ECU: a010 DI speed";
CM_ SG_ 1444 PM_a010_DI_systemStatus "PM ECU: a010 DI system status";
CM_ SG_ 1444 PM_a010_DI_chassisControl "PM ECU: a010 DI chassis control";
CM_ SG_ 1444 PM_a010_DI_chassisControl2 "PM ECU: a010 DI chassis control2";
CM_ SG_ 1444 PM_a010_vdcLeft "PM ECU: a010 vdc left";
CM_ SG_ 1444 PM_a010_vdcRight "PM ECU: a010 vdc right";
CM_ SG_ 1444 PM_a010_DI_vehicleEstimates "PM ECU: a010 DI vehicle estimates";
CM_ SG_ 1444 PM_a010_DI_brakeCommand "PM ECU: a010 DI brake command";
CM_ SG_ 1444 PM_a010_DI_difCommand "PM ECU: a010 DI dif command";
CM_ SG_ 1444 PM_a010_DI_dirCommand "PM ECU: a010 DI dir command";
CM_ SG_ 1444 PM_a010_DI_dirVehicle "PM ECU: a010 DI dir vehicle";
CM_ SG_ 1444 PM_a010_DI_locStatus2 "PM ECU: a010 DI loc status2";
CM_ SG_ 1444 PM_a010_stalklessInterfaces "PM ECU: a010 stalkless interfaces";
CM_ SG_ 1444 PM_a011_pmfHvilStatus "PM ECU: a011 pmf hvil status";
CM_ SG_ 1444 PM_a011_pmfStatusValid "PM ECU: a011 pmf status valid";
CM_ SG_ 1444 PM_a011_pmrHvilStatus "PM ECU: a011 pmr hvil status";
CM_ SG_ 1444 PM_a011_pmrStatusValid "PM ECU: a011 pmr status valid";
CM_ SG_ 1444 PM_a011_vehiclePowerState "PM ECU: a011 vehicle power state";
CM_ SG_ 1444 PM_a011_hvilSystemStatus "PM ECU: a011 hvil system status";
CM_ SG_ 1444 PM_a012_canID "PM ECU: a012 can ID";
CM_ SG_ 1444 PM_a012_errorType "PM ECU: a012 error type";
CM_ SG_ 1444 PM_a012_badValue1 "PM ECU: a012 bad value1";
CM_ SG_ 1444 PM_a012_badValue2 "PM ECU: a012 bad value2";
CM_ SG_ 1444 PM_a013_mailboxID "PM ECU: a013 mailbox ID";
CM_ SG_ 1444 PM_a013_canID "PM ECU: a013 can ID";
CM_ SG_ 1444 PM_a013_errorType "PM ECU: a013 error type";
CM_ SG_ 1444 PM_a014_track1Voltage "PM ECU: a014 track1 voltage";
CM_ SG_ 1444 PM_a014_track2Voltage "PM ECU: a014 track2 voltage";
CM_ SG_ 1444 PM_a014_accelErrorType "PM ECU: a014 accel error type";
CM_ SG_ 1444 PM_a015_SCCM_rightStalk "PM ECU: a015 SCCM right stalk";
CM_ SG_ 1444 PM_a016_BB_status "PM ECU: a016 BB status";
CM_ SG_ 1444 PM_a016_BB_brakeActuation "PM ECU: a016 BB brake actuation";
CM_ SG_ 1444 PM_a017_EPBL_status "PM ECU: a017 EPBL status";
CM_ SG_ 1444 PM_a017_EPBR_status "PM ECU: a017 EPBR status";
CM_ SG_ 1444 PM_a021_torque "PM ECU: a021 torque";
CM_ SG_ 1444 PM_a021_capability "PM ECU: a021 capability";
CM_ SG_ 1444 PM_a021_status "PM ECU: a021 status";
CM_ SG_ 1444 PM_a021_capability2 "PM ECU: a021 capability2";
CM_ SG_ 1444 PM_a021_power "PM ECU: a021 power";
CM_ SG_ 1444 PM_a022_torque "PM ECU: a022 torque";
CM_ SG_ 1444 PM_a022_capability "PM ECU: a022 capability";
CM_ SG_ 1444 PM_a022_status "PM ECU: a022 status";
CM_ SG_ 1444 PM_a022_capability2 "PM ECU: a022 capability2";
CM_ SG_ 1444 PM_a022_power "PM ECU: a022 power";
CM_ SG_ 1444 PM_a023_diCrsState "PM ECU: a023 di crs state";
CM_ SG_ 1444 PM_a023_pmCrsState "PM ECU: a023 pm crs state";
CM_ SG_ 1444 PM_a023_crsFaultReason "PM ECU: a023 crs fault reason";
CM_ SG_ 1444 PM_a023_crsCancelReason "PM ECU: a023 crs cancel reason";
CM_ SG_ 1444 PM_a023_cruiseTorquePed "PM ECU: a023 cruise torque ped";
CM_ SG_ 1444 PM_a023_wheelSpdEstimateAbs "PM ECU: a023 wheel spd estimate abs";
CM_ SG_ 1444 PM_a023_accelEstimateDis "PM ECU: a023 accel estimate dis";
CM_ SG_ 1444 PM_a025_powerOnReset "PM ECU: a025 power on reset";
CM_ SG_ 1444 PM_a025_watchdogTimer0 "PM ECU: a025 watchdog timer0";
CM_ SG_ 1444 PM_a025_watchdogTimer1 "PM ECU: a025 watchdog timer1";
CM_ SG_ 1444 PM_a025_watchdogTimer2 "PM ECU: a025 watchdog timer2";
CM_ SG_ 1444 PM_a025_watchdogTimer3 "PM ECU: a025 watchdog timer3";
CM_ SG_ 1444 PM_a025_warmResetReq "PM ECU: a025 warm reset req";
CM_ SG_ 1444 PM_a025_externalPadReset "PM ECU: a025 external pad reset";
CM_ SG_ 1444 PM_a025_hwSecModuleWatchdogTimer "PM ECU: a025 hw sec module watchdog timer";
CM_ SG_ 1444 PM_a025_debugReset "PM ECU: a025 debug reset";
CM_ SG_ 1444 PM_a025_tempSense0 "PM ECU: a025 temp sense0";
CM_ SG_ 1444 PM_a025_tempSense1 "PM ECU: a025 temp sense1";
CM_ SG_ 1444 PM_a026_reason "PM ECU: a026 reason";
CM_ SG_ 1444 PM_a026_isrCount20kHz "PM ECU: a026 isr count20k hz";
CM_ SG_ 1444 PM_a026_isrCount1kHz "PM ECU: a026 isr count1k hz";
CM_ SG_ 1444 PM_a026_switchingActive "PM ECU: a026 switching active";
CM_ SG_ 1444 PM_a026_systemStackOvf "PM ECU: a026 system stack ovf";
CM_ SG_ 1444 PM_a026_controlStackOvf "PM ECU: a026 control stack ovf";
CM_ SG_ 1444 PM_a026_idleStackOvf "PM ECU: a026 idle stack ovf";
CM_ SG_ 1444 PM_a026_eepStackOvf "PM ECU: a026 eep stack ovf";
CM_ SG_ 1444 PM_a026_immStackOvf "PM ECU: a026 imm stack ovf";
CM_ SG_ 1444 PM_a026_xdcErrorIdMSW "PM ECU: a026 xdc error id MSW";
CM_ SG_ 1444 PM_a026_xdcErrorArg1 "PM ECU: a026 xdc error arg1";
CM_ SG_ 1444 PM_a030_diAebState "PM ECU: a030 di aeb state";
CM_ SG_ 1444 PM_a030_pmAebState "PM ECU: a030 pm aeb state";
CM_ SG_ 1444 PM_a030_dasAebEvent "PM ECU: a030 das aeb event";
CM_ SG_ 1444 PM_a030_aebFaultReason "PM ECU: a030 aeb fault reason";
CM_ SG_ 1444 PM_a030_aebUnavailableReason "PM ECU: a030 aeb unavailable reason";
CM_ SG_ 1444 PM_a030_aebCancelReason "PM ECU: a030 aeb cancel reason";
CM_ SG_ 1444 PM_a030_diBrakeTorqueCommand "PM ECU: a030 di brake torque command";
CM_ SG_ 1444 PM_a032_w0 "PM ECU: a032 w0";
CM_ SG_ 1444 PM_a032_w1 "PM ECU: a032 w1";
CM_ SG_ 1444 PM_a032_w2 "PM ECU: a032 w2";
CM_ SG_ 1444 PM_a036_timeSinceTxHWI "PM ECU: a036 time since tx HWI";
CM_ SG_ 1444 PM_a036_timeSinceRxHWI "PM ECU: a036 time since rx HWI";
CM_ SG_ 1444 PM_a036_timeSince100HzTxSWI "PM ECU: a036 time since100 hz tx SWI";
CM_ SG_ 1444 PM_a036_timeSince1kHzCLK "PM ECU: a036 time since1k hz CLK";
CM_ SG_ 1444 PM_a036_timeSince1kHzSWI "PM ECU: a036 time since1k hz SWI";
CM_ SG_ 1444 PM_a036_timeSinceIdle "PM ECU: a036 time since idle";
CM_ SG_ 1444 PM_a036_ovfStackId "PM ECU: a036 ovf stack id";
CM_ SG_ 1444 PM_a036_inTxISR "PM ECU: a036 in tx ISR";
CM_ SG_ 1444 PM_a036_inTxHWI "PM ECU: a036 in tx HWI";
CM_ SG_ 1444 PM_a036_inRxHWI "PM ECU: a036 in rx HWI";
CM_ SG_ 1444 PM_a036_in1kHzSWI "PM ECU: a036 in1k hz SWI";
CM_ SG_ 1444 PM_a036_in1kHzCLK "PM ECU: a036 in1k hz CLK";
CM_ SG_ 1444 PM_a036_in100HzCLK "PM ECU: a036 in100 hz CLK";
CM_ SG_ 1444 PM_a036_in10HzCLK "PM ECU: a036 in10 hz CLK";
CM_ SG_ 1444 PM_a036_in1HzCLK "PM ECU: a036 in1 hz CLK";
CM_ SG_ 1444 PM_a038_masterTorque "PM ECU: a038 master torque";
CM_ SG_ 1444 PM_a038_slaveTorque "PM ECU: a038 slave torque";
CM_ SG_ 1444 PM_a038_pedalPos "PM ECU: a038 pedal pos";
CM_ SG_ 1444 PM_a039_DIS_status "PM ECU: a039 DIS status";
CM_ SG_ 1444 PM_a039_DIS_torque "PM ECU: a039 DIS torque";
CM_ SG_ 1444 PM_a039_messageId "PM ECU: a039 message id";
CM_ SG_ 1444 PM_a041_DAS_control "PM ECU: a041 DAS control";
CM_ SG_ 1444 PM_a041_DAS_longControl "PM ECU: a041 DAS long control";
CM_ SG_ 1444 PM_a041_DAS_longControlTuningPar "PM ECU: a041 DAS long control tuning parameters";
CM_ SG_ 1444 PM_a041_DAS_status "PM ECU: a041 DAS status";
CM_ SG_ 1444 PM_a041_DAS_status2 "PM ECU: a041 DAS status2";
CM_ SG_ 1444 PM_a041_DAS_smartShift "PM ECU: a041 DAS smart shift";
CM_ SG_ 1444 PM_a042_GTW_carConfig "PM ECU: a042 GTW car config";
CM_ SG_ 1444 PM_a042_GTW_time "PM ECU: a042 GTW time";
CM_ SG_ 1444 PM_a042_GTW_drivetrainType "PM ECU: a042 GTW drivetrain type";
CM_ SG_ 1444 PM_a042_expectedPerformanceCfg "PM ECU: a042 expected performance cfg";
CM_ SG_ 1444 PM_a042_gearControl "PM ECU: a042 gear control";
CM_ SG_ 1444 PM_a043_configInconsistent "PM ECU: a043 config inconsistent";
CM_ SG_ 1444 PM_a043_GTW_autopilot "PM ECU: a043 GTW autopilot";
CM_ SG_ 1444 PM_a043_expectedAutopilot "PM ECU: a043 expected autopilot";
CM_ SG_ 1444 PM_a043_GTW_drivetrainType "PM ECU: a043 GTW drivetrain type";
CM_ SG_ 1444 PM_a043_expectedDrivetrainType "PM ECU: a043 expected drivetrain type";
CM_ SG_ 1444 PM_a043_GTW_chassisType "PM ECU: a043 GTW chassis type";
CM_ SG_ 1444 PM_a043_expectedChassisType "PM ECU: a043 expected chassis type";
CM_ SG_ 1444 PM_a043_packEnergy "PM ECU: a043 pack energy";
CM_ SG_ 1444 PM_a043_packPerformanceDeviation "PM ECU: a043 pack performance deviation";
CM_ SG_ 1444 PM_a043_performancePackage "PM ECU: a043 performance package";
CM_ SG_ 1444 PM_a043_GTW_vdcType "PM ECU: a043 GTW vdc type";
CM_ SG_ 1444 PM_a043_expectedVdcType "PM ECU: a043 expected vdc type";
CM_ SG_ 1444 PM_a043_brakeHWType "PM ECU: a043 brake HW type";
CM_ SG_ 1444 PM_a043_cabinPTCHeaterType "PM ECU: a043 cabin PTC heater type";
CM_ SG_ 1444 PM_a043_softPerformanceLimit "PM ECU: a043 soft performance limit";
CM_ SG_ 1444 PM_a043_GTW_dasHw "PM ECU: a043 GTW das hw";
CM_ SG_ 1444 PM_a044_pmCruiseState "PM ECU: a044 pm cruise state";
CM_ SG_ 1444 PM_a044_diCruiseState "PM ECU: a044 di cruise state";
CM_ SG_ 1444 PM_a044_pmAebState "PM ECU: a044 pm aeb state";
CM_ SG_ 1444 PM_a044_diAebState "PM ECU: a044 di aeb state";
CM_ SG_ 1444 PM_a044_diBrakeTorqueCommand "PM ECU: a044 di brake torque command";
CM_ SG_ 1444 PM_a044_pmBfillTorqueAllowed "PM ECU: a044 pm bfill torque allowed";
CM_ SG_ 1444 PM_a044_pmVehicleHoldState "PM ECU: a044 pm vehicle hold state";
CM_ SG_ 1444 PM_a044_diVehicleHoldState "PM ECU: a044 di vehicle hold state";
CM_ SG_ 1444 PM_a044_regenBackfillPmState "PM ECU: a044 regen backfill pm state";
CM_ SG_ 1444 PM_a045_regenBackfillPmState "PM ECU: a045 regen backfill pm state";
CM_ SG_ 1444 PM_a045_regenBackfillDiState "PM ECU: a045 regen backfill di state";
CM_ SG_ 1444 PM_a045_unavailableReason "PM ECU: a045 unavailable reason";
CM_ SG_ 1444 PM_a045_diBrakeTorqueCommand "PM ECU: a045 di brake torque command";
CM_ SG_ 1444 PM_a045_pmBrakeTorqueAllowed "PM ECU: a045 pm brake torque allowed";
CM_ SG_ 1444 PM_a046_diVhldState "PM ECU: a046 di vhld state";
CM_ SG_ 1444 PM_a046_pmVhldState "PM ECU: a046 pm vhld state";
CM_ SG_ 1444 PM_a046_vhldFaultReason "PM ECU: a046 vhld fault reason";
CM_ SG_ 1444 PM_a046_vhldUnavailableReason "PM ECU: a046 vhld unavailable reason";
CM_ SG_ 1444 PM_a046_diBrakeTorqueCommand "PM ECU: a046 di brake torque command";
CM_ SG_ 1444 PM_a046_diBrakeCommandType "PM ECU: a046 di brake command type";
CM_ SG_ 1444 PM_a047_pmAutoparkState "PM ECU: a047 pm autopark state";
CM_ SG_ 1444 PM_a047_diAutoparkState "PM ECU: a047 di autopark state";
CM_ SG_ 1444 PM_a047_autoparkCancelReason "PM ECU: a047 autopark cancel reason";
CM_ SG_ 1444 PM_a048_vdcFaultReason "PM ECU: a048 vdc fault reason";
CM_ SG_ 1444 PM_a053_LVPowerState "PM ECU: a053 LV power state";
CM_ SG_ 1444 PM_a053_coolant "PM ECU: a053 coolant";
CM_ SG_ 1444 PM_a053_vcleftSwitchStatus "PM ECU: a053 vcleft switch status";
CM_ SG_ 1444 PM_a053_restraintStatus "PM ECU: a053 restraint status";
CM_ SG_ 1444 PM_a053_sensors "PM ECU: a053 sensors";
CM_ SG_ 1444 PM_a054_uiPowertrainControl "PM ECU: a054 ui powertrain control";
CM_ SG_ 1444 PM_a054_uiChassisControl "PM ECU: a054 ui chassis control";
CM_ SG_ 1444 PM_a054_uiCruiseControl "PM ECU: a054 ui cruise control";
CM_ SG_ 1444 PM_a054_uiTrackModeSettings "PM ECU: a054 ui track mode settings";
CM_ SG_ 1444 PM_a054_uiTPMSRCPSetting "PM ECU: a054 ui TPMSRCP setting";
CM_ SG_ 1444 PM_a056_mailboxID "PM ECU: a056 mailbox ID";
CM_ SG_ 1444 PM_a056_canID "PM ECU: a056 can ID";
CM_ SG_ 1444 PM_a056_errorType "PM ECU: a056 error type";
CM_ SG_ 1444 PM_a057_canID "PM ECU: a057 can ID";
CM_ SG_ 1444 PM_a057_errorType "PM ECU: a057 error type";
CM_ SG_ 1444 PM_a057_badValue1 "PM ECU: a057 bad value1";
CM_ SG_ 1444 PM_a057_badValue2 "PM ECU: a057 bad value2";
CM_ SG_ 1444 PM_a058_CMP_HVStatus "PM ECU: a058 CMP HV status";
CM_ SG_ 1444 PM_a058_CMPD_state "PM ECU: a058 CMPD state";
CM_ SG_ 1444 PM_a059_PTC_feedbackStatus "PM ECU: a059 PTC feedback status";
CM_ SG_ 1444 PM_a060_TorqueAccelWindow "PM ECU: a060 torque accel window";
CM_ SG_ 1444 PM_a060_TorqueDecelWindow "PM ECU: a060 torque decel window";
CM_ SG_ 1444 PM_a060_TorqueReversalWindow "PM ECU: a060 torque reversal window";
CM_ SG_ 1444 PM_a061_diIpcVersion "PM ECU: a061 di ipc version";
CM_ SG_ 1444 PM_a061_pmIpcVersion "PM ECU: a061 pm ipc version";
CM_ SG_ 1444 PM_a062_address "PM ECU: a062 address";
CM_ SG_ 1444 PM_a062_errorType "PM ECU: a062 error type";
CM_ SG_ 1444 PM_a063_totalSystemTorqueCommand "PM ECU: a063 total system torque command";
CM_ SG_ 1444 PM_a063_totalSystemTorqueMeasure "PM ECU: a063 total system torque measured";
CM_ SG_ 1444 PM_a064_interventionType "PM ECU: a064 intervention type";
CM_ SG_ 1444 PM_a064_torqueCmdState "PM ECU: a064 torque cmd state";
CM_ SG_ 1444 PM_a064_shortDetectedByDI "PM ECU: a064 short detected by DI";
CM_ SG_ 1444 PM_a064_UI_stoppingMode "PM ECU: a064 UI stopping mode";
CM_ SG_ 1444 PM_a064_diCrsState "PM ECU: a064 di crs state";
CM_ SG_ 1444 PM_a064_pmCrsState "PM ECU: a064 pm crs state";
CM_ SG_ 1444 PM_a066_state4 "PM ECU: a066 state4";
CM_ SG_ 1444 PM_a067_state4 "PM ECU: a067 state4";
CM_ SG_ 1444 PM_a073_canID "PM ECU: a073 can ID";
CM_ SG_ 1444 PM_a073_errorType "PM ECU: a073 error type";
CM_ SG_ 1444 PM_a073_badValue1 "PM ECU: a073 bad value1";
CM_ SG_ 1444 PM_a073_badValue2 "PM ECU: a073 bad value2";
CM_ SG_ 1444 PM_a074_mailboxID "PM ECU: a074 mailbox ID";
CM_ SG_ 1444 PM_a074_canID "PM ECU: a074 can ID";
CM_ SG_ 1444 PM_a074_errorType "PM ECU: a074 error type";
CM_ SG_ 1444 PM_a075_canID "PM ECU: a075 can ID";
CM_ SG_ 1444 PM_a075_errorType "PM ECU: a075 error type";
CM_ SG_ 1444 PM_a075_badValue1 "PM ECU: a075 bad value1";
CM_ SG_ 1444 PM_a075_badValue2 "PM ECU: a075 bad value2";
CM_ SG_ 1444 PM_a076_mailboxID "PM ECU: a076 mailbox ID";
CM_ SG_ 1444 PM_a076_canID "PM ECU: a076 can ID";
CM_ SG_ 1444 PM_a076_errorType "PM ECU: a076 error type";
CM_ SG_ 1444 PM_a077_canID "PM ECU: a077 can ID";
CM_ SG_ 1444 PM_a077_errorType "PM ECU: a077 error type";
CM_ SG_ 1444 PM_a077_badValue1 "PM ECU: a077 bad value1";
CM_ SG_ 1444 PM_a077_badValue2 "PM ECU: a077 bad value2";
CM_ SG_ 1444 PM_a078_mailboxID "PM ECU: a078 mailbox ID";
CM_ SG_ 1444 PM_a078_canID "PM ECU: a078 can ID";
CM_ SG_ 1444 PM_a078_errorType "PM ECU: a078 error type";
CM_ SG_ 1444 PM_a079_VEH_RCU_actuation "PM ECU: a079 VEH RCU actuation";
CM_ SG_ 1444 PM_a079_PARTY_RCU_actuation "PM ECU: a079 PARTY RCU actuation";
CM_ SG_ 1444 PM_a082_faultAddress "PM ECU: a082 fault address";
CM_ SG_ 1444 PM_a082_isWriteNotRead "PM ECU: a082 is write not read";
CM_ SG_ 1444 PM_a084_faultAddress "PM ECU: a084 fault address";
CM_ SG_ 1444 PM_a084_firewallId "PM ECU: a084 firewall id";
CM_ SG_ 1444 PM_a084_privId "PM ECU: a084 priv id";
CM_ SG_ 1444 PM_a084_ns "PM ECU: a084 ns";
CM_ SG_ 1444 PM_a084_faultType "PM ECU: a084 fault type";
CM_ SG_ 1444 PM_a085_DPB_actuator3 "PM ECU: a085 DPB actuator3";
CM_ SG_ 1444 PM_a087_mailboxID "PM ECU: a087 mailbox ID";
CM_ SG_ 1444 PM_a087_canID "PM ECU: a087 can ID";
CM_ SG_ 1444 PM_a087_errorType "PM ECU: a087 error type";
CM_ SG_ 1444 PM_a092_pllClockSource "PM ECU: a092 pll clock source";
CM_ SG_ 1444 PM_a100_index1kHzPeriodic "PM ECU: a100 index1k hz periodic";
CM_ SG_ 1444 PM_a100_index100HzPeriodic "PM ECU: a100 index100 hz periodic";
CM_ SG_ 1444 PM_a100_index10HzPeriodic "PM ECU: a100 index10 hz periodic";
CM_ SG_ 1444 PM_a100_indexSWI "PM ECU: a100 index SWI";
CM_ SG_ 1444 PM_a100_eepEvent "PM ECU: a100 eep event";
CM_ SG_ 1444 PM_a100_module500HzActive "PM ECU: a100 module500 hz active";
CM_ SG_ 1444 PM_a100_module50HzActive "PM ECU: a100 module50 hz active";
CM_ SG_ 1444 PM_a100_module1HzActive "PM ECU: a100 module1 hz active";
CM_ SG_ 1444 PM_a100_task10HzActive "PM ECU: a100 task10 hz active";
CM_ SG_ 1444 PM_a100_taskUdsActive "PM ECU: a100 task uds active";
CM_ BO_ 900 "PM ECU message: alert matrix1";
CM_ SG_ 900 PM_a001_absoluteTorque "PM ECU: a001 absolute torque";
CM_ SG_ 900 PM_a002_excessiveAccelTorque "PM ECU: a002 excessive accel torque";
CM_ SG_ 900 PM_a003_excessiveReversalTorque "PM ECU: a003 excessive reversal torque";
CM_ SG_ 900 PM_a004_excessiveDecelTorque "PM ECU: a004 excessive decel torque";
CM_ SG_ 900 PM_a005_torqueInNeutralOrPark "PM ECU: a005 torque in neutral or park";
CM_ SG_ 900 PM_a006_inconsistentDIGear "PM ECU: a006 inconsistent DI gear";
CM_ SG_ 900 PM_a007_ibstMIA "PM ECU: a007 ibst MIA";
CM_ SG_ 900 PM_a008_memoryError "PM ECU: a008 memory error";
CM_ SG_ 900 PM_a009_espMIA "PM ECU: a009 esp MIA";
CM_ SG_ 900 PM_a010_diMIA "PM ECU: a010 di MIA";
CM_ SG_ 900 PM_a011_systemHvilNotClosed "PM ECU: a011 system hvil not closed";
CM_ SG_ 900 PM_a012_canDataBusA "PM ECU: a012 can data bus a";
CM_ SG_ 900 PM_a013_canHardwareBusA "PM ECU: a013 can hardware bus a";
CM_ SG_ 900 PM_a014_accelPedalError "PM ECU: a014 accel pedal error";
CM_ SG_ 900 PM_a015_shifterMIA "PM ECU: a015 shifter MIA";
CM_ SG_ 900 PM_a016_bbMIA "PM ECU: a016 bb MIA";
CM_ SG_ 900 PM_a017_brakeMIA "PM ECU: a017 brake MIA";
CM_ SG_ 900 PM_a019_vehicleSpeedQFDiagnostic "PM ECU: a019 vehicle speed QF diagnostic";
CM_ SG_ 900 PM_a021_difMIA "PM ECU: a021 dif MIA";
CM_ SG_ 900 PM_a022_dirMIA "PM ECU: a022 dir MIA";
CM_ SG_ 900 PM_a023_cruiseInhibit "PM ECU: a023 cruise inhibit";
CM_ SG_ 900 PM_a024_brakeIrrational "PM ECU: a024 brake irrational";
CM_ SG_ 900 PM_a025_unintendedReset "PM ECU: a025 unintended reset";
CM_ SG_ 900 PM_a026_diHeartBeatMIA "PM ECU: a026 di heart beat MIA";
CM_ SG_ 900 PM_a028_torqueCmdError "PM ECU: a028 torque cmd error";
CM_ SG_ 900 PM_a029_cruiseRollback "PM ECU: a029 cruise rollback";
CM_ SG_ 900 PM_a030_inconsistentAebState "PM ECU: a030 inconsistent aeb state";
CM_ SG_ 900 PM_a031_highStackUsage "PM ECU: a031 high stack usage";
CM_ SG_ 900 PM_a032_registerConfigError "PM ECU: a032 register config error";
CM_ SG_ 900 PM_a033_appMIA "PM ECU: a033 app MIA";
CM_ SG_ 900 PM_a034_trqCrossCheck "PM ECU: a034 trq cross check";
CM_ SG_ 900 PM_a035_udsTransactionInitiated "PM ECU: a035 uds transaction initiated";
CM_ SG_ 900 PM_a036_preWatchdog "PM ECU: a036 pre watchdog";
CM_ SG_ 900 PM_a038_inconsistentTorqueSign "PM ECU: a038 inconsistent torque sign";
CM_ SG_ 900 PM_a039_disMIA "PM ECU: a039 dis MIA";
CM_ SG_ 900 PM_a040_latLinkLooseBoltDetected "PM ECU: a040 lat link loose bolt detected debug";
CM_ SG_ 900 PM_a041_dasMIA "PM ECU: a041 das MIA";
CM_ SG_ 900 PM_a042_gtwMIA "PM ECU: a042 gtw MIA";
CM_ SG_ 900 PM_a043_inconsistentConfig "PM ECU: a043 inconsistent config";
CM_ SG_ 900 PM_a044_ebrIntervention "PM ECU: a044 ebr intervention";
CM_ SG_ 900 PM_a045_regenBackfillInterventio "PM ECU: a045 regen backfill intervention";
CM_ SG_ 900 PM_a046_inconsVehicleHoldState "PM ECU: a046 incons vehicle hold state";
CM_ SG_ 900 PM_a047_inconsAutoparkState "PM ECU: a047 incons autopark state";
CM_ SG_ 900 PM_a048_stabilityControlInhibit "PM ECU: a048 stability control inhibit";
CM_ SG_ 900 PM_a049_stbCtrlInWrongDir "PM ECU: a049 stb ctrl in wrong dir";
CM_ SG_ 900 PM_a050_excessiveStbCtrlTrq "PM ECU: a050 excessive stb ctrl trq";
CM_ SG_ 900 PM_a051_unintDecelStbCtrl "PM ECU: a051 unint decel stb ctrl";
CM_ SG_ 900 PM_a052_stbCtrlDrvrDecelCflct "PM ECU: a052 stb ctrl drvr decel cflct";
CM_ SG_ 900 PM_a053_vcfrontMIA "PM ECU: a053 vcfront MIA";
CM_ SG_ 900 PM_a054_uiMIA "PM ECU: a054 ui MIA";
CM_ SG_ 900 PM_a055_accelPedalSyncWarn "PM ECU: a055 accel pedal sync warn";
CM_ SG_ 900 PM_a056_canHardwareBusB "PM ECU: a056 can hardware bus b";
CM_ SG_ 900 PM_a057_canDataBusB "PM ECU: a057 can data bus b";
CM_ SG_ 900 PM_a058_cmpMIA "PM ECU: a058 cmp MIA";
CM_ SG_ 900 PM_a059_ptcMIA "PM ECU: a059 ptc MIA";
CM_ SG_ 900 PM_a060_onePedalDrivingInhibit "PM ECU: a060 one pedal driving inhibit";
CM_ SG_ 900 PM_a061_DIPMVersionMismatch "PM ECU: a061 DIPM version mismatch";
CM_ SG_ 900 PM_a062_eccError "PM ECU: a062 ecc error";
CM_ SG_ 900 PM_a063_torqueCommandInhibit "PM ECU: a063 torque command inhibit";
CM_ SG_ 900 PM_a064_torqueIntervention "PM ECU: a064 torque intervention";
CM_ BO_ 896 "PM ECU message: alert matrix2";
CM_ SG_ 896 PM_a066_pmfMIA "PM ECU: a066 pmf MIA";
CM_ SG_ 896 PM_a067_pmrMIA "PM ECU: a067 pmr MIA";
CM_ SG_ 896 PM_a068_brakePedalMonitor "PM ECU: a068 brake pedal monitor";
CM_ SG_ 896 PM_a069_brakeMonitorsUnhealthy "PM ECU: a069 brake monitors unhealthy";
CM_ SG_ 896 PM_a070_brakeTorqueSplitMonitorT "PM ECU: a070 brake torque split monitor trip";
CM_ SG_ 896 PM_a071_baseBrakingMonitor "PM ECU: a071 base braking monitor";
CM_ SG_ 896 PM_a072_brakeTorqueCommandInterf "PM ECU: a072 brake torque command interface";
CM_ SG_ 896 PM_a073_canDataBusC "PM ECU: a073 can data bus c";
CM_ SG_ 896 PM_a074_canHardwareBusC "PM ECU: a074 can hardware bus c";
CM_ SG_ 896 PM_a075_canDataBusD "PM ECU: a075 can data bus d";
CM_ SG_ 896 PM_a076_canHardwareBusD "PM ECU: a076 can hardware bus d";
CM_ SG_ 896 PM_a077_canDataBusE "PM ECU: a077 can data bus e";
CM_ SG_ 896 PM_a078_canHardwareBusE "PM ECU: a078 can hardware bus e";
CM_ SG_ 896 PM_a079_rcuMIA "PM ECU: a079 rcu MIA";
CM_ SG_ 896 PM_a080_exceptionPrefetchAbort "PM ECU: a080 exception prefetch abort";
CM_ SG_ 896 PM_a081_exceptionDataAbort "PM ECU: a081 exception data abort";
CM_ SG_ 896 PM_a082_exceptionDataAbort2 "PM ECU: a082 exception data abort2";
CM_ SG_ 896 PM_a083_ahbWriteError "PM ECU: a083 ahb write error";
CM_ SG_ 896 PM_a084_exceptionMpuFirewall "PM ECU: a084 exception mpu firewall";
CM_ SG_ 896 PM_a085_dpbMIA "PM ECU: a085 dpb MIA";
CM_ SG_ 896 PM_a086_exceptionUndefinedInstru "PM ECU: a086 exception undefined instruction";
CM_ SG_ 896 PM_a087_canHardwareBusLIPC "PM ECU: a087 can hardware bus LIPC";
CM_ SG_ 896 PM_a092_xtalOscillator "PM ECU: a092 xtal oscillator";
CM_ SG_ 896 PM_a093_accelPedalSupply "PM ECU: a093 accel pedal supply";
CM_ SG_ 896 PM_a095_ITPMSTimeoutGNSSConverge "PM ECU: a095 ITPMS timeout GNSS convergence";
CM_ SG_ 896 PM_a096_ITPMSConvergedGNSSAbsRad "PM ECU: a096 ITPMS converged GNSS abs radius times";
CM_ SG_ 896 PM_a098_ITPMSTriggerDebug "PM ECU: a098 ITPMS trigger debug";
CM_ SG_ 896 PM_a099_ITPMSCalibrated "PM ECU: a099 ITPMS calibrated";
CM_ SG_ 896 PM_a100_diTraceInfo1 "PM ECU: a100 di trace info1";
CM_ SG_ 896 PM_a110_indirectTPMSSoftWarningF "PM ECU: a110 indirect TPMS soft warning front left";
CM_ SG_ 896 PM_a111_indirectTPMSSoftWarningF "PM ECU: a111 indirect TPMS soft warning front right";
CM_ SG_ 896 PM_a112_indirectTPMSSoftWarningR "PM ECU: a112 indirect TPMS soft warning rear left";
CM_ SG_ 896 PM_a113_indirectTPMSSoftWarningR "PM ECU: a113 indirect TPMS soft warning rear right";
CM_ SG_ 896 PM_a114_indirectTPMSHardWarningF "PM ECU: a114 indirect TPMS hard warning front left";
CM_ SG_ 896 PM_a115_indirectTPMSHardWarningF "PM ECU: a115 indirect TPMS hard warning front right";
CM_ SG_ 896 PM_a116_indirectTPMSHardWarningR "PM ECU: a116 indirect TPMS hard warning rear left";
CM_ SG_ 896 PM_a117_indirectTPMSHardWarningR "PM ECU: a117 indirect TPMS hard warning rear right";
CM_ SG_ 896 PM_a120_indirectTPMSFaulted "PM ECU: a120 indirect TPMS faulted";
CM_ SG_ 896 PM_a121_unintendedReset2 "PM ECU: a121 unintended reset2";
CM_ BO_ 2020 "PM ECU message: info";
CM_ SG_ 2020 PM_infoIndex "PM ECU: info index";
CM_ SG_ 2020 PM_buildType "PM ECU: build type";
CM_ SG_ 2020 PM_buildConfigurationId "PM ECU: build configuration id";
CM_ SG_ 2020 PM_hardwareId "PM ECU: hardware id";
CM_ SG_ 2020 PM_deviceFused "PM ECU: device fused";
CM_ SG_ 2020 PM_componentId "PM ECU: component id";
CM_ SG_ 2020 PM_pcbaId "PM ECU: pcba id";
CM_ SG_ 2020 PM_assemblyId "PM ECU: assembly id";
CM_ SG_ 2020 PM_usageId "PM ECU: usage id";
CM_ SG_ 2020 PM_subUsageId "PM ECU: sub usage id";
CM_ SG_ 2020 PM_applicationCrc "PM ECU: application crc";
CM_ SG_ 2020 PM_bootGitHash "PM ECU: boot git hash";
CM_ BO_ 463 "PM ECU message: system state";
CM_ SG_ 463 PM_torqueCheckState "PM ECU: torque check state";
CM_ SG_ 463 PM_limpRequest "PM ECU: limp request";
CM_ SG_ 463 PM_torqueCommand "PM ECU: torque command";
CM_ SG_ 463 PM_torqueState "PM ECU: torque state";
CM_ SG_ 463 PM_hvilSystemStatus "HVIL system status";
CM_ SG_ 463 PM_sysElecPower "PM ECU: sys elec power";
CM_ SG_ 463 PM_sysNumUnitsMia "PM ECU: sys num units mia";
CM_ SG_ 463 PM_sysNumUnitsSna "PM ECU: sys num units sna";
CM_ SG_ 463 PM_sysElecPowerVeryLow "PM ECU: sys elec power very low";
CM_ SG_ 463 PM_systemStateCounter "PM ECU: system state counter";
CM_ SG_ 463 PM_systemStateChecksum "PM ECU: system state checksum";
CM_ BO_ 2038 "PM ECU message: vdc debug";
CM_ SG_ 2038 PM_vdcDebugSelector "PM ECU: vdc debug selector";
CM_ SG_ 2038 PM_VDCA_TCSlipTargetMod_RA_Fwd "PM ECU: VDCA TC slip target mod RA fwd";
CM_ SG_ 2038 PM_VDCA_TCSlipTargetMod_RA_Rwd "PM ECU: VDCA TC slip target mod RA rwd";
CM_ SG_ 2038 PM_VSE_forceY_RA "PM ECU: VSE force y RA";
CM_ SG_ 2038 PM_VDCT_observerSlipAngle_RA "PM ECU: VDCT observer slip angle RA";
CM_ SG_ 2038 PM_VSE_muVehicleFxLow "PM ECU: VSE mu vehicle fx low";
CM_ SG_ 2038 PM_VE_fxmFres "PM ECU: VE fxm fres";
CM_ SG_ 2038 PM_VE_fxAccelMass "PM ECU: VE fx accel mass";
CM_ SG_ 2038 PM_VE_vxDotGrade "PM ECU: VE vx dot grade";
CM_ SG_ 2038 PM_VE_betaEst "PM ECU: VE beta est";
CM_ SG_ 2038 PM_VSE_muVehicleFxHigh "PM ECU: VSE mu vehicle fx high";
CM_ SG_ 2038 PM_VSE_muVehicleDecLeakRate "PM ECU: VSE mu vehicle dec leak rate";
CM_ SG_ 2038 PM_VSE_muVehicleLearnDown "PM ECU: VSE mu vehicle learn down";
CM_ SG_ 2038 PM_VSE_muVehicleDecFilter "PM ECU: VSE mu vehicle dec filter";
CM_ SG_ 2038 PM_VSE_muVehicleLatDecLeakRate "PM ECU: VSE mu vehicle lat dec leak rate";
CM_ SG_ 2038 PM_VSE_splitMuProbability "PM ECU: VSE split mu probability";
CM_ SG_ 2038 PM_VSE_splitMuTotalMz "PM ECU: VSE split mu total mz";
CM_ SG_ 2038 PM_VSE_attitudeBankAngle "PM ECU: VSE attitude bank angle";
CM_ SG_ 2038 PM_VSE_attitudeDBetaInControl "PM ECU: VSE attitude d beta in control";
CM_ SG_ 2038 PM_VSE_roadWheelAngleAverage "PM ECU: VSE road wheel angle average";
CM_ BO_ 1766 "PNCD ECU message: iso tp pipe to cp";
CM_ SG_ 1766 PNCD_isoTpToCpData "PNCD ECU: iso tp to cp data";
CM_ BO_ 519 "Cabin heater message: feedback status";
CM_ SG_ 519 PTC_leftFlagFault "Heater left bank fault indication flag";
CM_ SG_ 519 PTC_rightFlagFault "Heater right bank fault indication flag";
CM_ SG_ 519 PTC_leftPowerDerating "Heater left bank power derating state";
CM_ SG_ 519 PTC_rightPowerDerating "Heater right bank power derating state";
CM_ SG_ 519 PTC_ocpEvent "Indication that an over current protection event has occurred";
CM_ SG_ 519 PTC_leftDutyFeedback "Current PWM duty cycle applied to left side of PTC heater";
CM_ SG_ 519 PTC_rightDutyFeedback "Current PWM duty cycle applied to right side of PTC heater";
CM_ SG_ 519 PTC_leftPowerHV "Heater left bank power";
CM_ SG_ 519 PTC_rightPowerHV "Heater right bank power";
CM_ SG_ 519 PTC_leftTempEstOutlet "Cabin heater: left temp est outlet";
CM_ SG_ 519 PTC_rightTempEstOutlet "Cabin heater: right temp est outlet";
CM_ SG_ 519 PTC_tliErrorCount "Heater top level interrupt error count";
CM_ SG_ 519 PTC_tliEvent "Indicator of heater top level interrupt event";
CM_ SG_ 519 PTC_tliSource "Heater top level interrupt event source";
CM_ BO_ 837 "Cabin heater message: info";
CM_ SG_ 837 PTC_infoIndex "Cabin heater: info index";
CM_ SG_ 837 PTC_infoBuildType "Cabin heater: info build type";
CM_ SG_ 837 PTC_infoBuildConfigId "Cabin heater: info build config id";
CM_ SG_ 837 PTC_infoHardwareId "Cabin heater: info hardware id";
CM_ SG_ 837 PTC_infoComponentId "Cabin heater: info component id";
CM_ SG_ 837 PTC_infoPcbaId "Cabin heater: info pcba id";
CM_ SG_ 837 PTC_infoAssemblyId "Cabin heater: info assembly id";
CM_ SG_ 837 PTC_infoUsageId "Cabin heater: info usage id";
CM_ SG_ 837 PTC_infoSubUsageId "Cabin heater: info sub usage id";
CM_ SG_ 837 PTC_infoPlatformType "Cabin heater: info platform type";
CM_ SG_ 837 PTC_infoAppCrc "Cabin heater: info app crc";
CM_ SG_ 837 PTC_infoBootUdsProtoVersion "Cabin heater: info boot uds proto version";
CM_ SG_ 837 PTC_infoBootCrc "Cabin heater: info boot crc";
CM_ BO_ 2019 "Cabin heater message: sensor status";
CM_ SG_ 2019 PTC_leftTempIGBT "Heater left bank IGBT temperature";
CM_ SG_ 2019 PTC_tempOCP "Temperature measured near the over current protection circuit";
CM_ SG_ 2019 PTC_rightTempIGBT "Heater right bank IGBT temperature";
CM_ SG_ 2019 PTC_tempPCB "Heater printed circuit board temperature";
CM_ SG_ 2019 PTC_voltageHV "Heater high voltage input voltage";
CM_ SG_ 2019 PTC_leftCurrentHV "Cabin heater: left current HV";
CM_ SG_ 2019 PTC_rightCurrentHV "Cabin heater: right current HV";
BA_DEF_ BO_ "GenMsgCycleTime" INT 0 3600000;
BA_DEF_ BO_ "GenMsgSendType" ENUM "Cyclic","NotUsed","NotUsed","NotUsed","NotUsed","NotUsed","NotUsed","IfActive","NoMsgSendType","NotUsed";
BA_DEF_ BO_ "VFrameFormat" ENUM "StandardCAN","ExtendedCAN","reserved","J1939PG","reserved","reserved","reserved","reserved","reserved","reserved","reserved","reserved","reserved","reserved","StandardCAN_FD","ExtendedCAN_FD";
BA_DEF_ BO_ "CANFD_BRS" ENUM "0","1";
BA_DEF_ SG_ "SystemSignalLongSymbol" STRING;
BA_DEF_ SG_ "Confidence" ENUM "layout-only","plausible","validated";
BA_DEF_DEF_ "GenMsgCycleTime" 0;
BA_DEF_DEF_ "GenMsgSendType" "NoMsgSendType";
BA_DEF_DEF_ "VFrameFormat" "StandardCAN";
BA_DEF_DEF_ "CANFD_BRS" "1";
BA_DEF_DEF_ "SystemSignalLongSymbol" "";
BA_DEF_DEF_ "Confidence" "layout-only";
BA_ "Confidence" SG_ 548 PCS_dcdcPrechargeStatus 1;
BA_ "Confidence" SG_ 548 PCS_dcdcLvSupportStatus 1;
BA_ "Confidence" SG_ 548 PCS_dcdcHvBusDischargeStatus 1;
BA_ "Confidence" SG_ 548 PCS_dcdcSubState 1;
BA_ "Confidence" SG_ 548 PCS_dcdcFaulted 1;
BA_ "Confidence" SG_ 548 PCS_dcdcOutputIsLimited 1;
BA_ "Confidence" SG_ 548 PCS_dcdcMaxOutputCurrentAllowed 1;
BA_ "Confidence" SG_ 548 PCS_dcdcPwmEnableLine 1;
BA_ "Confidence" SG_ 548 PCS_dcdcSupportingFixedLvTarget 1;
BA_ "Confidence" SG_ 548 PCS_ecuLogUploadRequest 1;
BA_ "Confidence" SG_ 548 PCS_dcdcInitialPrechargeSubState 1;
BA_ "Confidence" SG_ 964 PCS_buildType 1;
BA_ "Confidence" SG_ 964 PCS_pcbaId 1;
BA_ "Confidence" SG_ 964 PCS_usageId 1;
BA_ "Confidence" SG_ 964 PCS_subUsageId 1;
BA_ "Confidence" SG_ 708 PCS_chgPhAInputIrms 1;
BA_ "Confidence" SG_ 708 PCS_chgPhAIntBusV 1;
BA_ "Confidence" SG_ 708 PCS_chgPhAIntBusVTarget 1;
BA_ "Confidence" SG_ 708 PCS_chgPhAOutputI 1;
BA_ "Confidence" SG_ 708 PCS_chgPhAInputCurrentLimitReaso 1;
BA_ "SystemSignalLongSymbol" SG_ 708 PCS_chgPhAInputCurrentLimitReaso "PCS_chgPhAInputCurrentLimitReason";
BA_ "Confidence" SG_ 708 PCS_chgPhBInputIrms 1;
BA_ "Confidence" SG_ 708 PCS_chgPhBIntBusV 1;
BA_ "Confidence" SG_ 708 PCS_chgPhBIntBusVTarget 1;
BA_ "Confidence" SG_ 708 PCS_chgPhBOutputI 1;
BA_ "Confidence" SG_ 708 PCS_chgPhBInputCurrentLimitReaso 1;
BA_ "SystemSignalLongSymbol" SG_ 708 PCS_chgPhBInputCurrentLimitReaso "PCS_chgPhBInputCurrentLimitReason";
BA_ "Confidence" SG_ 708 PCS_chgPhCInputIrms 1;
BA_ "Confidence" SG_ 708 PCS_chgPhCIntBusV 1;
BA_ "Confidence" SG_ 708 PCS_chgPhCIntBusVTarget 1;
BA_ "Confidence" SG_ 708 PCS_chgPhCOutputI 1;
BA_ "Confidence" SG_ 708 PCS_chgPhCInputCurrentLimitReaso 1;
BA_ "SystemSignalLongSymbol" SG_ 708 PCS_chgPhCInputCurrentLimitReaso "PCS_chgPhCInputCurrentLimitReason";
BA_ "Confidence" SG_ 708 PCS_chgInputL1NVrms 1;
BA_ "Confidence" SG_ 708 PCS_chgInputL2NVrms 1;
BA_ "Confidence" SG_ 708 PCS_chgInputL3NVrms 1;
BA_ "Confidence" SG_ 708 PCS_chgInputL1L2Vrms 1;
BA_ "Confidence" SG_ 708 PCS_chgInputNGVrms 1;
BA_ "Confidence" SG_ 708 PCS_chgInputFrequencyL1N 1;
BA_ "Confidence" SG_ 708 PCS_chgInputFrequencyL2N 1;
BA_ "Confidence" SG_ 708 PCS_chgInputFrequencyL3N 1;
BA_ "Confidence" SG_ 708 PCS_chgInternalPhaseConfig 1;
BA_ "Confidence" SG_ 708 PCS_chgPhasesPriority 1;
BA_ "Confidence" SG_ 708 PCS_chgOutputV 1;
BA_ "Confidence" SG_ 708 PCS_chgPhAState 1;
BA_ "Confidence" SG_ 708 PCS_chgPhBState 1;
BA_ "Confidence" SG_ 708 PCS_chgPhCState 1;
BA_ "Confidence" SG_ 708 PCS_chgPhALastShutdownReason 1;
BA_ "Confidence" SG_ 708 PCS_chgPhBLastShutdownReason 1;
BA_ "Confidence" SG_ 708 PCS_chgPhCLastShutdownReason 1;
BA_ "Confidence" SG_ 708 PCS_chgPhARetryCount 1;
BA_ "Confidence" SG_ 708 PCS_chgPhBRetryCount 1;
BA_ "Confidence" SG_ 708 PCS_chgPhCRetryCount 1;
BA_ "Confidence" SG_ 708 PCS_chgRetryCount 1;
BA_ "Confidence" SG_ 708 PCS_chgPhManCurrentToDist 1;
BA_ "Confidence" SG_ 708 PCS_dcdcMaxLvOutputCurrent 1;
BA_ "Confidence" SG_ 708 PCS_dcdcCurrentLimit 1;
BA_ "Confidence" SG_ 708 PCS_dcdcLvOutputCurrentTempLimit 1;
BA_ "Confidence" SG_ 708 PCS_dcdcLvOutputCurrentFiltered 1;
BA_ "Confidence" SG_ 708 PCS_dcdcUnifiedCommand 1;
BA_ "Confidence" SG_ 708 PCS_dcdcCLAControllerOutput 1;
BA_ "Confidence" SG_ 708 PCS_dcdcTankVoltage 1;
BA_ "Confidence" SG_ 708 PCS_dcdcTankVoltageTarget 1;
BA_ "Confidence" SG_ 708 PCS_dcdcClaCurrentFreq 1;
BA_ "Confidence" SG_ 708 PCS_dcdcTCommMeasured 1;
BA_ "Confidence" SG_ 708 PCS_dcdcShortTimeUs 1;
BA_ "Confidence" SG_ 708 PCS_dcdcHalfPeriodUs 1;
BA_ "Confidence" SG_ 708 PCS_dcdcLvBusVoltTargetWithOffse 1;
BA_ "SystemSignalLongSymbol" SG_ 708 PCS_dcdcLvBusVoltTargetWithOffse "PCS_dcdcLvBusVoltTargetWithOffset";
BA_ "Confidence" SG_ 708 PCS_cpu2BootState 1;
BA_ "Confidence" SG_ 708 PCS_acChargeSelfTestState 1;
BA_ "Confidence" SG_ 708 PCS_1V5Min10s 1;
BA_ "Confidence" SG_ 708 PCS_1V5Max10s 1;
BA_ "Confidence" SG_ 708 PCS_1V2Min10s 1;
BA_ "Confidence" SG_ 708 PCS_1V2Max10s 1;
BA_ "Confidence" SG_ 708 PCS_5VNMax10s 1;
BA_ "Confidence" SG_ 708 PCS_chgPhAIntBusVMin10s 1;
BA_ "Confidence" SG_ 708 PCS_chgPhAIntBusVMax10s 1;
BA_ "Confidence" SG_ 708 PCS_chgPhAPchgVoltDeltaMax10s 1;
BA_ "Confidence" SG_ 708 PCS_chgPhALifetimekWh 1;
BA_ "Confidence" SG_ 708 PCS_chgPhATransientRetryCount 1;
BA_ "Confidence" SG_ 708 PCS_chgPhBIntBusVMin10s 1;
BA_ "Confidence" SG_ 708 PCS_chgPhBIntBusVMax10s 1;
BA_ "Confidence" SG_ 708 PCS_chgPhBPchgVoltDeltaMax10s 1;
BA_ "Confidence" SG_ 708 PCS_chgPhBLifetimekWh 1;
BA_ "Confidence" SG_ 708 PCS_chgPhBTransientRetryCount 1;
BA_ "Confidence" SG_ 708 PCS_chgPhCIntBusVMin10s 1;
BA_ "Confidence" SG_ 708 PCS_chgPhCIntBusVMax10s 1;
BA_ "Confidence" SG_ 708 PCS_chgPhCPchgVoltDeltaMax10s 1;
BA_ "Confidence" SG_ 708 PCS_chgPhCLifetimekWh 1;
BA_ "Confidence" SG_ 708 PCS_chgPhCTransientRetryCount 1;
BA_ "Confidence" SG_ 708 PCS_chgPhANoFlowBucket 1;
BA_ "Confidence" SG_ 708 PCS_chgPhBNoFlowBucket 1;
BA_ "Confidence" SG_ 708 PCS_chgPhCNoFlowBucket 1;
BA_ "Confidence" SG_ 708 PCS_chgCurrentSensorOutOfBandUs 1;
BA_ "Confidence" SG_ 708 PCS_chgAcpwHeartbeatState 1;
BA_ "Confidence" SG_ 708 PCS_chgKwhLostByFreqDroop 1;
BA_ "Confidence" SG_ 708 PCS_chgReqKwhLostByFreqDroop 1;
BA_ "Confidence" SG_ 708 PCS_dcdcLvSupportLifetimekWh 1;
BA_ "Confidence" SG_ 708 PCS_dcdcPwmEnableLineErrorCount 1;
BA_ "Confidence" SG_ 708 PCS_dcdcPchgStartLvBusVolt 1;
BA_ "Confidence" SG_ 708 PCS_dcdcPchgStartHvBusVolt 1;
BA_ "Confidence" SG_ 676 PCS_chgPhATemp 1;
BA_ "Confidence" SG_ 676 PCS_chgPhBTemp 1;
BA_ "Confidence" SG_ 676 PCS_chgPhCTemp 1;
BA_ "Confidence" SG_ 676 PCS_dcdcTemp 1;
BA_ "Confidence" SG_ 676 PCS_ambientTemp 1;
BA_ "Confidence" SG_ 676 PCS_dcdcBusbarTemp 1;
BA_ "SystemSignalLongSymbol" SG_ 1317 PMF_a025_hwSecModuleWatchdogTime "PMF_a025_hwSecModuleWatchdogTimer";
BA_ "SystemSignalLongSymbol" SG_ 772 PMF_a027_torqueEstimationOutOfBo "PMF_a027_torqueEstimationOutOfBounds";
BA_ "SystemSignalLongSymbol" SG_ 772 PMF_a058_measuredHvilCurrentFroz "PMF_a058_measuredHvilCurrentFrozen";
BA_ "SystemSignalLongSymbol" SG_ 2022 PMF_a086_exceptionUndefinedInstr "PMF_a086_exceptionUndefinedInstruction";
BA_ "Confidence" SG_ 790 PMF_buildType 1;
BA_ "SystemSignalLongSymbol" SG_ 1446 PMR_a025_hwSecModuleWatchdogTime "PMR_a025_hwSecModuleWatchdogTimer";
BA_ "SystemSignalLongSymbol" SG_ 902 PMR_a027_torqueEstimationOutOfBo "PMR_a027_torqueEstimationOutOfBounds";
BA_ "SystemSignalLongSymbol" SG_ 902 PMR_a058_measuredHvilCurrentFroz "PMR_a058_measuredHvilCurrentFrozen";
BA_ "SystemSignalLongSymbol" SG_ 928 PMR_a086_exceptionUndefinedInstr "PMR_a086_exceptionUndefinedInstruction";
BA_ "Confidence" SG_ 1748 PMR_buildType 1;
BA_ "SystemSignalLongSymbol" SG_ 1444 PM_a006_requireAccelPedalCheckSp "PM_a006_requireAccelPedalCheckSpeed";
BA_ "SystemSignalLongSymbol" SG_ 1444 PM_a041_DAS_longControlTuningPar "PM_a041_DAS_longControlTuningParameters";
BA_ "SystemSignalLongSymbol" SG_ 1444 PM_a063_totalSystemTorqueMeasure "PM_a063_totalSystemTorqueMeasured";
BA_ "SystemSignalLongSymbol" SG_ 900 PM_a040_latLinkLooseBoltDetected "PM_a040_latLinkLooseBoltDetectedDebug";
BA_ "SystemSignalLongSymbol" SG_ 900 PM_a045_regenBackfillInterventio "PM_a045_regenBackfillIntervention";
BA_ "SystemSignalLongSymbol" SG_ 896 PM_a070_brakeTorqueSplitMonitorT "PM_a070_brakeTorqueSplitMonitorTrip";
BA_ "SystemSignalLongSymbol" SG_ 896 PM_a072_brakeTorqueCommandInterf "PM_a072_brakeTorqueCommandInterface";
BA_ "SystemSignalLongSymbol" SG_ 896 PM_a086_exceptionUndefinedInstru "PM_a086_exceptionUndefinedInstruction";
BA_ "SystemSignalLongSymbol" SG_ 896 PM_a095_ITPMSTimeoutGNSSConverge "PM_a095_ITPMSTimeoutGNSSConvergence";
BA_ "SystemSignalLongSymbol" SG_ 896 PM_a096_ITPMSConvergedGNSSAbsRad "PM_a096_ITPMSConvergedGNSSAbsRadiusTimes";
BA_ "SystemSignalLongSymbol" SG_ 896 PM_a110_indirectTPMSSoftWarningF "PM_a110_indirectTPMSSoftWarningFrontLeft";
BA_ "SystemSignalLongSymbol" SG_ 896 PM_a111_indirectTPMSSoftWarningF "PM_a111_indirectTPMSSoftWarningFrontRight";
BA_ "SystemSignalLongSymbol" SG_ 896 PM_a112_indirectTPMSSoftWarningR "PM_a112_indirectTPMSSoftWarningRearLeft";
BA_ "SystemSignalLongSymbol" SG_ 896 PM_a113_indirectTPMSSoftWarningR "PM_a113_indirectTPMSSoftWarningRearRight";
BA_ "SystemSignalLongSymbol" SG_ 896 PM_a114_indirectTPMSHardWarningF "PM_a114_indirectTPMSHardWarningFrontLeft";
BA_ "SystemSignalLongSymbol" SG_ 896 PM_a115_indirectTPMSHardWarningF "PM_a115_indirectTPMSHardWarningFrontRight";
BA_ "SystemSignalLongSymbol" SG_ 896 PM_a116_indirectTPMSHardWarningR "PM_a116_indirectTPMSHardWarningRearLeft";
BA_ "SystemSignalLongSymbol" SG_ 896 PM_a117_indirectTPMSHardWarningR "PM_a117_indirectTPMSHardWarningRearRight";
BA_ "Confidence" SG_ 2020 PM_buildType 1;
BA_ "Confidence" SG_ 463 PM_hvilSystemStatus 1;
BA_ "Confidence" SG_ 2038 PM_VDCA_TCSlipTargetMod_RA_Fwd 1;
BA_ "Confidence" SG_ 2038 PM_VDCA_TCSlipTargetMod_RA_Rwd 1;
BA_ "Confidence" SG_ 2038 PM_VSE_forceY_RA 1;
BA_ "Confidence" SG_ 2038 PM_VDCT_observerSlipAngle_RA 1;
BA_ "Confidence" SG_ 2038 PM_VSE_muVehicleFxLow 1;
BA_ "Confidence" SG_ 2038 PM_VE_fxmFres 1;
BA_ "Confidence" SG_ 2038 PM_VE_fxAccelMass 1;
BA_ "Confidence" SG_ 2038 PM_VE_vxDotGrade 1;
BA_ "Confidence" SG_ 2038 PM_VE_betaEst 1;
BA_ "Confidence" SG_ 2038 PM_VSE_muVehicleFxHigh 1;
BA_ "Confidence" SG_ 2038 PM_VSE_muVehicleDecLeakRate 1;
BA_ "Confidence" SG_ 2038 PM_VSE_muVehicleLearnDown 1;
BA_ "Confidence" SG_ 2038 PM_VSE_muVehicleDecFilter 1;
BA_ "Confidence" SG_ 2038 PM_VSE_muVehicleLatDecLeakRate 1;
BA_ "Confidence" SG_ 2038 PM_VSE_splitMuProbability 1;
BA_ "Confidence" SG_ 2038 PM_VSE_splitMuTotalMz 1;
BA_ "Confidence" SG_ 2038 PM_VSE_attitudeBankAngle 1;
BA_ "Confidence" SG_ 2038 PM_VSE_attitudeDBetaInControl 1;
BA_ "Confidence" SG_ 2038 PM_VSE_roadWheelAngleAverage 1;
BA_ "Confidence" SG_ 519 PTC_leftFlagFault 1;
BA_ "Confidence" SG_ 519 PTC_rightFlagFault 1;
BA_ "Confidence" SG_ 519 PTC_leftPowerDerating 1;
BA_ "Confidence" SG_ 519 PTC_rightPowerDerating 1;
BA_ "Confidence" SG_ 519 PTC_ocpEvent 1;
BA_ "Confidence" SG_ 519 PTC_leftDutyFeedback 1;
BA_ "Confidence" SG_ 519 PTC_rightDutyFeedback 1;
BA_ "Confidence" SG_ 519 PTC_leftPowerHV 1;
BA_ "Confidence" SG_ 519 PTC_rightPowerHV 1;
BA_ "Confidence" SG_ 519 PTC_leftTempEstOutlet 1;
BA_ "Confidence" SG_ 519 PTC_rightTempEstOutlet 1;
BA_ "Confidence" SG_ 519 PTC_tliErrorCount 1;
BA_ "Confidence" SG_ 519 PTC_tliEvent 1;
BA_ "Confidence" SG_ 519 PTC_tliSource 1;
BA_ "Confidence" SG_ 837 PTC_infoBuildType 1;
BA_ "Confidence" SG_ 2019 PTC_leftTempIGBT 1;
BA_ "Confidence" SG_ 2019 PTC_tempOCP 1;
BA_ "Confidence" SG_ 2019 PTC_rightTempIGBT 1;
BA_ "Confidence" SG_ 2019 PTC_tempPCB 1;
BA_ "Confidence" SG_ 2019 PTC_voltageHV 1;
BA_ "Confidence" SG_ 2019 PTC_leftCurrentHV 1;
BA_ "Confidence" SG_ 2019 PTC_rightCurrentHV 1;
VAL_ 548 PCS_dcdcPrechargeStatus 3 "PCS_DCDC_PRECHARGE_IMPEDANCE_CHECK" 2 "PCS_DCDC_PRECHARGE_FAULTED" 1 "PCS_DCDC_PRECHARGE_ACTIVE" 0 "PCS_DCDC_PRECHARGE_IDLE" ;
VAL_ 548 PCS_dcdcLvSupportStatus 2 "PCS_DCDC_LV_SUPPORT_FAULTED" 1 "PCS_DCDC_LV_SUPPORT_ACTIVE" 0 "PCS_DCDC_LV_SUPPORT_IDLE" ;
VAL_ 548 PCS_dcdcHvBusDischargeStatus 2 "PCS_DCDC_DIS_HVBUS_FAULTED" 1 "PCS_DCDC_DIS_HVBUS_ACTIVE" 0 "PCS_DCDC_DIS_HVBUS_IDLE" ;
VAL_ 548 PCS_dcdcSubState 18 "DCDC_SUBSTATE_NUM" 17 "DCDC_SUBSTATE_FAULTED" 16 "DCDC_SUBSTATE_CLEAR_FAULTS" 15 "DCDC_SUBSTATE_PCHG_FAULTED" 14 "DCDC_SUBSTATE_DIS_HVBUS_FAULTED" 13 "DCDC_SUBSTATE_LV_SUPPORT_FAULTED" 12 "DCDC_SUBSTATE_SHUTDOWN" 11 "DCDC_SUBSTATE_PCHG_FLT_FAST_DIS_HVBUS" 10 "DCDC_SUBSTATE_PCHG_ACTIVE" 9 "DCDC_SUBSTATE_PCHG_DI_RECOVERY_WAIT" 8 "DCDC_SUBSTATE_PCHG_DWELL_WAIT" 7 "DCDC_SUBSTATE_PCHG_DWELL_CHARGE" 6 "DCDC_SUBSTATE_PCHG_SLOW_DIS_HVBUS" 5 "DCDC_SUBSTATE_PCHG_FAST_DIS_HVBUS" 4 "DCDC_SUBSTATE_SLOW_DIS_HVBUS" 3 "DCDC_SUBSTATE_FAST_DIS_HVBUS" 2 "DCDC_SUBSTATE_LV_SUPPORT_ACTIVE" 1 "DCDC_SUBSTATE_STANDBY" 0 "DCDC_SUBSTATE_PWR_UP_INIT" ;
VAL_ 548 PCS_ecuLogUploadRequest 3 "REQUEST_PRIORITY_3" 2 "REQUEST_PRIORITY_2" 1 "REQUEST_PRIORITY_1" 0 "REQUEST_PRIORITY_NONE" ;
VAL_ 548 PCS_dcdcInitialPrechargeSubState 18 "DCDC_SUBSTATE_NUM" 17 "DCDC_SUBSTATE_FAULTED" 16 "DCDC_SUBSTATE_CLEAR_FAULTS" 15 "DCDC_SUBSTATE_PCHG_FAULTED" 14 "DCDC_SUBSTATE_DIS_HVBUS_FAULTED" 13 "DCDC_SUBSTATE_LV_SUPPORT_FAULTED" 12 "DCDC_SUBSTATE_SHUTDOWN" 11 "DCDC_SUBSTATE_PCHG_FLT_FAST_DIS_HVBUS" 10 "DCDC_SUBSTATE_PCHG_ACTIVE" 9 "DCDC_SUBSTATE_PCHG_DI_RECOVERY_WAIT" 8 "DCDC_SUBSTATE_PCHG_DWELL_WAIT" 7 "DCDC_SUBSTATE_PCHG_DWELL_CHARGE" 6 "DCDC_SUBSTATE_PCHG_SLOW_DIS_HVBUS" 5 "DCDC_SUBSTATE_PCHG_FAST_DIS_HVBUS" 4 "DCDC_SUBSTATE_SLOW_DIS_HVBUS" 3 "DCDC_SUBSTATE_FAST_DIS_HVBUS" 2 "DCDC_SUBSTATE_LV_SUPPORT_ACTIVE" 1 "DCDC_SUBSTATE_STANDBY" 0 "DCDC_SUBSTATE_PWR_UP_INIT" ;
VAL_ 964 PCS_buildType 4 "INFO_MFG_BUILD" 3 "INFO_TRACEABLE_CI_BUILD" 2 "INFO_LOCAL_BUILD" 1 "INFO_PLATFORM_BUILD" 0 "INFO_UNKNOWN_BUILD" ;
VAL_ 708 PCS_chgPhAInputCurrentLimitReaso 5 "PCS_IAC_LIMITED_BY_PHASE_MACHINE_MODEL" 4 "PCS_IAC_LIMITED_BY_PHASE_THERMAL_LIMIT" 3 "PCS_IAC_LIMITED_BY_INPUT_POWER" 2 "PCS_IAC_LIMITED_BY_OUTPUT_POWER" 1 "PCS_IAC_LIMITED_BY_RIPPLE_RELAXED" 0 "PCS_IAC_LIMITED_BY_NONE" ;
VAL_ 708 PCS_chgPhBInputCurrentLimitReaso 5 "PCS_IAC_LIMITED_BY_PHASE_MACHINE_MODEL" 4 "PCS_IAC_LIMITED_BY_PHASE_THERMAL_LIMIT" 3 "PCS_IAC_LIMITED_BY_INPUT_POWER" 2 "PCS_IAC_LIMITED_BY_OUTPUT_POWER" 1 "PCS_IAC_LIMITED_BY_RIPPLE_RELAXED" 0 "PCS_IAC_LIMITED_BY_NONE" ;
VAL_ 708 PCS_chgPhCInputCurrentLimitReaso 5 "PCS_IAC_LIMITED_BY_PHASE_MACHINE_MODEL" 4 "PCS_IAC_LIMITED_BY_PHASE_THERMAL_LIMIT" 3 "PCS_IAC_LIMITED_BY_INPUT_POWER" 2 "PCS_IAC_LIMITED_BY_OUTPUT_POWER" 1 "PCS_IAC_LIMITED_BY_RIPPLE_RELAXED" 0 "PCS_IAC_LIMITED_BY_NONE" ;
VAL_ 708 PCS_chgInternalPhaseConfig 9 "PHASE_CONFIG_TOTAL_NUM" 8 "PHASE_CONFIG_SINGLE_PHASE_EVSE_PARALLEL" 7 "PHASE_CONFIG_SINGLE_PHASE_BRIDGED_HARNESS" 6 "PHASE_CONFIG_MFG_TEST_CONFIG_2" 5 "PHASE_CONFIG_MFG_TEST_CONFIG_1" 4 "PHASE_CONFIG_SINGLE_PHASE_IEC_GB" 3 "PHASE_CONFIG_THREE_PHASE_DELTA" 2 "PHASE_CONFIG_THREE_PHASE" 1 "PHASE_CONFIG_SINGLE_PHASE" 0 "PHASE_CONFIG_SNA" ;
VAL_ 708 PCS_chgPhasesPriority 36 "PHASES_PRIORITY_ABC" 33 "PHASES_PRIORITY_BAC" 24 "PHASES_PRIORITY_ACB" 18 "PHASES_PRIORITY_CAB" 9 "PHASES_PRIORITY_BCA" 6 "PHASES_PRIORITY_CBA" 0 "UNDEFINED_PHASES_PRIORITY" ;
VAL_ 708 PCS_chgPhAState 6 "PCS_PH_STATE_SHUTTING_DOWN" 5 "PCS_PH_STATE_CLEAR_FAULTS" 4 "PCS_PH_STATE_FAULT" 3 "PCS_PH_STATE_ENABLE" 2 "PCS_PH_STATE_PRECHARGE" 1 "PCS_PH_STATE_IDLE" 0 "PCS_PH_STATE_INIT" ;
VAL_ 708 PCS_chgPhBState 6 "PCS_PH_STATE_SHUTTING_DOWN" 5 "PCS_PH_STATE_CLEAR_FAULTS" 4 "PCS_PH_STATE_FAULT" 3 "PCS_PH_STATE_ENABLE" 2 "PCS_PH_STATE_PRECHARGE" 1 "PCS_PH_STATE_IDLE" 0 "PCS_PH_STATE_INIT" ;
VAL_ 708 PCS_chgPhCState 6 "PCS_PH_STATE_SHUTTING_DOWN" 5 "PCS_PH_STATE_CLEAR_FAULTS" 4 "PCS_PH_STATE_FAULT" 3 "PCS_PH_STATE_ENABLE" 2 "PCS_PH_STATE_PRECHARGE" 1 "PCS_PH_STATE_IDLE" 0 "PCS_PH_STATE_INIT" ;
VAL_ 708 PCS_chgPhALastShutdownReason 17 "PCS_PH_SHUTDOWN_LINE_TRANSIENT_FAULT" 16 "PCS_PH_SHUTDOWN_FREQ_OUT_OF_RANGE" 15 "PCS_PH_SHUTDOWN_SENSOR_IRRATIONAL" 14 "PCS_PH_SHUTDOWN_TEMP_IRRATIONAL" 13 "PCS_PH_SHUTDOWN_OVER_TEMPERATURE" 12 "PCS_PH_SHUTDOWN_CONTROL_REGULATION_FAULT" 11 "PCS_PH_SHUTDOWN_INT_BUS_UV" 10 "PCS_PH_SHUTDOWN_PRECHARGE_TIMEOUT" 9 "PCS_PH_SHUTDOWN_OUTPUT_OV" 8 "PCS_PH_SHUTDOWN_OUTPUT_UV" 7 "PCS_PH_SHUTDOWN_INPUT_OV" 6 "PCS_PH_SHUTDOWN_INPUT_UV" 5 "PCS_PH_SHUTDOWN_PLL_NOT_LOCKED" 4 "PCS_PH_SHUTDOWN_HW_FAULT" 3 "PCS_PH_SHUTDOWN_SW_FAULT" 2 "PCS_PH_SHUTDOWN_HW_ENABLE" 1 "PCS_PH_SHUTDOWN_SW_ENABLE" 0 "PCS_PH_SHUTDOWN_REASON_NONE" ;
VAL_ 708 PCS_chgPhBLastShutdownReason 17 "PCS_PH_SHUTDOWN_LINE_TRANSIENT_FAULT" 16 "PCS_PH_SHUTDOWN_FREQ_OUT_OF_RANGE" 15 "PCS_PH_SHUTDOWN_SENSOR_IRRATIONAL" 14 "PCS_PH_SHUTDOWN_TEMP_IRRATIONAL" 13 "PCS_PH_SHUTDOWN_OVER_TEMPERATURE" 12 "PCS_PH_SHUTDOWN_CONTROL_REGULATION_FAULT" 11 "PCS_PH_SHUTDOWN_INT_BUS_UV" 10 "PCS_PH_SHUTDOWN_PRECHARGE_TIMEOUT" 9 "PCS_PH_SHUTDOWN_OUTPUT_OV" 8 "PCS_PH_SHUTDOWN_OUTPUT_UV" 7 "PCS_PH_SHUTDOWN_INPUT_OV" 6 "PCS_PH_SHUTDOWN_INPUT_UV" 5 "PCS_PH_SHUTDOWN_PLL_NOT_LOCKED" 4 "PCS_PH_SHUTDOWN_HW_FAULT" 3 "PCS_PH_SHUTDOWN_SW_FAULT" 2 "PCS_PH_SHUTDOWN_HW_ENABLE" 1 "PCS_PH_SHUTDOWN_SW_ENABLE" 0 "PCS_PH_SHUTDOWN_REASON_NONE" ;
VAL_ 708 PCS_chgPhCLastShutdownReason 17 "PCS_PH_SHUTDOWN_LINE_TRANSIENT_FAULT" 16 "PCS_PH_SHUTDOWN_FREQ_OUT_OF_RANGE" 15 "PCS_PH_SHUTDOWN_SENSOR_IRRATIONAL" 14 "PCS_PH_SHUTDOWN_TEMP_IRRATIONAL" 13 "PCS_PH_SHUTDOWN_OVER_TEMPERATURE" 12 "PCS_PH_SHUTDOWN_CONTROL_REGULATION_FAULT" 11 "PCS_PH_SHUTDOWN_INT_BUS_UV" 10 "PCS_PH_SHUTDOWN_PRECHARGE_TIMEOUT" 9 "PCS_PH_SHUTDOWN_OUTPUT_OV" 8 "PCS_PH_SHUTDOWN_OUTPUT_UV" 7 "PCS_PH_SHUTDOWN_INPUT_OV" 6 "PCS_PH_SHUTDOWN_INPUT_UV" 5 "PCS_PH_SHUTDOWN_PLL_NOT_LOCKED" 4 "PCS_PH_SHUTDOWN_HW_FAULT" 3 "PCS_PH_SHUTDOWN_SW_FAULT" 2 "PCS_PH_SHUTDOWN_HW_ENABLE" 1 "PCS_PH_SHUTDOWN_SW_ENABLE" 0 "PCS_PH_SHUTDOWN_REASON_NONE" ;
VAL_ 708 PCS_cpu2BootState 3 "CPU2_STATE_ERROR" 2 "CPU2_STATE_APPLICATION" 1 "CPU2_STATE_BOOTLOADER" 0 "CPU2_STATE_BOOTROM" ;
VAL_ 708 PCS_acChargeSelfTestState 1 "PCS_SELF_TEST_STARTED" 0 "PCS_SELF_TEST_IDLE" ;
VAL_ 708 PCS_chgAcpwHeartbeatState 4 "PCS_ACPW_HEARTBEAT_STATE_NUM" 3 "PCS_ACPW_HEARTBEAT_STATE_DETECTED_ONGRID" 2 "PCS_ACPW_HEARTBEAT_STATE_DETECTED_OFFGRID" 1 "PCS_ACPW_HEARTBEAT_STATE_NOT_DETECTED" 0 "PCS_ACPW_HEARTBEAT_STATE_UNKNOWN" ;
VAL_ 790 PMF_buildType 4 "INFO_MFG_BUILD" 3 "INFO_TRACEABLE_CI_BUILD" 2 "INFO_LOCAL_BUILD" 1 "INFO_PLATFORM_BUILD" 0 "INFO_UNKNOWN_BUILD" ;
VAL_ 1748 PMR_buildType 4 "INFO_MFG_BUILD" 3 "INFO_TRACEABLE_CI_BUILD" 2 "INFO_LOCAL_BUILD" 1 "INFO_PLATFORM_BUILD" 0 "INFO_UNKNOWN_BUILD" ;
VAL_ 2020 PM_buildType 4 "INFO_MFG_BUILD" 3 "INFO_TRACEABLE_CI_BUILD" 2 "INFO_LOCAL_BUILD" 1 "INFO_PLATFORM_BUILD" 0 "INFO_UNKNOWN_BUILD" ;
VAL_ 463 PM_hvilSystemStatus 2 "CLOSED" 1 "OPEN" 0 "DISABLED" ;
VAL_ 519 PTC_leftPowerDerating 3 "OVERTEMPERATURE_CORE" 2 "OVERTEMPERATURE_IGBT" 1 "OVERTEMPERATURE_PCB" 0 "NOT_DERATED" ;
VAL_ 519 PTC_rightPowerDerating 3 "OVERTEMPERATURE_CORE" 2 "OVERTEMPERATURE_IGBT" 1 "OVERTEMPERATURE_PCB" 0 "NOT_DERATED" ;
VAL_ 519 PTC_ocpEvent 2 "OCP_EVENT_RIGHT_SIDE" 1 "OCP_EVENT_LEFT_SIDE" 0 "NO_OCP_EVENT" ;
VAL_ 519 PTC_tliSource 4 "HV_OVER_VOLTAGE" 3 "OCP" 2 "12_VOLTS" 1 "IGBT_DRIVER" 0 "NO_ERROR" ;
VAL_ 837 PTC_infoBuildType 4 "INFO_MFG_BUILD" 3 "INFO_TRACEABLE_CI_BUILD" 2 "INFO_LOCAL_BUILD" 1 "INFO_PLATFORM_BUILD" 0 "INFO_UNKNOWN_BUILD" ;
